VERSION ""

NS_ :

BS_:

BU_: WPC2 PSB SHVU_RR FCS vHS_B2 EMCU SLB GW_APSU GW_DLBCU RCM ARS CGW_CCU vDummy_HS_B GW_RLPSU ATS RLHV SGU PFSU GW_RRPSU ALBCU DSAU SWRC SHVU_FR RCS GW_DPSU BLTN_CAM SCM OHCL RWPC RRHV WPC HOD ASAU

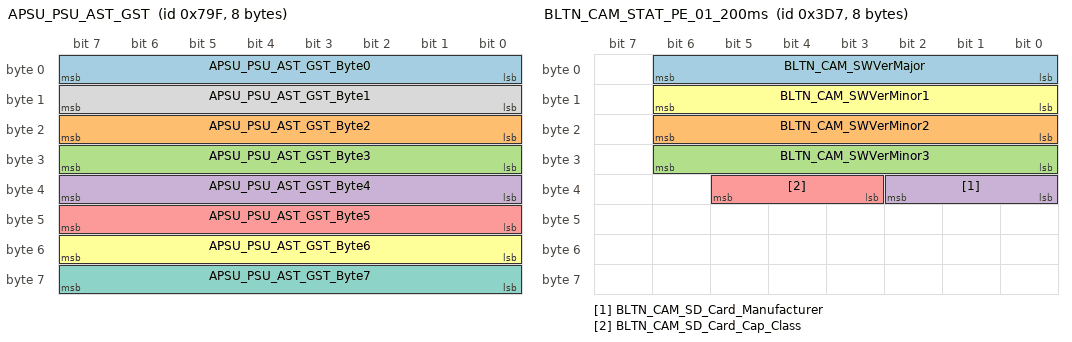
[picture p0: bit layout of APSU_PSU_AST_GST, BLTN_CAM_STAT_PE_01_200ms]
BO_ 1951 APSU_PSU_AST_GST: 8 GW_APSU
 SG_ APSU_PSU_AST_GST_Byte0 : 0|8@1+ (1,0) [0|0] ""  CGW_CCU
 SG_ APSU_PSU_AST_GST_Byte2 : 16|8@1+ (1,0) [0|0] ""  CGW_CCU
 SG_ APSU_PSU_AST_GST_Byte3 : 24|8@1+ (1,0) [0|0] ""  CGW_CCU
 SG_ APSU_PSU_AST_GST_Byte4 : 32|8@1+ (1,0) [0|0] ""  CGW_CCU
 SG_ APSU_PSU_AST_GST_Byte5 : 40|8@1+ (1,0) [0|0] ""  CGW_CCU
 SG_ APSU_PSU_AST_GST_Byte6 : 48|8@1+ (1,0) [0|0] ""  CGW_CCU
 SG_ APSU_PSU_AST_GST_Byte7 : 56|8@1+ (1,0) [0|0] ""  CGW_CCU
 SG_ APSU_PSU_AST_GST_Byte1 : 8|8@1+ (1,0) [0|0] ""  CGW_CCU

BO_ 977 SMK_13_200ms: 8 CGW_CCU
 SG_ SMK_Crc13Val : 0|8@1+ (1,0) [0|0] "0" Vector__XXX
 SG_ SMK_TlPwrOnSta : 10|2@1+ (1,0) [0|0] "" Vector__XXX
 SG_ SMK_AlvCnt13Val : 12|4@1+ (1,0) [0|0] "0" Vector__XXX
 SG_ SMK_TrmnlCtrlGrpStaBDC : 16|3@1+ (1,0) [0|0] ""  BLTN_CAM
 SG_ SMK_TrmnlCtrlStaBDC : 19|5@1+ (1,0) [0|0] "" Vector__XXX
 SG_ SMK_TrmnlCtrlGrpStaBDCEV : 24|3@1+ (1,0) [0|0] ""  BLTN_CAM
 SG_ SMK_TrmnlCtrlStaBDCEV : 27|5@1+ (1,0) [0|0] ""  BLTN_CAM
 SG_ SMK_PwrOnModeSta : 32|2@1+ (1,0) [0|0] "" Vector__XXX
 SG_ SMK_StndbyMdTmrMin : 34|6@1+ (1,0) [0|0] "" Vector__XXX
 SG_ SMK_StndbyMdTmrSec : 40|6@1+ (1,0) [0|0] "" Vector__XXX
 SG_ SMK_EVPwrOffReq : 46|2@1+ (1,0) [0|0] "" Vector__XXX
 SG_ SMK_RLHndLkSnsrSta : 48|2@1+ (1,0) [0|0] "" Vector__XXX
 SG_ SMK_RLDrHndUnLkSnsrSta : 50|2@1+ (1,0) [0|0] "" Vector__XXX
 SG_ SMK_RRDrHndLkSnsrSta : 52|2@1+ (1,0) [0|0] "" Vector__XXX
 SG_ SMK_RRDrHndUnLkSnsrSta : 54|2@1+ (1,0) [0|0] "" Vector__XXX
 SG_ SMK_MaintenanceSrvMdReq : 56|2@1+ (1,0) [0|0] "" Vector__XXX
 SG_ Auth_ISKLearnSta2 : 58|3@1+ (1,0) [0|0] "" Vector__XXX
 SG_ Fob_FoundForChargingDoor : 61|2@1+ (1,0) [0|0] "" Vector__XXX
 SG_ Fob_FoundCabinArea : 8|2@1+ (1,0) [0|0] "" Vector__XXX

BO_ 983 BLTN_CAM_STAT_PE_01_200ms: 8 BLTN_CAM
 SG_ BLTN_CAM_SWVerMajor : 0|7@1+ (1,0) [0|0] ""  CGW_CCU
 SG_ BLTN_CAM_SWVerMinor2 : 16|7@1+ (1,0) [0|0] ""  CGW_CCU
 SG_ BLTN_CAM_SWVerMinor3 : 24|7@1+ (1,0) [0|0] ""  CGW_CCU
 SG_ BLTN_CAM_SD_Card_Manufacturer : 32|3@1+ (1,0) [0|0] ""  CGW_CCU
 SG_ BLTN_CAM_SD_Card_Cap_Class : 35|3@1+ (1,1) [0|0] ""  CGW_CCU
 SG_ BLTN_CAM_SWVerMinor1 : 8|7@1+ (1,0) [0|0] ""  CGW_CCU

BO_ 981 APSS_01_200ms: 8 GW_APSU
 SG_ APSS_StExtFwdMvBtn : 0|2@1+ (1,0) [0|0] "" Vector__XXX
 SG_ APSS_StSldFwdMvBtn : 16|2@1+ (1,0) [0|0] ""  CGW_CCU
 SG_ APSS_StSldBwdMvBtn : 18|2@1+ (1,0) [0|0] ""  CGW_CCU
 SG_ APSS_StExtBwdMvBtn : 2|2@1+ (1,0) [0|0] "" Vector__XXX
 SG_ APSS_StRclFwdMvBtn : 20|2@1+ (1,0) [0|0] ""  CGW_CCU
 SG_ APSS_StRclBwdMvBtn : 22|2@1+ (1,0) [0|0] ""  CGW_CCU
 SG_ APSS_StHgtUpMvBtn : 24|2@1+ (1,0) [0|0] ""  CGW_CCU
 SG_ APSS_StHgtDnMvBtn : 26|2@1+ (1,0) [0|0] ""  CGW_CCU
 SG_ APSS_StTltUpMvBtn : 28|2@1+ (1,0) [0|0] ""  CGW_CCU
 SG_ APSS_StTltDnMvBtn : 30|2@1+ (1,0) [0|0] ""  CGW_CCU
 SG_ APSS_StHRestUpMvBtn : 32|2@1+ (1,0) [0|0] ""  CGW_CCU
 SG_ APSS_StHRestDnMvBtn : 34|2@1+ (1,0) [0|0] ""  CGW_CCU
 SG_ APSS_StHRestFwdMvBtn : 36|2@1+ (1,0) [0|0] ""  CGW_CCU
 SG_ APSS_StHRestBwdMvBtn : 38|2@1+ (1,0) [0|0] ""  CGW_CCU
 SG_ APSS_StLegUpMvBtn : 40|2@1+ (1,0) [0|0] "" Vector__XXX
 SG_ APSS_StLegDnMvBtn : 42|2@1+ (1,0) [0|0] "" Vector__XXX
 SG_ APSS_StRlxModeBtn : 44|2@1+ (1,0) [0|0] "" Vector__XXX
 SG_ APSS_StRlxReturnBtn : 46|2@1+ (1,0) [0|0] "" Vector__XXX
 SG_ APSS_StRlxTltUpMvBtn : 48|2@1+ (1,0) [0|0] "" Vector__XXX
 SG_ APSS_StRlxTltDnMvBtn : 50|2@1+ (1,0) [0|0] "" Vector__XXX
 SG_ APSS_StAutoModeEnable : 52|2@1+ (1,0) [0|0] "" Vector__XXX

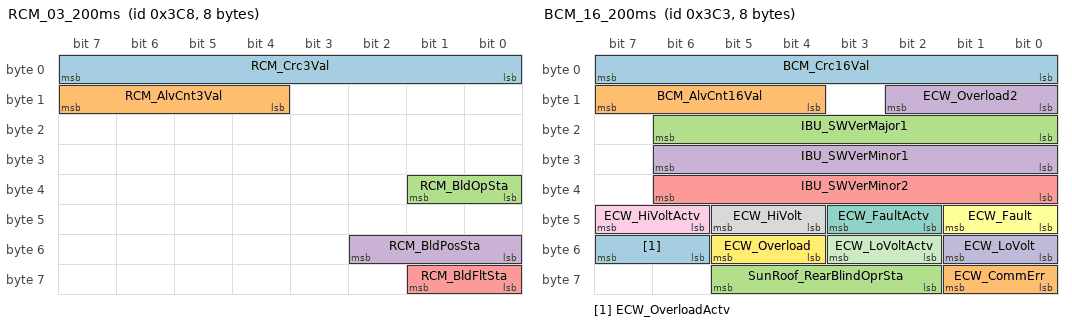
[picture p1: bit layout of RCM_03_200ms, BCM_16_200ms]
BO_ 968 RCM_03_200ms: 8 RCM
 SG_ RCM_Crc3Val : 0|8@1+ (1,0) [0|0] "" Vector__XXX
 SG_ RCM_AlvCnt3Val : 12|4@1+ (1,0) [0|0] "" Vector__XXX
 SG_ RCM_BldOpSta : 32|2@1+ (1,0) [0|0] "" Vector__XXX
 SG_ RCM_BldPosSta : 48|3@1+ (1,0) [0|0] ""  CGW_CCU,SGU
 SG_ RCM_BldFltSta : 56|2@1+ (1,0) [0|0] ""  CGW_CCU

BO_ 963 BCM_16_200ms: 8 CGW_CCU
 SG_ BCM_Crc16Val : 0|8@1+ (1,0) [0|0] "" Vector__XXX
 SG_ BCM_AlvCnt16Val : 12|4@1+ (1,0) [0|0] "" Vector__XXX
 SG_ IBU_SWVerMajor1 : 16|7@1+ (1,0) [0|0] "" Vector__XXX
 SG_ IBU_SWVerMinor1 : 24|7@1+ (1,0) [0|0] "" Vector__XXX
 SG_ IBU_SWVerMinor2 : 32|7@1+ (1,0) [0|0] "" Vector__XXX
 SG_ ECW_Fault : 40|2@1+ (1,0) [0|0] "" Vector__XXX
 SG_ ECW_FaultActv : 42|2@1+ (1,0) [0|0] "" Vector__XXX
 SG_ ECW_HiVolt : 44|2@1+ (1,0) [0|0] "" Vector__XXX
 SG_ ECW_HiVoltActv : 46|2@1+ (1,0) [0|0] "" Vector__XXX
 SG_ ECW_LoVolt : 48|2@1+ (1,0) [0|0] "" Vector__XXX
 SG_ ECW_LoVoltActv : 50|2@1+ (1,0) [0|0] "" Vector__XXX
 SG_ ECW_Overload : 52|2@1+ (1,0) [0|0] "" Vector__XXX
 SG_ ECW_OverloadActv : 54|2@1+ (1,0) [0|0] "" Vector__XXX
 SG_ ECW_CommErr : 56|2@1+ (1,0) [0|0] "" Vector__XXX
 SG_ SunRoof_RearBlindOprSta : 58|4@1+ (1,0) [0|0] ""  ATS
 SG_ ECW_Overload2 : 8|3@1+ (1,0) [0|0] "" Vector__XXX

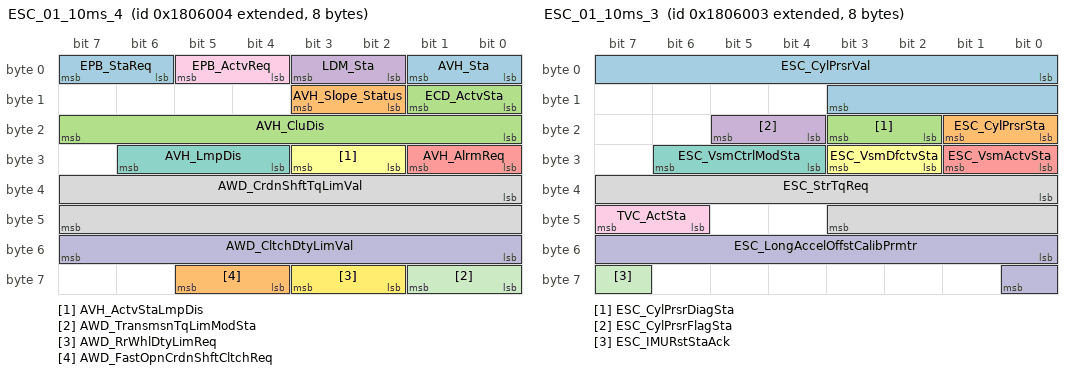
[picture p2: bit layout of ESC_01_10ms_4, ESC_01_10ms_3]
BO_ 2172674052 ESC_01_10ms_4: 8 CGW_CCU
 SG_ AVH_Sta : 0|2@1+ (1,0) [0|0] "" Vector__XXX
 SG_ AVH_Slope_Status : 10|2@1+ (1,0) [0|0] "" Vector__XXX
 SG_ AVH_CluDis : 16|8@1+ (1,0) [0|0] "" Vector__XXX
 SG_ LDM_Sta : 2|2@1+ (1,0) [0|0] "" Vector__XXX
 SG_ AVH_AlrmReq : 24|2@1+ (1,0) [0|0] "" Vector__XXX
 SG_ AVH_ActvStaLmpDis : 26|2@1+ (1,0) [0|0] "" Vector__XXX
 SG_ AVH_LmpDis : 28|3@1+ (1,0) [0|0] "" Vector__XXX
 SG_ AWD_CrdnShftTqLimVal : 32|16@1+ (1,0) [0|0] "Nm" Vector__XXX
 SG_ EPB_ActvReq : 4|2@1+ (1,0) [0|0] "" Vector__XXX
 SG_ AWD_CltchDtyLimVal : 48|8@1+ (0.390625,0) [0|0] "%" Vector__XXX
 SG_ AWD_TransmsnTqLimModSta : 56|2@1+ (1,0) [0|0] "" Vector__XXX
 SG_ AWD_RrWhlDtyLimReq : 58|2@1+ (1,0) [0|0] "" Vector__XXX
 SG_ EPB_StaReq : 6|2@1+ (1,0) [0|0] "" Vector__XXX
 SG_ AWD_FastOpnCrdnShftCltchReq : 60|2@1+ (1,0) [0|0] "" Vector__XXX
 SG_ ECD_ActvSta : 8|2@1+ (1,0) [0|0] "" Vector__XXX

BO_ 2172674051 ESC_01_10ms_3: 8 CGW_CCU
 SG_ ESC_CylPrsrVal : 0|12@1+ (0.1,0) [0|0] "Bar"  PSB
 SG_ ESC_CylPrsrSta : 16|2@1+ (1,0) [0|0] ""  PSB
 SG_ ESC_CylPrsrDiagSta : 18|2@1+ (1,0) [0|0] "" Vector__XXX
 SG_ ESC_CylPrsrFlagSta : 20|2@1+ (1,0) [0|0] "" Vector__XXX
 SG_ ESC_VsmActvSta : 24|2@1+ (1,0) [0|0] "" Vector__XXX
 SG_ ESC_VsmDfctvSta : 26|2@1+ (1,0) [0|0] "" Vector__XXX
 SG_ ESC_VsmCtrlModSta : 28|3@1+ (1,0) [0|0] "" Vector__XXX
 SG_ ESC_StrTqReq : 32|12@1+ (0.01,-20.48) [0|0] "Nm" Vector__XXX
 SG_ TVC_ActSta : 46|2@1+ (1,0) [0|0] "" Vector__XXX
 SG_ ESC_LongAccelOffstCalibPrmtr : 48|9@1+ (0.001,-0.255) [0|0] "g" Vector__XXX
 SG_ ESC_IMURstStaAck : 63|1@1+ (1,0) [0|0] "" Vector__XXX

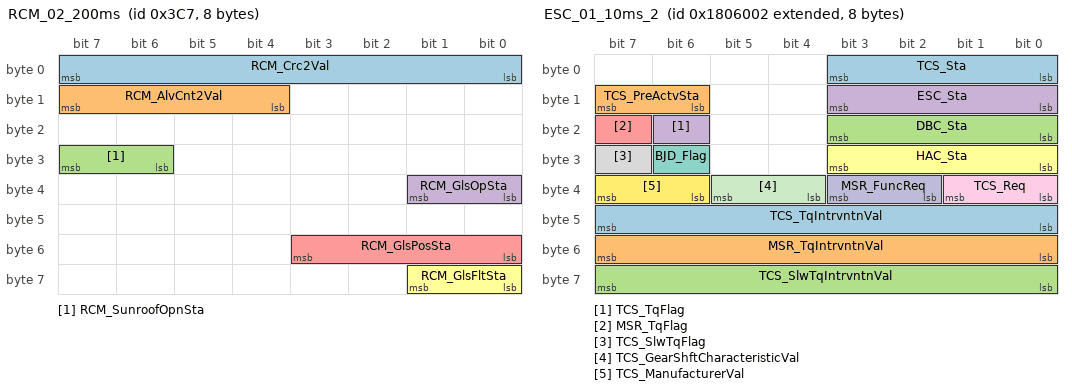
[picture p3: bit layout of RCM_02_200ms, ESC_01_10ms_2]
BO_ 967 RCM_02_200ms: 8 RCM
 SG_ RCM_Crc2Val : 0|8@1+ (1,0) [0|0] "" Vector__XXX
 SG_ RCM_AlvCnt2Val : 12|4@1+ (1,0) [0|0] "" Vector__XXX
 SG_ RCM_SunroofOpnSta : 30|2@1+ (1,0) [0|0] ""  CGW_CCU
 SG_ RCM_GlsOpSta : 32|2@1+ (1,0) [0|0] ""  CGW_CCU
 SG_ RCM_GlsPosSta : 48|4@1+ (1,0) [0|0] ""  CGW_CCU
 SG_ RCM_GlsFltSta : 56|2@1+ (1,0) [0|0] ""  CGW_CCU

BO_ 2172674050 ESC_01_10ms_2: 8 CGW_CCU
 SG_ TCS_Sta : 0|4@1+ (1,0) [0|0] "" Vector__XXX
 SG_ TCS_PreActvSta : 14|2@1+ (1,0) [0|0] "" Vector__XXX
 SG_ DBC_Sta : 16|4@1+ (1,0) [0|0] "" Vector__XXX
 SG_ TCS_TqFlag : 22|1@1+ (1,0) [0|0] "" Vector__XXX
 SG_ MSR_TqFlag : 23|1@1+ (1,0) [0|0] "" Vector__XXX
 SG_ HAC_Sta : 24|4@1+ (1,0) [0|0] "" Vector__XXX
 SG_ BJD_Flag : 30|1@1+ (1,0) [0|0] "" Vector__XXX
 SG_ TCS_SlwTqFlag : 31|1@1+ (1,0) [0|0] "" Vector__XXX
 SG_ TCS_Req : 32|2@1+ (1,0) [0|0] "" Vector__XXX
 SG_ MSR_FuncReq : 34|2@1+ (1,0) [0|0] "" Vector__XXX
 SG_ TCS_GearShftCharacteristicVal : 36|2@1+ (1,0) [0|0] "" Vector__XXX
 SG_ TCS_ManufacturerVal : 38|2@1+ (1,0) [0|0] "" Vector__XXX
 SG_ TCS_TqIntrvntnVal : 40|8@1+ (0.390625,0) [0|0] "%" Vector__XXX
 SG_ MSR_TqIntrvntnVal : 48|8@1+ (0.390625,0) [0|0] "%" Vector__XXX
 SG_ TCS_SlwTqIntrvntnVal : 56|8@1+ (0.390625,0) [0|0] "%" Vector__XXX
 SG_ ESC_Sta : 8|4@1+ (1,0) [0|0] "" Vector__XXX

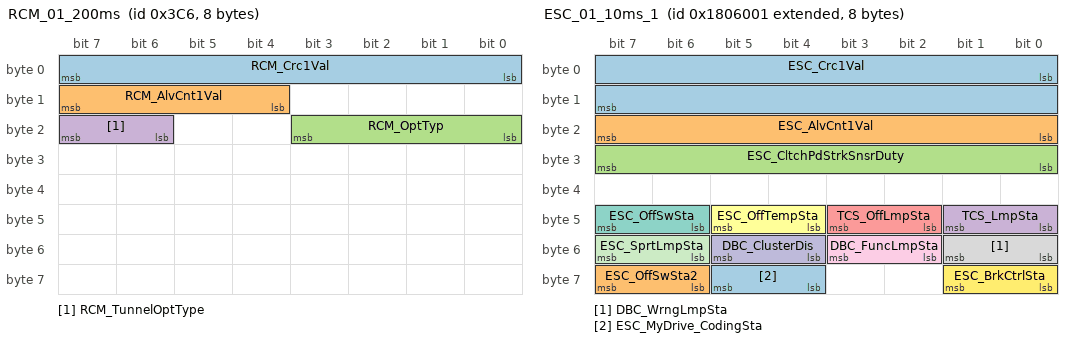
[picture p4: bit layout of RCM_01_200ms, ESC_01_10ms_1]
BO_ 966 RCM_01_200ms: 8 RCM
 SG_ RCM_Crc1Val : 0|8@1+ (1,0) [0|0] "" Vector__XXX
 SG_ RCM_AlvCnt1Val : 12|4@1+ (1,0) [0|0] "" Vector__XXX
 SG_ RCM_OptTyp : 16|4@1+ (1,0) [0|0] ""  CGW_CCU
 SG_ RCM_TunnelOptType : 22|2@1+ (1,0) [0|0] ""  CGW_CCU

BO_ 2172674049 ESC_01_10ms_1: 8 CGW_CCU
 SG_ ESC_Crc1Val : 0|16@1+ (1,0) [0|0] "" Vector__XXX
 SG_ ESC_AlvCnt1Val : 16|8@1+ (1,0) [0|0] "" Vector__XXX
 SG_ ESC_CltchPdStrkSnsrDuty : 24|8@1+ (1,0) [0|0] "%" Vector__XXX
 SG_ TCS_LmpSta : 40|2@1+ (1,0) [0|0] "" Vector__XXX
 SG_ TCS_OffLmpSta : 42|2@1+ (1,0) [0|0] "" Vector__XXX
 SG_ ESC_OffTempSta : 44|2@1+ (1,0) [0|0] "" Vector__XXX
 SG_ ESC_OffSwSta : 46|2@1+ (1,0) [0|0] "" Vector__XXX
 SG_ DBC_WrngLmpSta : 48|2@1+ (1,0) [0|0] "" Vector__XXX
 SG_ DBC_FuncLmpSta : 50|2@1+ (1,0) [0|0] "" Vector__XXX
 SG_ DBC_ClusterDis : 52|2@1+ (1,0) [0|0] "" Vector__XXX
 SG_ ESC_SprtLmpSta : 54|2@1+ (1,0) [0|0] "" Vector__XXX
 SG_ ESC_BrkCtrlSta : 56|2@1+ (1,0) [0|0] "" Vector__XXX
 SG_ ESC_MyDrive_CodingSta : 60|2@1+ (1,0) [0|0] "" Vector__XXX
 SG_ ESC_OffSwSta2 : 62|2@1+ (1,0) [0|0] "" Vector__XXX

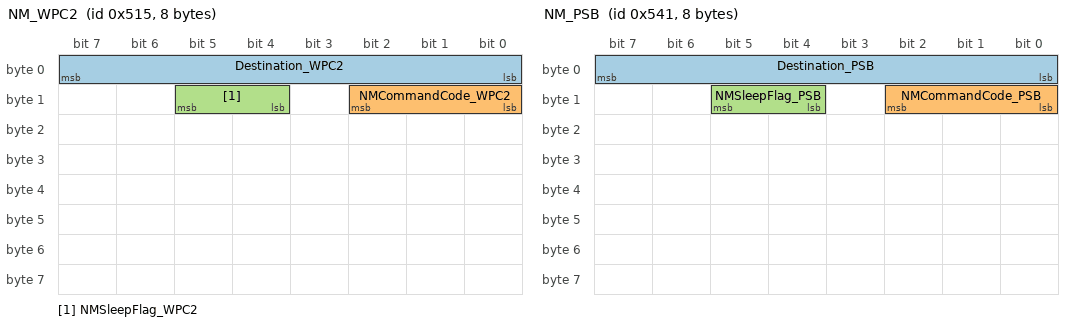
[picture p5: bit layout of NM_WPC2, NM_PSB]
BO_ 1301 NM_WPC2: 8 WPC2
 SG_ Destination_WPC2 : 0|8@1+ (1,0) [0|0] ""  PSB,SHVU_RR,FCS,vHS_B2,EMCU,SLB,GW_APSU,GW_DLBCU,RCM,ARS,CGW_CCU,vDummy_HS_B,GW_RLPSU,ATS,RLHV,SGU,PFSU,GW_RRPSU,ALBCU,DSAU,SWRC,SHVU_FR,RCS,GW_DPSU,BLTN_CAM,SCM,OHCL,RWPC,RRHV,WPC,HOD,ASAU
 SG_ NMCommandCode_WPC2 : 8|3@1+ (1,0) [0|0] ""  PSB,SHVU_RR,FCS,vHS_B2,EMCU,SLB,GW_APSU,GW_DLBCU,RCM,ARS,CGW_CCU,vDummy_HS_B,GW_RLPSU,ATS,RLHV,SGU,PFSU,GW_RRPSU,ALBCU,DSAU,SWRC,SHVU_FR,RCS,GW_DPSU,BLTN_CAM,SCM,OHCL,RWPC,RRHV,WPC,HOD,ASAU
 SG_ NMSleepFlag_WPC2 : 12|2@1+ (1,0) [0|0] ""  PSB,SHVU_RR,FCS,vHS_B2,EMCU,SLB,GW_APSU,GW_DLBCU,RCM,ARS,CGW_CCU,vDummy_HS_B,GW_RLPSU,ATS,RLHV,SGU,PFSU,GW_RRPSU,ALBCU,DSAU,SWRC,SHVU_FR,RCS,GW_DPSU,BLTN_CAM,SCM,OHCL,RWPC,RRHV,WPC,HOD,ASAU

BO_ 1345 NM_PSB: 8 PSB
 SG_ Destination_PSB : 0|8@1+ (1,0) [0|0] ""  WPC2,SHVU_RR,FCS,vHS_B2,EMCU,SLB,GW_APSU,GW_DLBCU,RCM,ARS,CGW_CCU,vDummy_HS_B,GW_RLPSU,ATS,RLHV,SGU,PFSU,GW_RRPSU,ALBCU,DSAU,SWRC,SHVU_FR,RCS,GW_DPSU,BLTN_CAM,SCM,OHCL,RWPC,RRHV,WPC,HOD,ASAU
 SG_ NMCommandCode_PSB : 8|3@1+ (1,0) [0|0] ""  WPC2,SHVU_RR,FCS,vHS_B2,EMCU,SLB,GW_APSU,GW_DLBCU,RCM,ARS,CGW_CCU,vDummy_HS_B,GW_RLPSU,ATS,RLHV,SGU,PFSU,GW_RRPSU,ALBCU,DSAU,SWRC,SHVU_FR,RCS,GW_DPSU,BLTN_CAM,SCM,OHCL,RWPC,RRHV,WPC,HOD,ASAU
 SG_ NMSleepFlag_PSB : 12|2@1+ (1,0) [0|0] ""  WPC2,SHVU_RR,FCS,vHS_B2,EMCU,SLB,GW_APSU,GW_DLBCU,RCM,ARS,CGW_CCU,vDummy_HS_B,GW_RLPSU,ATS,RLHV,SGU,PFSU,GW_RRPSU,ALBCU,DSAU,SWRC,SHVU_FR,RCS,GW_DPSU,BLTN_CAM,SCM,OHCL,RWPC,RRHV,WPC,HOD,ASAU

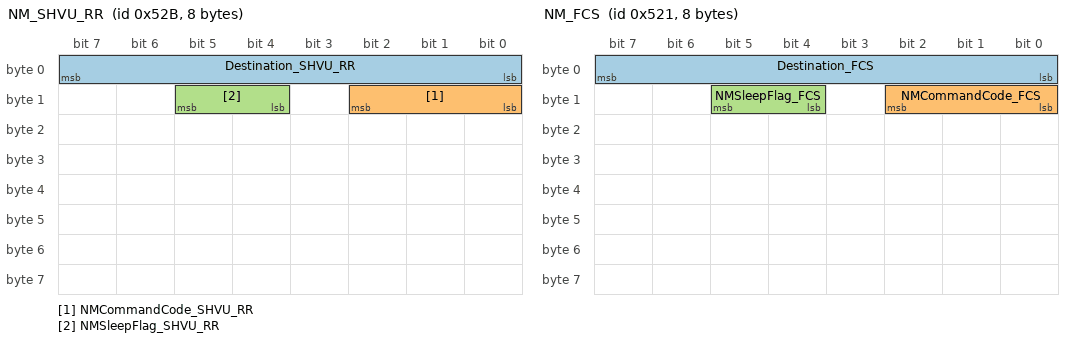
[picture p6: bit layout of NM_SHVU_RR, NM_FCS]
BO_ 1323 NM_SHVU_RR: 8 SHVU_RR
 SG_ Destination_SHVU_RR : 0|8@1+ (1,0) [0|0] ""  WPC2,PSB,FCS,vHS_B2,EMCU,SLB,GW_APSU,GW_DLBCU,RCM,ARS,CGW_CCU,vDummy_HS_B,GW_RLPSU,ATS,RLHV,SGU,PFSU,GW_RRPSU,ALBCU,DSAU,SWRC,SHVU_FR,RCS,GW_DPSU,BLTN_CAM,SCM,OHCL,RWPC,RRHV,WPC,HOD,ASAU
 SG_ NMCommandCode_SHVU_RR : 8|3@1+ (1,0) [0|0] ""  WPC2,PSB,FCS,vHS_B2,EMCU,SLB,GW_APSU,GW_DLBCU,RCM,ARS,CGW_CCU,vDummy_HS_B,GW_RLPSU,ATS,RLHV,SGU,PFSU,GW_RRPSU,ALBCU,DSAU,SWRC,SHVU_FR,RCS,GW_DPSU,BLTN_CAM,SCM,OHCL,RWPC,RRHV,WPC,HOD,ASAU
 SG_ NMSleepFlag_SHVU_RR : 12|2@1+ (1,0) [0|0] ""  WPC2,PSB,FCS,vHS_B2,EMCU,SLB,GW_APSU,GW_DLBCU,RCM,ARS,CGW_CCU,vDummy_HS_B,GW_RLPSU,ATS,RLHV,SGU,PFSU,GW_RRPSU,ALBCU,DSAU,SWRC,SHVU_FR,RCS,GW_DPSU,BLTN_CAM,SCM,OHCL,RWPC,RRHV,WPC,HOD,ASAU

BO_ 1313 NM_FCS: 8 FCS
 SG_ Destination_FCS : 0|8@1+ (1,0) [0|0] ""  WPC2,PSB,SHVU_RR,vHS_B2,EMCU,SLB,GW_APSU,GW_DLBCU,RCM,ARS,CGW_CCU,vDummy_HS_B,GW_RLPSU,ATS,RLHV,SGU,PFSU,GW_RRPSU,ALBCU,DSAU,SWRC,SHVU_FR,RCS,GW_DPSU,BLTN_CAM,SCM,OHCL,RWPC,RRHV,WPC,HOD,ASAU
 SG_ NMCommandCode_FCS : 8|3@1+ (1,0) [0|0] ""  WPC2,PSB,SHVU_RR,vHS_B2,EMCU,SLB,GW_APSU,GW_DLBCU,RCM,ARS,CGW_CCU,vDummy_HS_B,GW_RLPSU,ATS,RLHV,SGU,PFSU,GW_RRPSU,ALBCU,DSAU,SWRC,SHVU_FR,RCS,GW_DPSU,BLTN_CAM,SCM,OHCL,RWPC,RRHV,WPC,HOD,ASAU
 SG_ NMSleepFlag_FCS : 12|2@1+ (1,0) [0|0] ""  WPC2,PSB,SHVU_RR,vHS_B2,EMCU,SLB,GW_APSU,GW_DLBCU,RCM,ARS,CGW_CCU,vDummy_HS_B,GW_RLPSU,ATS,RLHV,SGU,PFSU,GW_RRPSU,ALBCU,DSAU,SWRC,SHVU_FR,RCS,GW_DPSU,BLTN_CAM,SCM,OHCL,RWPC,RRHV,WPC,HOD,ASAU

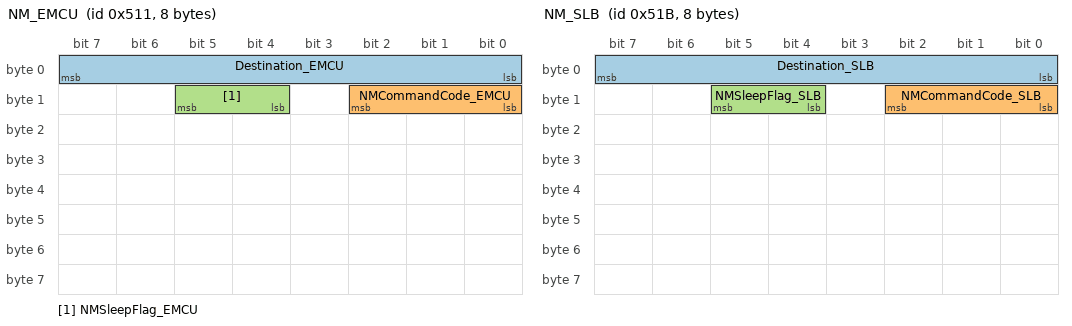
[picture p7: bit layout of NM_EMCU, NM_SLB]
BO_ 1297 NM_EMCU: 8 EMCU
 SG_ Destination_EMCU : 0|8@1+ (1,0) [0|0] ""  WPC2,PSB,SHVU_RR,FCS,vHS_B2,SLB,GW_APSU,GW_DLBCU,RCM,ARS,CGW_CCU,vDummy_HS_B,GW_RLPSU,ATS,RLHV,SGU,PFSU,GW_RRPSU,ALBCU,DSAU,SWRC,SHVU_FR,RCS,GW_DPSU,BLTN_CAM,SCM,OHCL,RWPC,RRHV,WPC,HOD,ASAU
 SG_ NMCommandCode_EMCU : 8|3@1+ (1,0) [0|0] ""  WPC2,PSB,SHVU_RR,FCS,vHS_B2,SLB,GW_APSU,GW_DLBCU,RCM,ARS,CGW_CCU,vDummy_HS_B,GW_RLPSU,ATS,RLHV,SGU,PFSU,GW_RRPSU,ALBCU,DSAU,SWRC,SHVU_FR,RCS,GW_DPSU,BLTN_CAM,SCM,OHCL,RWPC,RRHV,WPC,HOD,ASAU
 SG_ NMSleepFlag_EMCU : 12|2@1+ (1,0) [0|0] ""  WPC2,PSB,SHVU_RR,FCS,vHS_B2,SLB,GW_APSU,GW_DLBCU,RCM,ARS,CGW_CCU,vDummy_HS_B,GW_RLPSU,ATS,RLHV,SGU,PFSU,GW_RRPSU,ALBCU,DSAU,SWRC,SHVU_FR,RCS,GW_DPSU,BLTN_CAM,SCM,OHCL,RWPC,RRHV,WPC,HOD,ASAU

BO_ 1307 NM_SLB: 8 SLB
 SG_ Destination_SLB : 0|8@1+ (1,0) [0|0] ""  WPC2,PSB,SHVU_RR,FCS,vHS_B2,EMCU,GW_APSU,GW_DLBCU,RCM,ARS,CGW_CCU,vDummy_HS_B,GW_RLPSU,ATS,RLHV,SGU,PFSU,GW_RRPSU,ALBCU,DSAU,SWRC,SHVU_FR,RCS,GW_DPSU,BLTN_CAM,SCM,OHCL,RWPC,RRHV,WPC,HOD,ASAU
 SG_ NMCommandCode_SLB : 8|3@1+ (1,0) [0|0] ""  WPC2,PSB,SHVU_RR,FCS,vHS_B2,EMCU,GW_APSU,GW_DLBCU,RCM,ARS,CGW_CCU,vDummy_HS_B,GW_RLPSU,ATS,RLHV,SGU,PFSU,GW_RRPSU,ALBCU,DSAU,SWRC,SHVU_FR,RCS,GW_DPSU,BLTN_CAM,SCM,OHCL,RWPC,RRHV,WPC,HOD,ASAU
 SG_ NMSleepFlag_SLB : 12|2@1+ (1,0) [0|0] ""  WPC2,PSB,SHVU_RR,FCS,vHS_B2,EMCU,GW_APSU,GW_DLBCU,RCM,ARS,CGW_CCU,vDummy_HS_B,GW_RLPSU,ATS,RLHV,SGU,PFSU,GW_RRPSU,ALBCU,DSAU,SWRC,SHVU_FR,RCS,GW_DPSU,BLTN_CAM,SCM,OHCL,RWPC,RRHV,WPC,HOD,ASAU

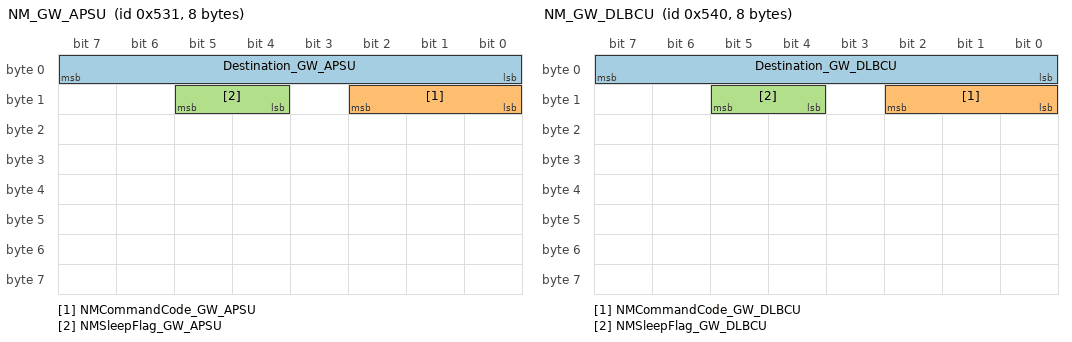
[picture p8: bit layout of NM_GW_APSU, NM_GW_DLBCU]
BO_ 1329 NM_GW_APSU: 8 GW_APSU
 SG_ Destination_GW_APSU : 0|8@1+ (1,0) [0|0] ""  WPC2,PSB,SHVU_RR,FCS,vHS_B2,EMCU,SLB,GW_DLBCU,RCM,ARS,CGW_CCU,vDummy_HS_B,GW_RLPSU,ATS,RLHV,SGU,PFSU,GW_RRPSU,ALBCU,DSAU,SWRC,SHVU_FR,RCS,GW_DPSU,BLTN_CAM,SCM,OHCL,RWPC,RRHV,WPC,HOD,ASAU
 SG_ NMCommandCode_GW_APSU : 8|3@1+ (1,0) [0|0] ""  WPC2,PSB,SHVU_RR,FCS,vHS_B2,EMCU,SLB,GW_DLBCU,RCM,ARS,CGW_CCU,vDummy_HS_B,GW_RLPSU,ATS,RLHV,SGU,PFSU,GW_RRPSU,ALBCU,DSAU,SWRC,SHVU_FR,RCS,GW_DPSU,BLTN_CAM,SCM,OHCL,RWPC,RRHV,WPC,HOD,ASAU
 SG_ NMSleepFlag_GW_APSU : 12|2@1+ (1,0) [0|0] ""  WPC2,PSB,SHVU_RR,FCS,vHS_B2,EMCU,SLB,GW_DLBCU,RCM,ARS,CGW_CCU,vDummy_HS_B,GW_RLPSU,ATS,RLHV,SGU,PFSU,GW_RRPSU,ALBCU,DSAU,SWRC,SHVU_FR,RCS,GW_DPSU,BLTN_CAM,SCM,OHCL,RWPC,RRHV,WPC,HOD,ASAU

BO_ 1344 NM_GW_DLBCU: 8 GW_DLBCU
 SG_ Destination_GW_DLBCU : 0|8@1+ (1,0) [0|0] ""  WPC2,PSB,SHVU_RR,FCS,vHS_B2,EMCU,SLB,GW_APSU,RCM,ARS,CGW_CCU,vDummy_HS_B,GW_RLPSU,ATS,RLHV,SGU,PFSU,GW_RRPSU,ALBCU,DSAU,SWRC,SHVU_FR,RCS,GW_DPSU,BLTN_CAM,SCM,OHCL,RWPC,RRHV,WPC,HOD,ASAU
 SG_ NMCommandCode_GW_DLBCU : 8|3@1+ (1,0) [0|0] ""  WPC2,PSB,SHVU_RR,FCS,vHS_B2,EMCU,SLB,GW_APSU,RCM,ARS,CGW_CCU,vDummy_HS_B,GW_RLPSU,ATS,RLHV,SGU,PFSU,GW_RRPSU,ALBCU,DSAU,SWRC,SHVU_FR,RCS,GW_DPSU,BLTN_CAM,SCM,OHCL,RWPC,RRHV,WPC,HOD,ASAU
 SG_ NMSleepFlag_GW_DLBCU : 12|2@1+ (1,0) [0|0] ""  WPC2,PSB,SHVU_RR,FCS,vHS_B2,EMCU,SLB,GW_APSU,RCM,ARS,CGW_CCU,vDummy_HS_B,GW_RLPSU,ATS,RLHV,SGU,PFSU,GW_RRPSU,ALBCU,DSAU,SWRC,SHVU_FR,RCS,GW_DPSU,BLTN_CAM,SCM,OHCL,RWPC,RRHV,WPC,HOD,ASAU

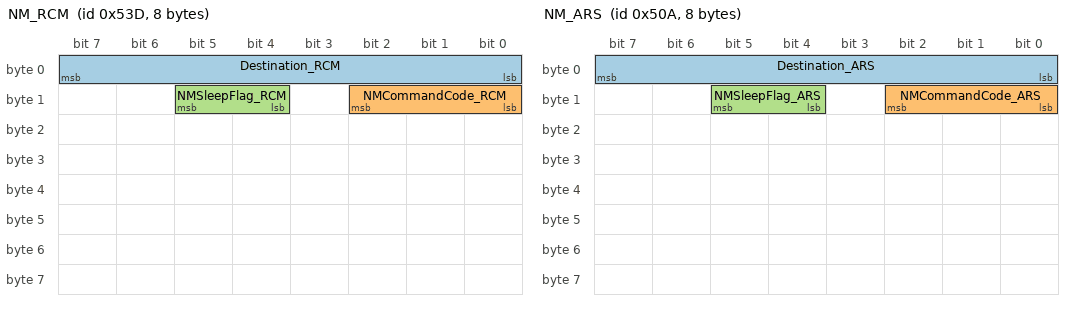
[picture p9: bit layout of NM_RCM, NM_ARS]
BO_ 1341 NM_RCM: 8 RCM
 SG_ Destination_RCM : 0|8@1+ (1,0) [0|0] ""  WPC2,PSB,SHVU_RR,FCS,vHS_B2,EMCU,SLB,GW_APSU,GW_DLBCU,ARS,CGW_CCU,vDummy_HS_B,GW_RLPSU,ATS,RLHV,SGU,PFSU,GW_RRPSU,ALBCU,DSAU,SWRC,SHVU_FR,RCS,GW_DPSU,BLTN_CAM,SCM,OHCL,RWPC,RRHV,WPC,HOD,ASAU
 SG_ NMCommandCode_RCM : 8|3@1+ (1,0) [0|0] ""  WPC2,PSB,SHVU_RR,FCS,vHS_B2,EMCU,SLB,GW_APSU,GW_DLBCU,ARS,CGW_CCU,vDummy_HS_B,GW_RLPSU,ATS,RLHV,SGU,PFSU,GW_RRPSU,ALBCU,DSAU,SWRC,SHVU_FR,RCS,GW_DPSU,BLTN_CAM,SCM,OHCL,RWPC,RRHV,WPC,HOD,ASAU
 SG_ NMSleepFlag_RCM : 12|2@1+ (1,0) [0|0] ""  WPC2,PSB,SHVU_RR,FCS,vHS_B2,EMCU,SLB,GW_APSU,GW_DLBCU,ARS,CGW_CCU,vDummy_HS_B,GW_RLPSU,ATS,RLHV,SGU,PFSU,GW_RRPSU,ALBCU,DSAU,SWRC,SHVU_FR,RCS,GW_DPSU,BLTN_CAM,SCM,OHCL,RWPC,RRHV,WPC,HOD,ASAU

BO_ 1290 NM_ARS: 8 ARS
 SG_ Destination_ARS : 0|8@1+ (1,0) [0|0] ""  WPC2,PSB,SHVU_RR,FCS,vHS_B2,EMCU,SLB,GW_APSU,GW_DLBCU,RCM,CGW_CCU,vDummy_HS_B,GW_RLPSU,ATS,RLHV,SGU,PFSU,GW_RRPSU,ALBCU,DSAU,SWRC,SHVU_FR,RCS,GW_DPSU,BLTN_CAM,SCM,OHCL,RWPC,RRHV,WPC,HOD,ASAU
 SG_ NMCommandCode_ARS : 8|3@1+ (1,0) [0|0] ""  WPC2,PSB,SHVU_RR,FCS,vHS_B2,EMCU,SLB,GW_APSU,GW_DLBCU,RCM,CGW_CCU,vDummy_HS_B,GW_RLPSU,ATS,RLHV,SGU,PFSU,GW_RRPSU,ALBCU,DSAU,SWRC,SHVU_FR,RCS,GW_DPSU,BLTN_CAM,SCM,OHCL,RWPC,RRHV,WPC,HOD,ASAU
 SG_ NMSleepFlag_ARS : 12|2@1+ (1,0) [0|0] ""  WPC2,PSB,SHVU_RR,FCS,vHS_B2,EMCU,SLB,GW_APSU,GW_DLBCU,RCM,CGW_CCU,vDummy_HS_B,GW_RLPSU,ATS,RLHV,SGU,PFSU,GW_RRPSU,ALBCU,DSAU,SWRC,SHVU_FR,RCS,GW_DPSU,BLTN_CAM,SCM,OHCL,RWPC,RRHV,WPC,HOD,ASAU

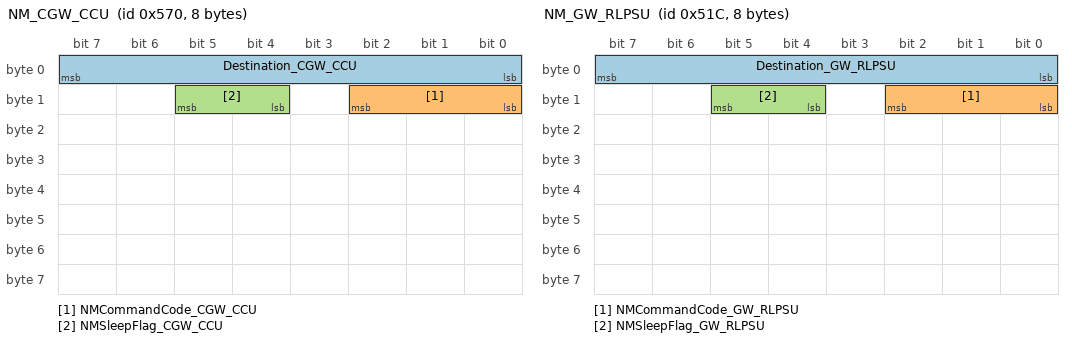
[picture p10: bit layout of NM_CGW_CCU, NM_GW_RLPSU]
BO_ 1392 NM_CGW_CCU: 8 CGW_CCU
 SG_ Destination_CGW_CCU : 0|8@1+ (1,0) [0|0] ""  WPC2,PSB,SHVU_RR,FCS,vHS_B2,EMCU,SLB,GW_APSU,GW_DLBCU,RCM,ARS,vDummy_HS_B,GW_RLPSU,ATS,RLHV,SGU,PFSU,GW_RRPSU,ALBCU,DSAU,SWRC,SHVU_FR,RCS,GW_DPSU,BLTN_CAM,SCM,OHCL,RWPC,RRHV,WPC,HOD,ASAU
 SG_ NMCommandCode_CGW_CCU : 8|3@1+ (1,0) [0|0] ""  WPC2,PSB,SHVU_RR,FCS,vHS_B2,EMCU,SLB,GW_APSU,GW_DLBCU,RCM,ARS,vDummy_HS_B,GW_RLPSU,ATS,RLHV,SGU,PFSU,GW_RRPSU,ALBCU,DSAU,SWRC,SHVU_FR,RCS,GW_DPSU,BLTN_CAM,SCM,OHCL,RWPC,RRHV,WPC,HOD,ASAU
 SG_ NMSleepFlag_CGW_CCU : 12|2@1+ (1,0) [0|0] ""  WPC2,PSB,SHVU_RR,FCS,vHS_B2,EMCU,SLB,GW_APSU,GW_DLBCU,RCM,ARS,vDummy_HS_B,GW_RLPSU,ATS,RLHV,SGU,PFSU,GW_RRPSU,ALBCU,DSAU,SWRC,SHVU_FR,RCS,GW_DPSU,BLTN_CAM,SCM,OHCL,RWPC,RRHV,WPC,HOD,ASAU

BO_ 1308 NM_GW_RLPSU: 8 GW_RLPSU
 SG_ Destination_GW_RLPSU : 0|8@1+ (1,0) [0|0] ""  WPC2,PSB,SHVU_RR,FCS,vHS_B2,EMCU,SLB,GW_APSU,GW_DLBCU,RCM,ARS,CGW_CCU,vDummy_HS_B,ATS,RLHV,SGU,PFSU,GW_RRPSU,ALBCU,DSAU,SWRC,SHVU_FR,RCS,GW_DPSU,BLTN_CAM,SCM,OHCL,RWPC,RRHV,WPC,HOD,ASAU
 SG_ NMCommandCode_GW_RLPSU : 8|3@1+ (1,0) [0|0] ""  WPC2,PSB,SHVU_RR,FCS,vHS_B2,EMCU,SLB,GW_APSU,GW_DLBCU,RCM,ARS,CGW_CCU,vDummy_HS_B,ATS,RLHV,SGU,PFSU,GW_RRPSU,ALBCU,DSAU,SWRC,SHVU_FR,RCS,GW_DPSU,BLTN_CAM,SCM,OHCL,RWPC,RRHV,WPC,HOD,ASAU
 SG_ NMSleepFlag_GW_RLPSU : 12|2@1+ (1,0) [0|0] ""  WPC2,PSB,SHVU_RR,FCS,vHS_B2,EMCU,SLB,GW_APSU,GW_DLBCU,RCM,ARS,CGW_CCU,vDummy_HS_B,ATS,RLHV,SGU,PFSU,GW_RRPSU,ALBCU,DSAU,SWRC,SHVU_FR,RCS,GW_DPSU,BLTN_CAM,SCM,OHCL,RWPC,RRHV,WPC,HOD,ASAU

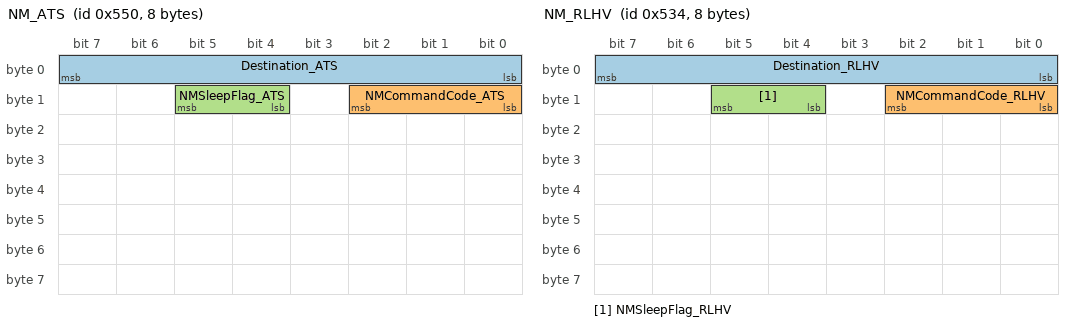
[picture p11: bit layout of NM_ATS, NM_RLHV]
BO_ 1360 NM_ATS: 8 ATS
 SG_ Destination_ATS : 0|8@1+ (1,0) [0|0] ""  WPC2,PSB,SHVU_RR,FCS,vHS_B2,EMCU,SLB,GW_APSU,GW_DLBCU,RCM,ARS,CGW_CCU,vDummy_HS_B,GW_RLPSU,RLHV,SGU,PFSU,GW_RRPSU,ALBCU,DSAU,SWRC,SHVU_FR,RCS,GW_DPSU,BLTN_CAM,SCM,OHCL,RWPC,RRHV,WPC,HOD,ASAU
 SG_ NMCommandCode_ATS : 8|3@1+ (1,0) [0|0] ""  WPC2,PSB,SHVU_RR,FCS,vHS_B2,EMCU,SLB,GW_APSU,GW_DLBCU,RCM,ARS,CGW_CCU,vDummy_HS_B,GW_RLPSU,RLHV,SGU,PFSU,GW_RRPSU,ALBCU,DSAU,SWRC,SHVU_FR,RCS,GW_DPSU,BLTN_CAM,SCM,OHCL,RWPC,RRHV,WPC,HOD,ASAU
 SG_ NMSleepFlag_ATS : 12|2@1+ (1,0) [0|0] ""  WPC2,PSB,SHVU_RR,FCS,vHS_B2,EMCU,SLB,GW_APSU,GW_DLBCU,RCM,ARS,CGW_CCU,vDummy_HS_B,GW_RLPSU,RLHV,SGU,PFSU,GW_RRPSU,ALBCU,DSAU,SWRC,SHVU_FR,RCS,GW_DPSU,BLTN_CAM,SCM,OHCL,RWPC,RRHV,WPC,HOD,ASAU

BO_ 1332 NM_RLHV: 8 RLHV
 SG_ Destination_RLHV : 0|8@1+ (1,0) [0|0] ""  WPC2,PSB,SHVU_RR,FCS,vHS_B2,EMCU,SLB,GW_APSU,GW_DLBCU,RCM,ARS,CGW_CCU,vDummy_HS_B,GW_RLPSU,ATS,SGU,PFSU,GW_RRPSU,ALBCU,DSAU,SWRC,SHVU_FR,RCS,GW_DPSU,BLTN_CAM,SCM,OHCL,RWPC,RRHV,WPC,HOD,ASAU
 SG_ NMCommandCode_RLHV : 8|3@1+ (1,0) [0|0] ""  WPC2,PSB,SHVU_RR,FCS,vHS_B2,EMCU,SLB,GW_APSU,GW_DLBCU,RCM,ARS,CGW_CCU,vDummy_HS_B,GW_RLPSU,ATS,SGU,PFSU,GW_RRPSU,ALBCU,DSAU,SWRC,SHVU_FR,RCS,GW_DPSU,BLTN_CAM,SCM,OHCL,RWPC,RRHV,WPC,HOD,ASAU
 SG_ NMSleepFlag_RLHV : 12|2@1+ (1,0) [0|0] ""  WPC2,PSB,SHVU_RR,FCS,vHS_B2,EMCU,SLB,GW_APSU,GW_DLBCU,RCM,ARS,CGW_CCU,vDummy_HS_B,GW_RLPSU,ATS,SGU,PFSU,GW_RRPSU,ALBCU,DSAU,SWRC,SHVU_FR,RCS,GW_DPSU,BLTN_CAM,SCM,OHCL,RWPC,RRHV,WPC,HOD,ASAU

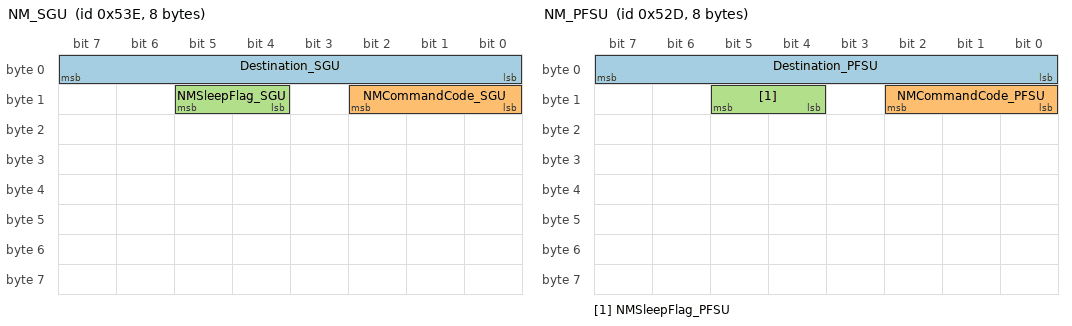
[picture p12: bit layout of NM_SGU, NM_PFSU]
BO_ 1342 NM_SGU: 8 SGU
 SG_ Destination_SGU : 0|8@1+ (1,0) [0|0] ""  WPC2,PSB,SHVU_RR,FCS,vHS_B2,EMCU,SLB,GW_APSU,GW_DLBCU,RCM,ARS,CGW_CCU,vDummy_HS_B,GW_RLPSU,ATS,RLHV,PFSU,GW_RRPSU,ALBCU,DSAU,SWRC,SHVU_FR,RCS,GW_DPSU,BLTN_CAM,SCM,OHCL,RWPC,RRHV,WPC,HOD,ASAU
 SG_ NMCommandCode_SGU : 8|3@1+ (1,0) [0|0] ""  WPC2,PSB,SHVU_RR,FCS,vHS_B2,EMCU,SLB,GW_APSU,GW_DLBCU,RCM,ARS,CGW_CCU,vDummy_HS_B,GW_RLPSU,ATS,RLHV,PFSU,GW_RRPSU,ALBCU,DSAU,SWRC,SHVU_FR,RCS,GW_DPSU,BLTN_CAM,SCM,OHCL,RWPC,RRHV,WPC,HOD,ASAU
 SG_ NMSleepFlag_SGU : 12|2@1+ (1,0) [0|0] ""  WPC2,PSB,SHVU_RR,FCS,vHS_B2,EMCU,SLB,GW_APSU,GW_DLBCU,RCM,ARS,CGW_CCU,vDummy_HS_B,GW_RLPSU,ATS,RLHV,PFSU,GW_RRPSU,ALBCU,DSAU,SWRC,SHVU_FR,RCS,GW_DPSU,BLTN_CAM,SCM,OHCL,RWPC,RRHV,WPC,HOD,ASAU

BO_ 1325 NM_PFSU: 8 PFSU
 SG_ Destination_PFSU : 0|8@1+ (1,0) [0|0] ""  WPC2,PSB,SHVU_RR,FCS,vHS_B2,EMCU,SLB,GW_APSU,GW_DLBCU,RCM,ARS,CGW_CCU,vDummy_HS_B,GW_RLPSU,ATS,RLHV,SGU,GW_RRPSU,ALBCU,DSAU,SWRC,SHVU_FR,RCS,GW_DPSU,BLTN_CAM,SCM,OHCL,RWPC,RRHV,WPC,HOD,ASAU
 SG_ NMCommandCode_PFSU : 8|3@1+ (1,0) [0|0] ""  WPC2,PSB,SHVU_RR,FCS,vHS_B2,EMCU,SLB,GW_APSU,GW_DLBCU,RCM,ARS,CGW_CCU,vDummy_HS_B,GW_RLPSU,ATS,RLHV,SGU,GW_RRPSU,ALBCU,DSAU,SWRC,SHVU_FR,RCS,GW_DPSU,BLTN_CAM,SCM,OHCL,RWPC,RRHV,WPC,HOD,ASAU
 SG_ NMSleepFlag_PFSU : 12|2@1+ (1,0) [0|0] ""  WPC2,PSB,SHVU_RR,FCS,vHS_B2,EMCU,SLB,GW_APSU,GW_DLBCU,RCM,ARS,CGW_CCU,vDummy_HS_B,GW_RLPSU,ATS,RLHV,SGU,GW_RRPSU,ALBCU,DSAU,SWRC,SHVU_FR,RCS,GW_DPSU,BLTN_CAM,SCM,OHCL,RWPC,RRHV,WPC,HOD,ASAU

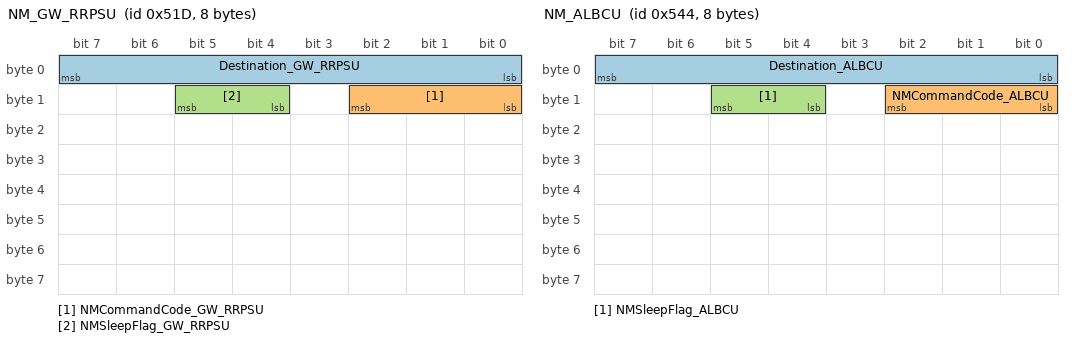
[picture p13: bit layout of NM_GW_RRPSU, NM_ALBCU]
BO_ 1309 NM_GW_RRPSU: 8 GW_RRPSU
 SG_ Destination_GW_RRPSU : 0|8@1+ (1,0) [0|0] ""  WPC2,PSB,SHVU_RR,FCS,vHS_B2,EMCU,SLB,GW_APSU,GW_DLBCU,RCM,ARS,CGW_CCU,vDummy_HS_B,GW_RLPSU,ATS,RLHV,SGU,PFSU,ALBCU,DSAU,SWRC,SHVU_FR,RCS,GW_DPSU,BLTN_CAM,SCM,OHCL,RWPC,RRHV,WPC,HOD,ASAU
 SG_ NMCommandCode_GW_RRPSU : 8|3@1+ (1,0) [0|0] ""  WPC2,PSB,SHVU_RR,FCS,vHS_B2,EMCU,SLB,GW_APSU,GW_DLBCU,RCM,ARS,CGW_CCU,vDummy_HS_B,GW_RLPSU,ATS,RLHV,SGU,PFSU,ALBCU,DSAU,SWRC,SHVU_FR,RCS,GW_DPSU,BLTN_CAM,SCM,OHCL,RWPC,RRHV,WPC,HOD,ASAU
 SG_ NMSleepFlag_GW_RRPSU : 12|2@1+ (1,0) [0|0] ""  WPC2,PSB,SHVU_RR,FCS,vHS_B2,EMCU,SLB,GW_APSU,GW_DLBCU,RCM,ARS,CGW_CCU,vDummy_HS_B,GW_RLPSU,ATS,RLHV,SGU,PFSU,ALBCU,DSAU,SWRC,SHVU_FR,RCS,GW_DPSU,BLTN_CAM,SCM,OHCL,RWPC,RRHV,WPC,HOD,ASAU

BO_ 1348 NM_ALBCU: 8 ALBCU
 SG_ Destination_ALBCU : 0|8@1+ (1,0) [0|0] ""  WPC2,PSB,SHVU_RR,FCS,vHS_B2,EMCU,SLB,GW_APSU,GW_DLBCU,RCM,ARS,CGW_CCU,vDummy_HS_B,GW_RLPSU,ATS,RLHV,SGU,PFSU,GW_RRPSU,DSAU,SWRC,SHVU_FR,RCS,GW_DPSU,BLTN_CAM,SCM,OHCL,RWPC,RRHV,WPC,HOD,ASAU
 SG_ NMCommandCode_ALBCU : 8|3@1+ (1,0) [0|0] ""  WPC2,PSB,SHVU_RR,FCS,vHS_B2,EMCU,SLB,GW_APSU,GW_DLBCU,RCM,ARS,CGW_CCU,vDummy_HS_B,GW_RLPSU,ATS,RLHV,SGU,PFSU,GW_RRPSU,DSAU,SWRC,SHVU_FR,RCS,GW_DPSU,BLTN_CAM,SCM,OHCL,RWPC,RRHV,WPC,HOD,ASAU
 SG_ NMSleepFlag_ALBCU : 12|2@1+ (1,0) [0|0] ""  WPC2,PSB,SHVU_RR,FCS,vHS_B2,EMCU,SLB,GW_APSU,GW_DLBCU,RCM,ARS,CGW_CCU,vDummy_HS_B,GW_RLPSU,ATS,RLHV,SGU,PFSU,GW_RRPSU,DSAU,SWRC,SHVU_FR,RCS,GW_DPSU,BLTN_CAM,SCM,OHCL,RWPC,RRHV,WPC,HOD,ASAU

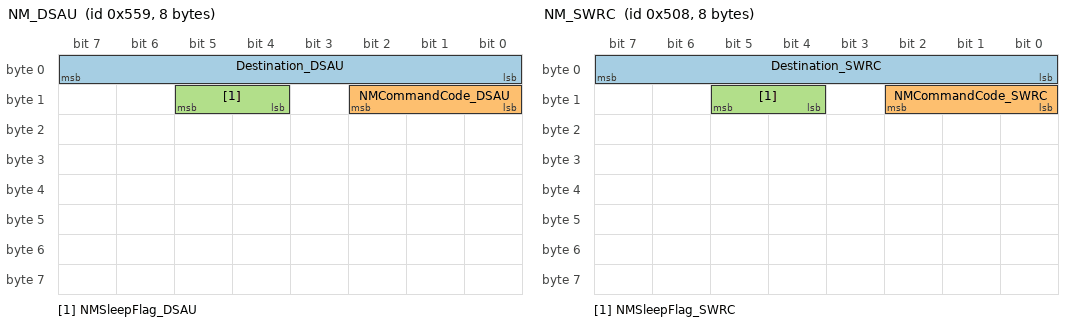
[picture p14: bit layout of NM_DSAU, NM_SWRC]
BO_ 1369 NM_DSAU: 8 DSAU
 SG_ Destination_DSAU : 0|8@1+ (1,0) [0|0] ""  WPC2,PSB,SHVU_RR,FCS,vHS_B2,EMCU,SLB,GW_APSU,GW_DLBCU,RCM,ARS,CGW_CCU,vDummy_HS_B,GW_RLPSU,ATS,RLHV,SGU,PFSU,GW_RRPSU,ALBCU,SWRC,SHVU_FR,RCS,GW_DPSU,BLTN_CAM,SCM,OHCL,RWPC,RRHV,WPC,HOD,ASAU
 SG_ NMCommandCode_DSAU : 8|3@1+ (1,0) [0|0] ""  WPC2,PSB,SHVU_RR,FCS,vHS_B2,EMCU,SLB,GW_APSU,GW_DLBCU,RCM,ARS,CGW_CCU,vDummy_HS_B,GW_RLPSU,ATS,RLHV,SGU,PFSU,GW_RRPSU,ALBCU,SWRC,SHVU_FR,RCS,GW_DPSU,BLTN_CAM,SCM,OHCL,RWPC,RRHV,WPC,HOD,ASAU
 SG_ NMSleepFlag_DSAU : 12|2@1+ (1,0) [0|0] ""  WPC2,PSB,SHVU_RR,FCS,vHS_B2,EMCU,SLB,GW_APSU,GW_DLBCU,RCM,ARS,CGW_CCU,vDummy_HS_B,GW_RLPSU,ATS,RLHV,SGU,PFSU,GW_RRPSU,ALBCU,SWRC,SHVU_FR,RCS,GW_DPSU,BLTN_CAM,SCM,OHCL,RWPC,RRHV,WPC,HOD,ASAU

BO_ 1288 NM_SWRC: 8 SWRC
 SG_ Destination_SWRC : 0|8@1+ (1,0) [0|0] ""  WPC2,PSB,SHVU_RR,FCS,vHS_B2,EMCU,SLB,GW_APSU,GW_DLBCU,RCM,ARS,CGW_CCU,vDummy_HS_B,GW_RLPSU,ATS,RLHV,SGU,PFSU,GW_RRPSU,ALBCU,DSAU,SHVU_FR,RCS,GW_DPSU,BLTN_CAM,SCM,OHCL,RWPC,RRHV,WPC,HOD,ASAU
 SG_ NMCommandCode_SWRC : 8|3@1+ (1,0) [0|0] ""  WPC2,PSB,SHVU_RR,FCS,vHS_B2,EMCU,SLB,GW_APSU,GW_DLBCU,RCM,ARS,CGW_CCU,vDummy_HS_B,GW_RLPSU,ATS,RLHV,SGU,PFSU,GW_RRPSU,ALBCU,DSAU,SHVU_FR,RCS,GW_DPSU,BLTN_CAM,SCM,OHCL,RWPC,RRHV,WPC,HOD,ASAU
 SG_ NMSleepFlag_SWRC : 12|2@1+ (1,0) [0|0] ""  WPC2,PSB,SHVU_RR,FCS,vHS_B2,EMCU,SLB,GW_APSU,GW_DLBCU,RCM,ARS,CGW_CCU,vDummy_HS_B,GW_RLPSU,ATS,RLHV,SGU,PFSU,GW_RRPSU,ALBCU,DSAU,SHVU_FR,RCS,GW_DPSU,BLTN_CAM,SCM,OHCL,RWPC,RRHV,WPC,HOD,ASAU

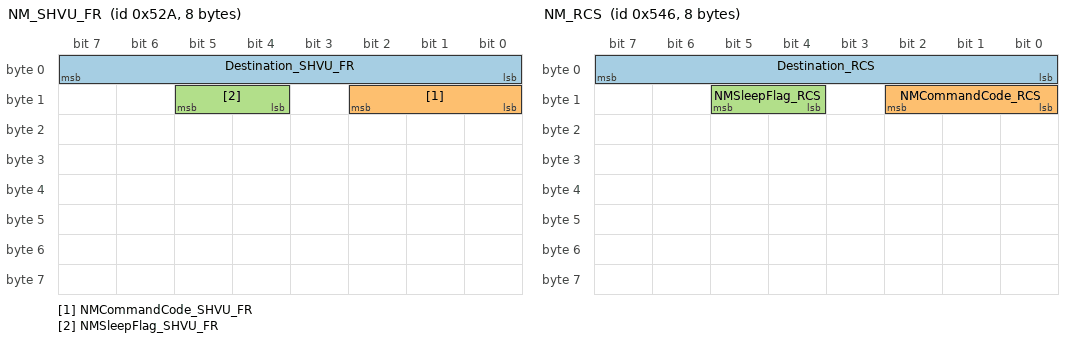
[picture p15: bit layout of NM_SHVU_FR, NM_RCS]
BO_ 1322 NM_SHVU_FR: 8 SHVU_FR
 SG_ Destination_SHVU_FR : 0|8@1+ (1,0) [0|0] ""  WPC2,PSB,SHVU_RR,FCS,vHS_B2,EMCU,SLB,GW_APSU,GW_DLBCU,RCM,ARS,CGW_CCU,vDummy_HS_B,GW_RLPSU,ATS,RLHV,SGU,PFSU,GW_RRPSU,ALBCU,DSAU,SWRC,RCS,GW_DPSU,BLTN_CAM,SCM,OHCL,RWPC,RRHV,WPC,HOD,ASAU
 SG_ NMCommandCode_SHVU_FR : 8|3@1+ (1,0) [0|0] ""  WPC2,PSB,SHVU_RR,FCS,vHS_B2,EMCU,SLB,GW_APSU,GW_DLBCU,RCM,ARS,CGW_CCU,vDummy_HS_B,GW_RLPSU,ATS,RLHV,SGU,PFSU,GW_RRPSU,ALBCU,DSAU,SWRC,RCS,GW_DPSU,BLTN_CAM,SCM,OHCL,RWPC,RRHV,WPC,HOD,ASAU
 SG_ NMSleepFlag_SHVU_FR : 12|2@1+ (1,0) [0|0] ""  WPC2,PSB,SHVU_RR,FCS,vHS_B2,EMCU,SLB,GW_APSU,GW_DLBCU,RCM,ARS,CGW_CCU,vDummy_HS_B,GW_RLPSU,ATS,RLHV,SGU,PFSU,GW_RRPSU,ALBCU,DSAU,SWRC,RCS,GW_DPSU,BLTN_CAM,SCM,OHCL,RWPC,RRHV,WPC,HOD,ASAU

BO_ 1350 NM_RCS: 8 RCS
 SG_ Destination_RCS : 0|8@1+ (1,0) [0|0] ""  WPC2,PSB,SHVU_RR,FCS,vHS_B2,EMCU,SLB,GW_APSU,GW_DLBCU,RCM,ARS,CGW_CCU,vDummy_HS_B,GW_RLPSU,ATS,RLHV,SGU,PFSU,GW_RRPSU,ALBCU,DSAU,SWRC,SHVU_FR,GW_DPSU,BLTN_CAM,SCM,OHCL,RWPC,RRHV,WPC,HOD,ASAU
 SG_ NMCommandCode_RCS : 8|3@1+ (1,0) [0|0] ""  WPC2,PSB,SHVU_RR,FCS,vHS_B2,EMCU,SLB,GW_APSU,GW_DLBCU,RCM,ARS,CGW_CCU,vDummy_HS_B,GW_RLPSU,ATS,RLHV,SGU,PFSU,GW_RRPSU,ALBCU,DSAU,SWRC,SHVU_FR,GW_DPSU,BLTN_CAM,SCM,OHCL,RWPC,RRHV,WPC,HOD,ASAU
 SG_ NMSleepFlag_RCS : 12|2@1+ (1,0) [0|0] ""  WPC2,PSB,SHVU_RR,FCS,vHS_B2,EMCU,SLB,GW_APSU,GW_DLBCU,RCM,ARS,CGW_CCU,vDummy_HS_B,GW_RLPSU,ATS,RLHV,SGU,PFSU,GW_RRPSU,ALBCU,DSAU,SWRC,SHVU_FR,GW_DPSU,BLTN_CAM,SCM,OHCL,RWPC,RRHV,WPC,HOD,ASAU

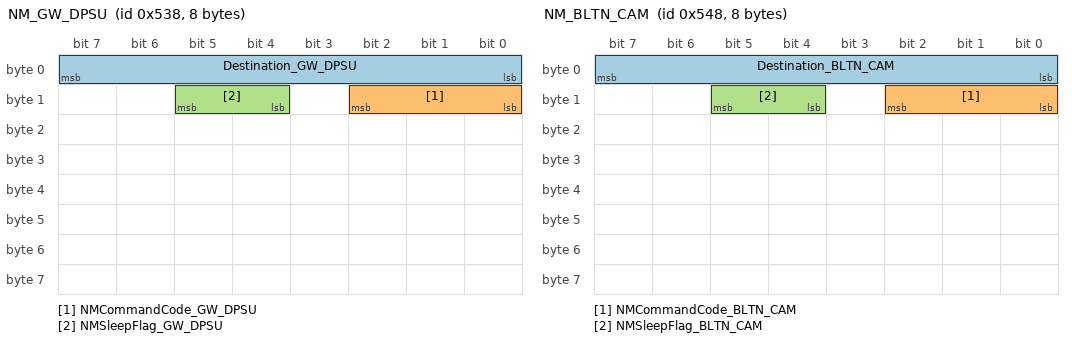
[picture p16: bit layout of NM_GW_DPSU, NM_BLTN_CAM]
BO_ 1336 NM_GW_DPSU: 8 GW_DPSU
 SG_ Destination_GW_DPSU : 0|8@1+ (1,0) [0|0] ""  WPC2,PSB,SHVU_RR,FCS,vHS_B2,EMCU,SLB,GW_APSU,GW_DLBCU,RCM,ARS,CGW_CCU,vDummy_HS_B,GW_RLPSU,ATS,RLHV,SGU,PFSU,GW_RRPSU,ALBCU,DSAU,SWRC,SHVU_FR,RCS,BLTN_CAM,SCM,OHCL,RWPC,RRHV,WPC,HOD,ASAU
 SG_ NMCommandCode_GW_DPSU : 8|3@1+ (1,0) [0|0] ""  WPC2,PSB,SHVU_RR,FCS,vHS_B2,EMCU,SLB,GW_APSU,GW_DLBCU,RCM,ARS,CGW_CCU,vDummy_HS_B,GW_RLPSU,ATS,RLHV,SGU,PFSU,GW_RRPSU,ALBCU,DSAU,SWRC,SHVU_FR,RCS,BLTN_CAM,SCM,OHCL,RWPC,RRHV,WPC,HOD,ASAU
 SG_ NMSleepFlag_GW_DPSU : 12|2@1+ (1,0) [0|0] ""  WPC2,PSB,SHVU_RR,FCS,vHS_B2,EMCU,SLB,GW_APSU,GW_DLBCU,RCM,ARS,CGW_CCU,vDummy_HS_B,GW_RLPSU,ATS,RLHV,SGU,PFSU,GW_RRPSU,ALBCU,DSAU,SWRC,SHVU_FR,RCS,BLTN_CAM,SCM,OHCL,RWPC,RRHV,WPC,HOD,ASAU

BO_ 1352 NM_BLTN_CAM: 8 BLTN_CAM
 SG_ Destination_BLTN_CAM : 0|8@1+ (1,0) [0|0] ""  WPC2,PSB,SHVU_RR,FCS,vHS_B2,EMCU,SLB,GW_APSU,GW_DLBCU,RCM,ARS,CGW_CCU,vDummy_HS_B,GW_RLPSU,ATS,RLHV,SGU,PFSU,GW_RRPSU,ALBCU,DSAU,SWRC,SHVU_FR,RCS,GW_DPSU,SCM,OHCL,RWPC,RRHV,WPC,HOD,ASAU
 SG_ NMCommandCode_BLTN_CAM : 8|3@1+ (1,0) [0|0] ""  WPC2,PSB,SHVU_RR,FCS,vHS_B2,EMCU,SLB,GW_APSU,GW_DLBCU,RCM,ARS,CGW_CCU,vDummy_HS_B,GW_RLPSU,ATS,RLHV,SGU,PFSU,GW_RRPSU,ALBCU,DSAU,SWRC,SHVU_FR,RCS,GW_DPSU,SCM,OHCL,RWPC,RRHV,WPC,HOD,ASAU
 SG_ NMSleepFlag_BLTN_CAM : 12|2@1+ (1,0) [0|0] ""  WPC2,PSB,SHVU_RR,FCS,vHS_B2,EMCU,SLB,GW_APSU,GW_DLBCU,RCM,ARS,CGW_CCU,vDummy_HS_B,GW_RLPSU,ATS,RLHV,SGU,PFSU,GW_RRPSU,ALBCU,DSAU,SWRC,SHVU_FR,RCS,GW_DPSU,SCM,OHCL,RWPC,RRHV,WPC,HOD,ASAU

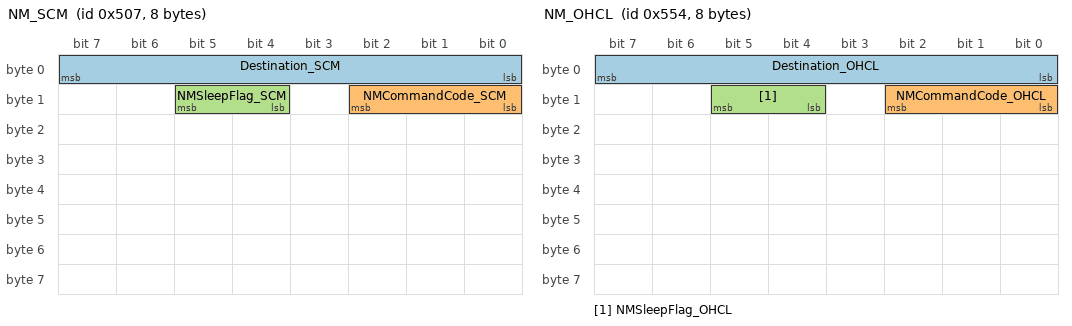
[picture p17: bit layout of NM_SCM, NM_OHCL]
BO_ 1287 NM_SCM: 8 SCM
 SG_ Destination_SCM : 0|8@1+ (1,0) [0|0] ""  WPC2,PSB,SHVU_RR,FCS,vHS_B2,EMCU,SLB,GW_APSU,GW_DLBCU,RCM,ARS,CGW_CCU,vDummy_HS_B,GW_RLPSU,ATS,RLHV,SGU,PFSU,GW_RRPSU,ALBCU,DSAU,SWRC,SHVU_FR,RCS,GW_DPSU,BLTN_CAM,OHCL,RWPC,RRHV,WPC,HOD,ASAU
 SG_ NMCommandCode_SCM : 8|3@1+ (1,0) [0|0] ""  WPC2,PSB,SHVU_RR,FCS,vHS_B2,EMCU,SLB,GW_APSU,GW_DLBCU,RCM,ARS,CGW_CCU,vDummy_HS_B,GW_RLPSU,ATS,RLHV,SGU,PFSU,GW_RRPSU,ALBCU,DSAU,SWRC,SHVU_FR,RCS,GW_DPSU,BLTN_CAM,OHCL,RWPC,RRHV,WPC,HOD,ASAU
 SG_ NMSleepFlag_SCM : 12|2@1+ (1,0) [0|0] ""  WPC2,PSB,SHVU_RR,FCS,vHS_B2,EMCU,SLB,GW_APSU,GW_DLBCU,RCM,ARS,CGW_CCU,vDummy_HS_B,GW_RLPSU,ATS,RLHV,SGU,PFSU,GW_RRPSU,ALBCU,DSAU,SWRC,SHVU_FR,RCS,GW_DPSU,BLTN_CAM,OHCL,RWPC,RRHV,WPC,HOD,ASAU

BO_ 1364 NM_OHCL: 8 OHCL
 SG_ Destination_OHCL : 0|8@1+ (1,0) [0|0] ""  WPC2,PSB,SHVU_RR,FCS,vHS_B2,EMCU,SLB,GW_APSU,GW_DLBCU,RCM,ARS,CGW_CCU,vDummy_HS_B,GW_RLPSU,ATS,RLHV,SGU,PFSU,GW_RRPSU,ALBCU,DSAU,SWRC,SHVU_FR,RCS,GW_DPSU,BLTN_CAM,SCM,RWPC,RRHV,WPC,HOD,ASAU
 SG_ NMCommandCode_OHCL : 8|3@1+ (1,0) [0|0] ""  WPC2,PSB,SHVU_RR,FCS,vHS_B2,EMCU,SLB,GW_APSU,GW_DLBCU,RCM,ARS,CGW_CCU,vDummy_HS_B,GW_RLPSU,ATS,RLHV,SGU,PFSU,GW_RRPSU,ALBCU,DSAU,SWRC,SHVU_FR,RCS,GW_DPSU,BLTN_CAM,SCM,RWPC,RRHV,WPC,HOD,ASAU
 SG_ NMSleepFlag_OHCL : 12|2@1+ (1,0) [0|0] ""  WPC2,PSB,SHVU_RR,FCS,vHS_B2,EMCU,SLB,GW_APSU,GW_DLBCU,RCM,ARS,CGW_CCU,vDummy_HS_B,GW_RLPSU,ATS,RLHV,SGU,PFSU,GW_RRPSU,ALBCU,DSAU,SWRC,SHVU_FR,RCS,GW_DPSU,BLTN_CAM,SCM,RWPC,RRHV,WPC,HOD,ASAU

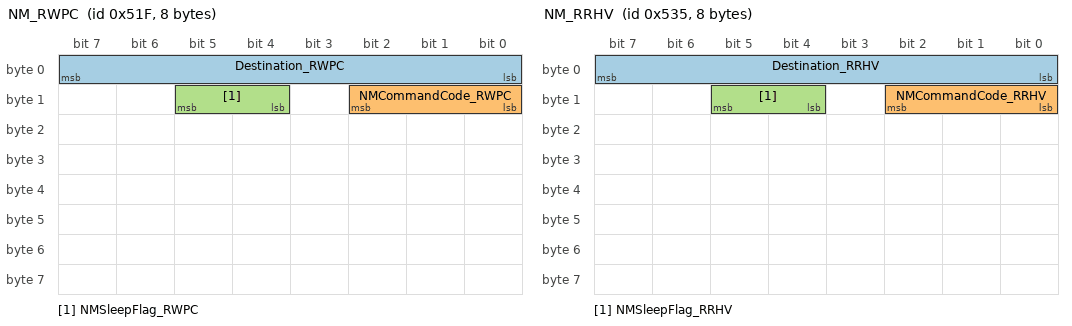
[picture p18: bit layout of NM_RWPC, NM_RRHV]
BO_ 1311 NM_RWPC: 8 RWPC
 SG_ Destination_RWPC : 0|8@1+ (1,0) [0|0] ""  WPC2,PSB,SHVU_RR,FCS,vHS_B2,EMCU,SLB,GW_APSU,GW_DLBCU,RCM,ARS,CGW_CCU,vDummy_HS_B,GW_RLPSU,ATS,RLHV,SGU,PFSU,GW_RRPSU,ALBCU,DSAU,SWRC,SHVU_FR,RCS,GW_DPSU,BLTN_CAM,SCM,OHCL,RRHV,WPC,HOD,ASAU
 SG_ NMCommandCode_RWPC : 8|3@1+ (1,0) [0|0] ""  WPC2,PSB,SHVU_RR,FCS,vHS_B2,EMCU,SLB,GW_APSU,GW_DLBCU,RCM,ARS,CGW_CCU,vDummy_HS_B,GW_RLPSU,ATS,RLHV,SGU,PFSU,GW_RRPSU,ALBCU,DSAU,SWRC,SHVU_FR,RCS,GW_DPSU,BLTN_CAM,SCM,OHCL,RRHV,WPC,HOD,ASAU
 SG_ NMSleepFlag_RWPC : 12|2@1+ (1,0) [0|0] ""  WPC2,PSB,SHVU_RR,FCS,vHS_B2,EMCU,SLB,GW_APSU,GW_DLBCU,RCM,ARS,CGW_CCU,vDummy_HS_B,GW_RLPSU,ATS,RLHV,SGU,PFSU,GW_RRPSU,ALBCU,DSAU,SWRC,SHVU_FR,RCS,GW_DPSU,BLTN_CAM,SCM,OHCL,RRHV,WPC,HOD,ASAU

BO_ 1333 NM_RRHV: 8 RRHV
 SG_ Destination_RRHV : 0|8@1+ (1,0) [0|0] ""  WPC2,PSB,SHVU_RR,FCS,vHS_B2,EMCU,SLB,GW_APSU,GW_DLBCU,RCM,ARS,CGW_CCU,vDummy_HS_B,GW_RLPSU,ATS,RLHV,SGU,PFSU,GW_RRPSU,ALBCU,DSAU,SWRC,SHVU_FR,RCS,GW_DPSU,BLTN_CAM,SCM,OHCL,RWPC,WPC,HOD,ASAU
 SG_ NMCommandCode_RRHV : 8|3@1+ (1,0) [0|0] ""  WPC2,PSB,SHVU_RR,FCS,vHS_B2,EMCU,SLB,GW_APSU,GW_DLBCU,RCM,ARS,CGW_CCU,vDummy_HS_B,GW_RLPSU,ATS,RLHV,SGU,PFSU,GW_RRPSU,ALBCU,DSAU,SWRC,SHVU_FR,RCS,GW_DPSU,BLTN_CAM,SCM,OHCL,RWPC,WPC,HOD,ASAU
 SG_ NMSleepFlag_RRHV : 12|2@1+ (1,0) [0|0] ""  WPC2,PSB,SHVU_RR,FCS,vHS_B2,EMCU,SLB,GW_APSU,GW_DLBCU,RCM,ARS,CGW_CCU,vDummy_HS_B,GW_RLPSU,ATS,RLHV,SGU,PFSU,GW_RRPSU,ALBCU,DSAU,SWRC,SHVU_FR,RCS,GW_DPSU,BLTN_CAM,SCM,OHCL,RWPC,WPC,HOD,ASAU

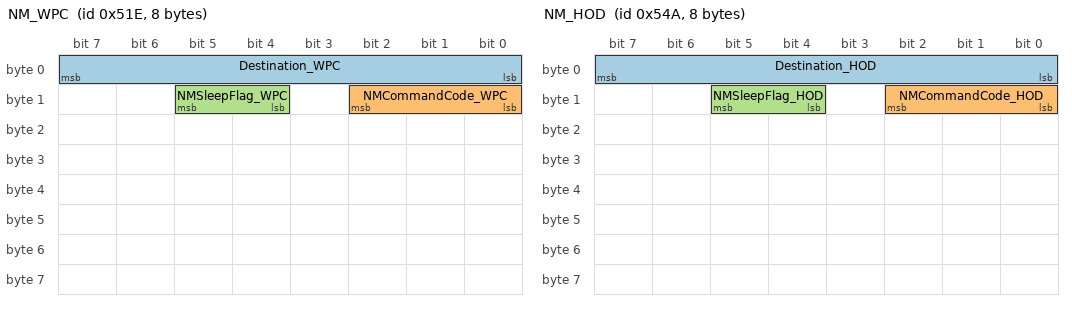
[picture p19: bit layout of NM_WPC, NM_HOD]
BO_ 1310 NM_WPC: 8 WPC
 SG_ Destination_WPC : 0|8@1+ (1,0) [0|0] ""  WPC2,PSB,SHVU_RR,FCS,vHS_B2,EMCU,SLB,GW_APSU,GW_DLBCU,RCM,ARS,CGW_CCU,vDummy_HS_B,GW_RLPSU,ATS,RLHV,SGU,PFSU,GW_RRPSU,ALBCU,DSAU,SWRC,SHVU_FR,RCS,GW_DPSU,BLTN_CAM,SCM,OHCL,RWPC,RRHV,HOD,ASAU
 SG_ NMCommandCode_WPC : 8|3@1+ (1,0) [0|0] ""  WPC2,PSB,SHVU_RR,FCS,vHS_B2,EMCU,SLB,GW_APSU,GW_DLBCU,RCM,ARS,CGW_CCU,vDummy_HS_B,GW_RLPSU,ATS,RLHV,SGU,PFSU,GW_RRPSU,ALBCU,DSAU,SWRC,SHVU_FR,RCS,GW_DPSU,BLTN_CAM,SCM,OHCL,RWPC,RRHV,HOD,ASAU
 SG_ NMSleepFlag_WPC : 12|2@1+ (1,0) [0|0] ""  WPC2,PSB,SHVU_RR,FCS,vHS_B2,EMCU,SLB,GW_APSU,GW_DLBCU,RCM,ARS,CGW_CCU,vDummy_HS_B,GW_RLPSU,ATS,RLHV,SGU,PFSU,GW_RRPSU,ALBCU,DSAU,SWRC,SHVU_FR,RCS,GW_DPSU,BLTN_CAM,SCM,OHCL,RWPC,RRHV,HOD,ASAU

BO_ 1354 NM_HOD: 8 HOD
 SG_ Destination_HOD : 0|8@1+ (1,0) [0|0] ""  WPC2,PSB,SHVU_RR,FCS,vHS_B2,EMCU,SLB,GW_APSU,GW_DLBCU,RCM,ARS,CGW_CCU,vDummy_HS_B,GW_RLPSU,ATS,RLHV,SGU,PFSU,GW_RRPSU,ALBCU,DSAU,SWRC,SHVU_FR,RCS,GW_DPSU,BLTN_CAM,SCM,OHCL,RWPC,RRHV,WPC,ASAU
 SG_ NMCommandCode_HOD : 8|3@1+ (1,0) [0|0] ""  WPC2,PSB,SHVU_RR,FCS,vHS_B2,EMCU,SLB,GW_APSU,GW_DLBCU,RCM,ARS,CGW_CCU,vDummy_HS_B,GW_RLPSU,ATS,RLHV,SGU,PFSU,GW_RRPSU,ALBCU,DSAU,SWRC,SHVU_FR,RCS,GW_DPSU,BLTN_CAM,SCM,OHCL,RWPC,RRHV,WPC,ASAU
 SG_ NMSleepFlag_HOD : 12|2@1+ (1,0) [0|0] ""  WPC2,PSB,SHVU_RR,FCS,vHS_B2,EMCU,SLB,GW_APSU,GW_DLBCU,RCM,ARS,CGW_CCU,vDummy_HS_B,GW_RLPSU,ATS,RLHV,SGU,PFSU,GW_RRPSU,ALBCU,DSAU,SWRC,SHVU_FR,RCS,GW_DPSU,BLTN_CAM,SCM,OHCL,RWPC,RRHV,WPC,ASAU

BO_ 1363 NM_ASAU: 8 ASAU
 SG_ Destination_ASAU : 0|8@1+ (1,0) [0|0] ""  WPC2,PSB,SHVU_RR,FCS,vHS_B2,EMCU,SLB,GW_APSU,GW_DLBCU,RCM,ARS,CGW_CCU,vDummy_HS_B,GW_RLPSU,ATS,RLHV,SGU,PFSU,GW_RRPSU,ALBCU,DSAU,SWRC,SHVU_FR,RCS,GW_DPSU,BLTN_CAM,SCM,OHCL,RWPC,RRHV,WPC,HOD
 SG_ NMCommandCode_ASAU : 8|3@1+ (1,0) [0|0] ""  WPC2,PSB,SHVU_RR,FCS,vHS_B2,EMCU,SLB,GW_APSU,GW_DLBCU,RCM,ARS,CGW_CCU,vDummy_HS_B,GW_RLPSU,ATS,RLHV,SGU,PFSU,GW_RRPSU,ALBCU,DSAU,SWRC,SHVU_FR,RCS,GW_DPSU,BLTN_CAM,SCM,OHCL,RWPC,RRHV,WPC,HOD
 SG_ NMSleepFlag_ASAU : 12|2@1+ (1,0) [0|0] ""  WPC2,PSB,SHVU_RR,FCS,vHS_B2,EMCU,SLB,GW_APSU,GW_DLBCU,RCM,ARS,CGW_CCU,vDummy_HS_B,GW_RLPSU,ATS,RLHV,SGU,PFSU,GW_RRPSU,ALBCU,DSAU,SWRC,SHVU_FR,RCS,GW_DPSU,BLTN_CAM,SCM,OHCL,RWPC,RRHV,WPC,HOD

CM_ BO_ 1951 "[TP] Transport Protocol";
CM_ BO_ 977 "[PE] Periodic and On Event";
CM_ SG_ 977 SMK_Crc13Val "SMK_CyclicRedundancyCheck13Value";
CM_ SG_ 977 SMK_TlPwrOnSta "This signal is state of Tele Power On";
CM_ SG_ 977 SMK_AlvCnt13Val "SMK_AliveCounter13Value";
CM_ SG_ 977 SMK_TrmnlCtrlGrpStaBDC "SMK_TerminalControlStatus";
CM_ SG_ 977 SMK_TrmnlCtrlStaBDC "SMK_TerminalControlStatus";
CM_ SG_ 977 SMK_TrmnlCtrlGrpStaBDCEV "SMK_TerminalControlStatus";
CM_ SG_ 977 SMK_TrmnlCtrlStaBDCEV "SMK_TerminalControlStatus";
CM_ SG_ 977 SMK_EVPwrOffReq "EV Power Off Request";
CM_ SG_ 977 SMK_MaintenanceSrvMdReq "Maintenance Service mode request from BDC to VCU";
CM_ SG_ 977 Auth_ISKLearnSta2 "This signal is State of IAU Learning for New China BLE";
CM_ BO_ 983 "[PE] Periodic and On Event";
CM_ SG_ 983 BLTN_CAM_SWVerMajor "First Word(ASCII) in Built-in Cam S/W Ver";
CM_ SG_ 983 BLTN_CAM_SWVerMinor2 "Minor2 in Built-in Cam S/W Ver";
CM_ SG_ 983 BLTN_CAM_SWVerMinor3 "Minor3 in Built-in Cam S/W Ver";
CM_ SG_ 983 BLTN_CAM_SD_Card_Manufacturer "0x0(SD Card not found), 0x1(Micron-Genuine part), 0x2~0x5(Reserved), 0x6(Unknown), 0x7(Invalid)";
CM_ SG_ 983 BLTN_CAM_SD_Card_Cap_Class "0x0(SD Card not found), 0x1(64Gbyte Class), 0x2(128Gbyte Class), 0x3(256Gbyte Class), 0x4(512Gbyte Class), 0x5(1Tbyte Class), 0x6(2Tbyte Class), 0x7(Invalid)";
CM_ SG_ 983 BLTN_CAM_SWVerMinor1 "Minor1 in Built-in Cam S/W Ver";
CM_ BO_ 981 "[PE] Periodic and On Event";
CM_ SG_ 981 APSS_StExtFwdMvBtn "APSS_ExtensionForwardMoveButton";
CM_ SG_ 981 APSS_StSldFwdMvBtn "APSS_SlideForwardMoveButton";
CM_ SG_ 981 APSS_StSldBwdMvBtn "APSS_SlideBackwardMoveButton";
CM_ SG_ 981 APSS_StExtBwdMvBtn "APSS_ExtensionBackwardMoveButton";
CM_ SG_ 981 APSS_StRclFwdMvBtn "APSS_ReclinerForwardMoveButton";
CM_ SG_ 981 APSS_StRclBwdMvBtn "APSS_ReclinerBackwardMoveButton";
CM_ SG_ 981 APSS_StHgtUpMvBtn "APSS_HeightUpMoveButton";
CM_ SG_ 981 APSS_StHgtDnMvBtn "APSS_HeightDownMoveButton";
CM_ SG_ 981 APSS_StTltUpMvBtn "APSS_TiltUpMoveButton";
CM_ SG_ 981 APSS_StTltDnMvBtn "APSS_TiltDownMoveButton";
CM_ SG_ 981 APSS_StHRestUpMvBtn "APSS_Head Rest Up Move Button";
CM_ SG_ 981 APSS_StHRestDnMvBtn "APSS_Head Rest Down Move Button";
CM_ SG_ 981 APSS_StHRestFwdMvBtn "APSS_Head Rest Forward Move Button";
CM_ SG_ 981 APSS_StHRestBwdMvBtn "APSS_Head Rest Backward Move Button";
CM_ SG_ 981 APSS_StLegUpMvBtn "APSS_LegUpMoveButton";
CM_ SG_ 981 APSS_StLegDnMvBtn "APSS_LegDownMoveButton";
CM_ SG_ 981 APSS_StRlxModeBtn "APSS_RelaxModeButton";
CM_ SG_ 981 APSS_StRlxReturnBtn "APSS_RelaxReturnButton";
CM_ SG_ 981 APSS_StRlxTltUpMvBtn "APSS_RelaxTiltUpMoveButton";
CM_ SG_ 981 APSS_StRlxTltDnMvBtn "APSS_RelaxTiltDownMoveButton";
CM_ SG_ 981 APSS_StAutoModeEnable "Passenger seat one-touch operation signal";
CM_ BO_ 968 "[PE] Periodic and On Event";
CM_ SG_ 968 RCM_Crc3Val "RCM_CyclicRedundancyCheck3Value";
CM_ SG_ 968 RCM_AlvCnt3Val "RCM_AliveCounter3Value";
CM_ SG_ 968 RCM_BldOpSta "Front Sunroof Blind Motor Operation Status";
CM_ SG_ 968 RCM_BldPosSta "Sunroof Blind Position Status";
CM_ SG_ 968 RCM_BldFltSta "Sunroof Blind Fault Status";
CM_ BO_ 963 "[PE] Periodic and On Event";
CM_ SG_ 963 BCM_Crc16Val "BCM_CyclicRedundancyCheck16Value";
CM_ SG_ 963 BCM_AlvCnt16Val "BCM_AliveCounter16Value";
CM_ SG_ 963 IBU_SWVerMajor1 "First Word(ASCII) in IBU S/W Ver";
CM_ SG_ 963 IBU_SWVerMinor1 "Second Word(ASCII) in IBU S/W Ver";
CM_ SG_ 963 IBU_SWVerMinor2 "Third Word(ASCII) in IBU S/W Ver";
CM_ BO_ 2172674052 "[P] Periodic";
CM_ SG_ 2172674052 AVH_Sta "AVH_Status ##2G##ESC - ESP11 - AVH_STAT";
CM_ SG_ 2172674052 AVH_Slope_Status "AVH_Slope_Status";
CM_ SG_ 2172674052 AVH_CluDis "AVH_ClusterDisplay ##2G##ESC - TCS15 - AVH_CLU";
CM_ SG_ 2172674052 LDM_Sta "LDM_Status ##2G##ESC - ESP11 - LDM_STAT";
CM_ SG_ 2172674052 AVH_AlrmReq "AVH_AlarmRequest ##2G##ESC - TCS15 - AVH_ALARM";
CM_ SG_ 2172674052 AVH_ActvStaLmpDis "AVH_ActiveStatusLampDisplay ##2G##ESC - TCS15 - AVH_I_LAMP";
CM_ SG_ 2172674052 AVH_LmpDis "AVH_LampDisplay ##2G##ESC - TCS15 - AVH_LAMP";
CM_ SG_ 2172674052 AWD_CrdnShftTqLimVal "AWD_CardanShaftTorqueLimitValue ##2G##ESC - ESP11 - 4WD_TQC_LIM";
CM_ SG_ 2172674052 EPB_ActvReq "EPB_ActiveRequest ##2G##ESC - ESP11 - REQ_EPB_ACT";
CM_ SG_ 2172674052 AWD_CltchDtyLimVal "AWD_ClutchDutyLimitValue ##2G##ESC - ESP11 - 4WD_CLU_LIM";
CM_ SG_ 2172674052 AWD_TransmsnTqLimModSta "AWD_TransmissionTorqueLimitModeStatus ##2G##ESC - ESP11 - 4WD_LIM_MODE";
CM_ SG_ 2172674052 AWD_RrWhlDtyLimReq "AWD_RearWheelDutyLimitRequest ##2G##ESC - ESP11 - 4WD_LIM_REQ";
CM_ SG_ 2172674052 EPB_StaReq "EPB_StatusRequest ##2G##ESC - ESP11 - REQ_EPB_STAT";
CM_ SG_ 2172674052 AWD_FastOpnCrdnShftCltchReq "AWD_FastOpenCardanShaftClutchRequest ##2G##ESC - ESP11 - 4WD_OPEN";
CM_ SG_ 2172674052 ECD_ActvSta "ECD_ActiveStatus ##2G##ESC - ESP11 - ECD_ACT";
CM_ BO_ 2172674051 "[P] Periodic";
CM_ SG_ 2172674051 ESC_CylPrsrVal "ESC_CylinderPressureValue ##2G##ESC - ESP12 - CYL_PRES";
CM_ SG_ 2172674051 ESC_CylPrsrSta "ESC_CylinderPressureStatus ##2G##ESC - ESP12 - CYL_PRES_STAT";
CM_ SG_ 2172674051 ESC_CylPrsrDiagSta "ESC_CylinderPressureDiagnosisStatus ##2G##ESC - ESP12 - CYL_PRESS_DIAG";
CM_ SG_ 2172674051 ESC_CylPrsrFlagSta "ESC_CylinderPressureFlagStatus ##2G##ESC - ESP12 - CYL_PRES_FLAG";
CM_ SG_ 2172674051 ESC_VsmActvSta "ESC_VsmActiveStatus ##2G##ESC - VSM11 - CF_Esc_Act";
CM_ SG_ 2172674051 ESC_VsmDfctvSta "ESC_VsmDefectiveStatus ##2G##ESC - VSM11 - CF_Esc_Def";
CM_ SG_ 2172674051 ESC_VsmCtrlModSta "ESC_VsmControlModeStatus ##2G##ESC - VSM11 - CF_Esc_CtrMode";
CM_ SG_ 2172674051 ESC_StrTqReq "ESC_SteeringTorqueReqeust ##2G##ESC - TCS15 - CR_Esc_StrTqReq";
CM_ SG_ 2172674051 TVC_ActSta "The signal of TVC_ActSta is purposed to notice to controllers as regarding to Touque vectoring control such as DTCH.";
CM_ SG_ 2172674051 ESC_LongAccelOffstCalibPrmtr "Longitudinal Acceleration Offset Calibration Parameter";
CM_ SG_ 2172674051 ESC_IMURstStaAck "IMU Reset Status Acknowledge";
CM_ BO_ 967 "[PE] Periodic and On Event";
CM_ SG_ 967 RCM_Crc2Val "RCM_CyclicRedundancyCheck2Value";
CM_ SG_ 967 RCM_AlvCnt2Val "RCM_AliveCounter2Value";
CM_ SG_ 967 RCM_SunroofOpnSta "Sunroof Glass Open Status";
CM_ SG_ 967 RCM_GlsOpSta "Front Sunroof Glass Motor Operation Status";
CM_ SG_ 967 RCM_GlsPosSta "Sunroof Glass Position Status";
CM_ SG_ 967 RCM_GlsFltSta "Sunroof Glass Fault Status";
CM_ BO_ 2172674050 "[P] Periodic";
CM_ SG_ 2172674050 TCS_Sta "Status of TCS Function";
CM_ SG_ 2172674050 TCS_PreActvSta "TCS_PreActiveStatus ##2G##ESC - TCS13 - Pre_TCS_CTL";
CM_ SG_ 2172674050 DBC_Sta "Status of DBC Function";
CM_ SG_ 2172674050 TCS_TqFlag "Flag indicating positive or negative TCS Intervention";
CM_ SG_ 2172674050 MSR_TqFlag "Flag indicating positive or negative MSR Intervention";
CM_ SG_ 2172674050 HAC_Sta "Status of HAC Function";
CM_ SG_ 2172674050 BJD_Flag "Brake Judder Detection";
CM_ SG_ 2172674050 TCS_SlwTqFlag "Flag indicating positive or negative SLOW TCS Intervention";
CM_ SG_ 2172674050 TCS_Req "TCS_Request ##2G##ESC - TCS11 - TCS_REQ";
CM_ SG_ 2172674050 MSR_FuncReq "MSR_FunctionRequest ##2G##ESC - TCS11 - MSR_C_REQ";
CM_ SG_ 2172674050 TCS_GearShftCharacteristicVal "TCS_GearShiftCharacteristicValue ##2G##ESC - TCS11 - TCS_GSC";
CM_ SG_ 2172674050 TCS_ManufacturerVal "TCS_ManufacturerInformationValue ##2G##ESC - TCS11 - TCS_MFRN";
CM_ SG_ 2172674050 TCS_TqIntrvntnVal "TCS_TorqueInterventionValue ##2G##ESC - TCS11 - TQI_TCS";
CM_ SG_ 2172674050 MSR_TqIntrvntnVal "MSR_TorqueInterventionValue ##2G##ESC - TCS11 - TQI_MSR";
CM_ SG_ 2172674050 TCS_SlwTqIntrvntnVal "TCS_SlowTorqueInterventionValue ##2G##ESC - TCS11 - TQI_SLW_TCS";
CM_ SG_ 2172674050 ESC_Sta "Status of ESC Function";
CM_ BO_ 966 "[PE] Periodic and On Event";
CM_ SG_ 966 RCM_Crc1Val "RCM_CyclicRedundancyCheck1Value";
CM_ SG_ 966 RCM_AlvCnt1Val "RCM_AliveCounter1Value";
CM_ SG_ 966 RCM_OptTyp "RCM (Roof Control Module) Option Type";
CM_ SG_ 966 RCM_TunnelOptType "Sunroof RCM Tunnel Option Type";
CM_ BO_ 2172674049 "[P] Periodic";
CM_ SG_ 2172674049 ESC_Crc1Val "ESC_CyclicRedundancyCheck1Value";
CM_ SG_ 2172674049 ESC_AlvCnt1Val "ESC_AliveCounter1Value";
CM_ SG_ 2172674049 ESC_CltchPdStrkSnsrDuty "Clutch Pedal Stroke Sensor Duty Signal By-pass value";
CM_ SG_ 2172674049 TCS_LmpSta "TCS_LampStatus ##2G##ESC - TCS15 - TCS_LAMP";
CM_ SG_ 2172674049 TCS_OffLmpSta "TCS_OffLampStatus ##2G##ESC - TCS15 - TCS_OFF_LAMP";
CM_ SG_ 2172674049 ESC_OffTempSta "ESC_OffStepStatus ##2G##ESC - TCS15 - ESC_Off_Step";
CM_ SG_ 2172674049 ESC_OffSwSta "ESC_OffSiwtchStatus";
CM_ SG_ 2172674049 DBC_WrngLmpSta "DBC_WarningLampStatus ##2G##ESC - TCS15 - DBC_W_LAMP";
CM_ SG_ 2172674049 DBC_FuncLmpSta "DBC_FuncitonLampStatus ##2G##ESC - TCS15 - DBC_F_LAMP";
CM_ SG_ 2172674049 DBC_ClusterDis "DBC Pop-up Signal for Deactivation";
CM_ SG_ 2172674049 ESC_SprtLmpSta "ESC Sport Lamp Status ##2G##ESC - TCS15 - ESC_SPORT_LAMP";
CM_ SG_ 2172674049 ESC_BrkCtrlSta "ESC_BrakeControlStatus ##2G##ESC - TCS11 - CF_Esc_BrkCtl";
CM_ SG_ 2172674049 ESC_MyDrive_CodingSta "Information regarding the My Drive Mode (ESC OFF Logic) coding status of ESC";
CM_ SG_ 2172674049 ESC_OffSwSta2 "Information regarding the ESC Off Switch Click Status by switch input of driver (Short or Long)";
CM_ BO_ 1301 "NM Message";
CM_ SG_ 1301 Destination_WPC2 "OSEK NM Destination Node Identifier";
CM_ SG_ 1301 NMCommandCode_WPC2 "OSEK NM Command Code";
CM_ SG_ 1301 NMSleepFlag_WPC2 "OSEK NM Sleep Indication Flag";
CM_ BO_ 1345 "NM Message";
CM_ SG_ 1345 Destination_PSB "OSEK NM Destination Node Identifier";
CM_ SG_ 1345 NMCommandCode_PSB "OSEK NM Command Code";
CM_ SG_ 1345 NMSleepFlag_PSB "OSEK NM Sleep Indication Flag";
CM_ BO_ 1323 "NM Message";
CM_ SG_ 1323 Destination_SHVU_RR "OSEK NM Destination Node Identifier";
CM_ SG_ 1323 NMCommandCode_SHVU_RR "OSEK NM Command Code";
CM_ SG_ 1323 NMSleepFlag_SHVU_RR "OSEK NM Sleep Indication Flag";
CM_ BO_ 1313 "NM Message";
CM_ SG_ 1313 Destination_FCS "OSEK NM Destination Node Identifier";
CM_ SG_ 1313 NMCommandCode_FCS "OSEK NM Command Code";
CM_ SG_ 1313 NMSleepFlag_FCS "OSEK NM Sleep Indication Flag";
CM_ BO_ 1297 "NM Message";
CM_ SG_ 1297 Destination_EMCU "OSEK NM Destination Node Identifier";
CM_ SG_ 1297 NMCommandCode_EMCU "OSEK NM Command Code";
CM_ SG_ 1297 NMSleepFlag_EMCU "OSEK NM Sleep Indication Flag";
CM_ BO_ 1307 "NM Message";
CM_ SG_ 1307 Destination_SLB "OSEK NM Destination Node Identifier";
CM_ SG_ 1307 NMCommandCode_SLB "OSEK NM Command Code";
CM_ SG_ 1307 NMSleepFlag_SLB "OSEK NM Sleep Indication Flag";
CM_ BO_ 1329 "NM Message";
CM_ SG_ 1329 Destination_GW_APSU "OSEK NM Destination Node Identifier";
CM_ SG_ 1329 NMCommandCode_GW_APSU "OSEK NM Command Code";
CM_ SG_ 1329 NMSleepFlag_GW_APSU "OSEK NM Sleep Indication Flag";
CM_ BO_ 1344 "NM Message";
CM_ SG_ 1344 Destination_GW_DLBCU "OSEK NM Destination Node Identifier";
CM_ SG_ 1344 NMCommandCode_GW_DLBCU "OSEK NM Command Code";
CM_ SG_ 1344 NMSleepFlag_GW_DLBCU "OSEK NM Sleep Indication Flag";
CM_ BO_ 1341 "NM Message";
CM_ SG_ 1341 Destination_RCM "OSEK NM Destination Node Identifier";
CM_ SG_ 1341 NMCommandCode_RCM "OSEK NM Command Code";
CM_ SG_ 1341 NMSleepFlag_RCM "OSEK NM Sleep Indication Flag";
CM_ BO_ 1290 "NM Message";
CM_ SG_ 1290 Destination_ARS "OSEK NM Destination Node Identifier";
CM_ SG_ 1290 NMCommandCode_ARS "OSEK NM Command Code";
CM_ SG_ 1290 NMSleepFlag_ARS "OSEK NM Sleep Indication Flag";
CM_ BO_ 1392 "NM Message";
CM_ SG_ 1392 Destination_CGW_CCU "OSEK NM Destination Node Identifier";
CM_ SG_ 1392 NMCommandCode_CGW_CCU "OSEK NM Command Code";
CM_ SG_ 1392 NMSleepFlag_CGW_CCU "OSEK NM Sleep Indication Flag";
CM_ BO_ 1308 "NM Message";
CM_ SG_ 1308 Destination_GW_RLPSU "OSEK NM Destination Node Identifier";
CM_ SG_ 1308 NMCommandCode_GW_RLPSU "OSEK NM Command Code";
CM_ SG_ 1308 NMSleepFlag_GW_RLPSU "OSEK NM Sleep Indication Flag";
CM_ BO_ 1360 "NM Message";
CM_ SG_ 1360 Destination_ATS "OSEK NM Destination Node Identifier";
CM_ SG_ 1360 NMCommandCode_ATS "OSEK NM Command Code";
CM_ SG_ 1360 NMSleepFlag_ATS "OSEK NM Sleep Indication Flag";
CM_ BO_ 1332 "NM Message";
CM_ SG_ 1332 Destination_RLHV "OSEK NM Destination Node Identifier";
CM_ SG_ 1332 NMCommandCode_RLHV "OSEK NM Command Code";
CM_ SG_ 1332 NMSleepFlag_RLHV "OSEK NM Sleep Indication Flag";
CM_ BO_ 1342 "NM Message";
CM_ SG_ 1342 Destination_SGU "OSEK NM Destination Node Identifier";
CM_ SG_ 1342 NMCommandCode_SGU "OSEK NM Command Code";
CM_ SG_ 1342 NMSleepFlag_SGU "OSEK NM Sleep Indication Flag";
CM_ BO_ 1325 "NM Message";
CM_ SG_ 1325 Destination_PFSU "OSEK NM Destination Node Identifier";
CM_ SG_ 1325 NMCommandCode_PFSU "OSEK NM Command Code";
CM_ SG_ 1325 NMSleepFlag_PFSU "OSEK NM Sleep Indication Flag";
CM_ BO_ 1309 "NM Message";
CM_ SG_ 1309 Destination_GW_RRPSU "OSEK NM Destination Node Identifier";
CM_ SG_ 1309 NMCommandCode_GW_RRPSU "OSEK NM Command Code";
CM_ SG_ 1309 NMSleepFlag_GW_RRPSU "OSEK NM Sleep Indication Flag";
CM_ BO_ 1348 "NM Message";
CM_ SG_ 1348 Destination_ALBCU "OSEK NM Destination Node Identifier";
CM_ SG_ 1348 NMCommandCode_ALBCU "OSEK NM Command Code";
CM_ SG_ 1348 NMSleepFlag_ALBCU "OSEK NM Sleep Indication Flag";
CM_ BO_ 1369 "NM Message";
CM_ SG_ 1369 Destination_DSAU "OSEK NM Destination Node Identifier";
CM_ SG_ 1369 NMCommandCode_DSAU "OSEK NM Command Code";
CM_ SG_ 1369 NMSleepFlag_DSAU "OSEK NM Sleep Indication Flag";
CM_ BO_ 1288 "NM Message";
CM_ SG_ 1288 Destination_SWRC "OSEK NM Destination Node Identifier";
CM_ SG_ 1288 NMCommandCode_SWRC "OSEK NM Command Code";
CM_ SG_ 1288 NMSleepFlag_SWRC "OSEK NM Sleep Indication Flag";
CM_ BO_ 1322 "NM Message";
CM_ SG_ 1322 Destination_SHVU_FR "OSEK NM Destination Node Identifier";
CM_ SG_ 1322 NMCommandCode_SHVU_FR "OSEK NM Command Code";
CM_ SG_ 1322 NMSleepFlag_SHVU_FR "OSEK NM Sleep Indication Flag";
CM_ BO_ 1350 "NM Message";
CM_ SG_ 1350 Destination_RCS "OSEK NM Destination Node Identifier";
CM_ SG_ 1350 NMCommandCode_RCS "OSEK NM Command Code";
CM_ SG_ 1350 NMSleepFlag_RCS "OSEK NM Sleep Indication Flag";
CM_ BO_ 1336 "NM Message";
CM_ SG_ 1336 Destination_GW_DPSU "OSEK NM Destination Node Identifier";
CM_ SG_ 1336 NMCommandCode_GW_DPSU "OSEK NM Command Code";
CM_ SG_ 1336 NMSleepFlag_GW_DPSU "OSEK NM Sleep Indication Flag";
CM_ BO_ 1352 "NM Message";
CM_ SG_ 1352 Destination_BLTN_CAM "OSEK NM Destination Node Identifier";
CM_ SG_ 1352 NMCommandCode_BLTN_CAM "OSEK NM Command Code";
CM_ SG_ 1352 NMSleepFlag_BLTN_CAM "OSEK NM Sleep Indication Flag";
CM_ BO_ 1287 "NM Message";
CM_ SG_ 1287 Destination_SCM "OSEK NM Destination Node Identifier";
CM_ SG_ 1287 NMCommandCode_SCM "OSEK NM Command Code";
CM_ SG_ 1287 NMSleepFlag_SCM "OSEK NM Sleep Indication Flag";
CM_ BO_ 1364 "NM Message";
CM_ SG_ 1364 Destination_OHCL "OSEK NM Destination Node Identifier";
CM_ SG_ 1364 NMCommandCode_OHCL "OSEK NM Command Code";
CM_ SG_ 1364 NMSleepFlag_OHCL "OSEK NM Sleep Indication Flag";
CM_ BO_ 1311 "NM Message";
CM_ SG_ 1311 Destination_RWPC "OSEK NM Destination Node Identifier";
CM_ SG_ 1311 NMCommandCode_RWPC "OSEK NM Command Code";
CM_ SG_ 1311 NMSleepFlag_RWPC "OSEK NM Sleep Indication Flag";
CM_ BO_ 1333 "NM Message";
CM_ SG_ 1333 Destination_RRHV "OSEK NM Destination Node Identifier";
CM_ SG_ 1333 NMCommandCode_RRHV "OSEK NM Command Code";
CM_ SG_ 1333 NMSleepFlag_RRHV "OSEK NM Sleep Indication Flag";
CM_ BO_ 1310 "NM Message";
CM_ SG_ 1310 Destination_WPC "OSEK NM Destination Node Identifier";
CM_ SG_ 1310 NMCommandCode_WPC "OSEK NM Command Code";
CM_ SG_ 1310 NMSleepFlag_WPC "OSEK NM Sleep Indication Flag";
CM_ BO_ 1354 "NM Message";
CM_ SG_ 1354 Destination_HOD "OSEK NM Destination Node Identifier";
CM_ SG_ 1354 NMCommandCode_HOD "OSEK NM Command Code";
CM_ SG_ 1354 NMSleepFlag_HOD "OSEK NM Sleep Indication Flag";
CM_ BO_ 1363 "NM Message";
CM_ SG_ 1363 Destination_ASAU "OSEK NM Destination Node Identifier";
CM_ SG_ 1363 NMCommandCode_ASAU "OSEK NM Command Code";
CM_ SG_ 1363 NMSleepFlag_ASAU "OSEK NM Sleep Indication Flag";
BA_DEF_ BO_  "DiagState" ENUM  "No","Yes";
BA_DEF_ BO_  "DiagResponse" ENUM  "No","Yes";
BA_DEF_ BO_  "DiagRequest" ENUM  "No","Yes";
BA_DEF_ BO_  "TpMessage" ENUM  "No","Yes";
BA_DEF_ BO_  "UsrMsgIDSforwardDeviation" INT 0 100;
BA_DEF_ BO_  "UsrMsgIDSbackwardDeviation" INT 50 1000;
BA_DEF_ BO_  "GenMsgCycleTime" INT 0 2000;
BA_DEF_ BO_  "GenMsgStartDelayTime" INT 0 2000;
BA_DEF_ BO_  "GenMsgSendType" ENUM  "Cyclic","NoMsgSendType";
BA_DEF_ BO_  "GenMsgCycleTimeFast" INT 0 500;
BA_DEF_ BO_  "GenMsgDelayTime" INT 0 20;
BA_DEF_ BO_  "GenMsgILSupport" ENUM  "No","Yes";
BA_DEF_ BO_  "GenMsgNrOfRepetition" INT 0 3;
BA_DEF_ BO_  "NmMessage" ENUM  "No","Yes";
BA_DEF_ BO_  "NWM-Botschaft" ENUM  "No","Yes";
BA_DEF_ BO_  "TpTxIndex" INT 0 65535;
BA_DEF_ BO_  "VFrameFormat" ENUM  "StandardCAN","ExtendedCAN","reserved","reserved","reserved","reserved","reserved","reserved","reserved","reserved","reserved","reserved","reserved","reserved","StandardCAN_FD","ExtendedCAN_FD";
BA_DEF_ SG_  "UserSigValidity" ENUM  "B+","ACC","IG","IG1","IG2","IG3","IG1 or IG2","IG1 or IG3","Undef";
BA_DEF_ SG_  "TimeoutValue" STRING ;
BA_DEF_ SG_  "UsrSigPurpose" ENUM  "Undef","FN","DIAG","DIAG(Req)","DIAG(Res)","DIAG(Phy)","DEV","CCP(Req)","CCP(Res)","NM","TP";
BA_DEF_ SG_  "GenSigStartValue" INT 0 1215752192;
BA_DEF_ SG_  "NetworkRequest" ENUM  "Yes","No";
BA_DEF_ SG_  "NetworkRequestHoldingTime" INT 0 65535;
BA_DEF_ SG_  "Description" STRING ;
BA_DEF_ SG_  "Version" STRING ;
BA_DEF_ SG_  "GenSigEnvVarType" ENUM  "Int","Float","Undef";
BA_DEF_ SG_  "GenSigSendType" ENUM  "Cyclic","OnWrite","OnWriteWithRepetition","OnChange","OnChangeWithRepetition","IfActive","IfActiveWithRepetition","NoSigSendType","OnChangeAndIfActive","OnChangeAndIfActiveWithRepetition";
BA_DEF_ SG_  "GwSigLatencyTime" INT 0 65536;
BA_DEF_ SG_  "GwSigMissingSourceType" ENUM  "Undef","OldValue","DefaultValue","InitialValue";
BA_DEF_ SG_  "NWM-WakeupAllowed" ENUM  "<n.a.>";
BA_DEF_ SG_  "RoutingFactor" INT 1 1215752192;
BA_DEF_ SG_  "SystemSignalLongSymbol" STRING ;
BA_DEF_REL_ BU_SG_REL_  "GenSigTimeoutTime" INT 0 7000;
BA_DEF_DEF_  "DiagState" "No";
BA_DEF_DEF_  "DiagResponse" "No";
BA_DEF_DEF_  "DiagRequest" "No";
BA_DEF_DEF_  "TpMessage" "No";
BA_DEF_DEF_  "UsrMsgIDSforwardDeviation" 10;
BA_DEF_DEF_  "UsrMsgIDSbackwardDeviation" 100;
BA_DEF_DEF_  "GenMsgCycleTime" 200;
BA_DEF_DEF_  "GenMsgStartDelayTime" 0;
BA_DEF_DEF_  "GenMsgSendType" "NoMsgSendType";
BA_DEF_DEF_  "GenMsgCycleTimeFast" 40;
BA_DEF_DEF_  "GenMsgDelayTime" 20;
BA_DEF_DEF_  "GenMsgILSupport" "Yes";
BA_DEF_DEF_  "GenMsgNrOfRepetition" 3;
BA_DEF_DEF_  "NmMessage" "No";
BA_DEF_DEF_  "NWM-Botschaft" "No";
BA_DEF_DEF_  "TpTxIndex" 0;
BA_DEF_DEF_  "VFrameFormat" "StandardCAN";
BA_DEF_DEF_  "UserSigValidity" "IG";
BA_DEF_DEF_  "TimeoutValue" "";
BA_DEF_DEF_  "UsrSigPurpose" "FN";
BA_DEF_DEF_  "GenSigStartValue" 0;
BA_DEF_DEF_  "NetworkRequest" "No";
BA_DEF_DEF_  "NetworkRequestHoldingTime" 0;
BA_DEF_DEF_  "Description" "";
BA_DEF_DEF_  "Version" "";
BA_DEF_DEF_  "GenSigEnvVarType" "Undef";
BA_DEF_DEF_  "GenSigSendType" "NoSigSendType";
BA_DEF_DEF_  "GwSigLatencyTime" 40;
BA_DEF_DEF_  "GwSigMissingSourceType" "Undef";
BA_DEF_DEF_  "NWM-WakeupAllowed" "<n.a.>";
BA_DEF_DEF_  "RoutingFactor" 1;
BA_DEF_DEF_REL_ "GenSigTimeoutTime" 500;
BA_DEF_DEF_  "SystemSignalLongSymbol" "";
BA_ "TpTxIndex" BO_ 1951 109;
BA_ "TpMessage" BO_ 1951 1;
BA_ "GenMsgILSupport" BO_ 1951 0;
BA_ "DiagResponse" BO_ 1951 1;
BA_ "GenMsgNrOfRepetition" BO_ 1951 0;
BA_ "GenMsgCycleTimeFast" BO_ 1951 0;
BA_ "GenMsgCycleTime" BO_ 1951 0;
BA_ "GenMsgSendType" BO_ 977 0;
BA_ "GenMsgSendType" BO_ 983 0;
BA_ "GenMsgSendType" BO_ 981 0;
BA_ "GenMsgSendType" BO_ 968 0;
BA_ "GenMsgSendType" BO_ 963 0;
BA_ "VFrameFormat" BO_ 2172674052 1;
BA_ "GenMsgNrOfRepetition" BO_ 2172674052 0;
BA_ "GenMsgCycleTimeFast" BO_ 2172674052 0;
BA_ "GenMsgCycleTime" BO_ 2172674052 50;
BA_ "GenMsgSendType" BO_ 2172674052 0;
BA_ "VFrameFormat" BO_ 2172674051 1;
BA_ "GenMsgNrOfRepetition" BO_ 2172674051 0;
BA_ "GenMsgCycleTimeFast" BO_ 2172674051 0;
BA_ "GenMsgCycleTime" BO_ 2172674051 50;
BA_ "GenMsgSendType" BO_ 2172674051 0;
BA_ "GenMsgSendType" BO_ 967 0;
BA_ "VFrameFormat" BO_ 2172674050 1;
BA_ "GenMsgNrOfRepetition" BO_ 2172674050 0;
BA_ "GenMsgCycleTimeFast" BO_ 2172674050 0;
BA_ "GenMsgCycleTime" BO_ 2172674050 50;
BA_ "GenMsgSendType" BO_ 2172674050 0;
BA_ "GenMsgSendType" BO_ 966 0;
BA_ "VFrameFormat" BO_ 2172674049 1;
BA_ "GenMsgNrOfRepetition" BO_ 2172674049 0;
BA_ "GenMsgCycleTimeFast" BO_ 2172674049 0;
BA_ "GenMsgCycleTime" BO_ 2172674049 50;
BA_ "GenMsgSendType" BO_ 2172674049 0;
BA_ "GenMsgCycleTime" BO_ 1301 100;
BA_ "NWM-Botschaft" BO_ 1301 1;
BA_ "GenMsgILSupport" BO_ 1301 0;
BA_ "NmMessage" BO_ 1301 1;
BA_ "GenMsgCycleTime" BO_ 1345 100;
BA_ "NWM-Botschaft" BO_ 1345 1;
BA_ "GenMsgILSupport" BO_ 1345 0;
BA_ "NmMessage" BO_ 1345 1;
BA_ "GenMsgCycleTime" BO_ 1323 100;
BA_ "NWM-Botschaft" BO_ 1323 1;
BA_ "GenMsgILSupport" BO_ 1323 0;
BA_ "NmMessage" BO_ 1323 1;
BA_ "GenMsgCycleTime" BO_ 1313 100;
BA_ "NWM-Botschaft" BO_ 1313 1;
BA_ "GenMsgILSupport" BO_ 1313 0;
BA_ "NmMessage" BO_ 1313 1;
BA_ "GenMsgCycleTime" BO_ 1297 100;
BA_ "NWM-Botschaft" BO_ 1297 1;
BA_ "GenMsgILSupport" BO_ 1297 0;
BA_ "NmMessage" BO_ 1297 1;
BA_ "GenMsgCycleTime" BO_ 1307 100;
BA_ "NWM-Botschaft" BO_ 1307 1;
BA_ "GenMsgILSupport" BO_ 1307 0;
BA_ "NmMessage" BO_ 1307 1;
BA_ "GenMsgCycleTime" BO_ 1329 100;
BA_ "NWM-Botschaft" BO_ 1329 1;
BA_ "GenMsgILSupport" BO_ 1329 0;
BA_ "NmMessage" BO_ 1329 1;
BA_ "GenMsgCycleTime" BO_ 1344 100;
BA_ "NWM-Botschaft" BO_ 1344 1;
BA_ "GenMsgILSupport" BO_ 1344 0;
BA_ "NmMessage" BO_ 1344 1;
BA_ "GenMsgCycleTime" BO_ 1341 100;
BA_ "NWM-Botschaft" BO_ 1341 1;
BA_ "GenMsgILSupport" BO_ 1341 0;
BA_ "NmMessage" BO_ 1341 1;
BA_ "GenMsgCycleTime" BO_ 1290 100;
BA_ "NWM-Botschaft" BO_ 1290 1;
BA_ "GenMsgILSupport" BO_ 1290 0;
BA_ "NmMessage" BO_ 1290 1;
BA_ "GenMsgCycleTime" BO_ 1392 100;
BA_ "NWM-Botschaft" BO_ 1392 1;
BA_ "GenMsgILSupport" BO_ 1392 0;
BA_ "NmMessage" BO_ 1392 1;
BA_ "GenMsgCycleTime" BO_ 1308 100;
BA_ "NWM-Botschaft" BO_ 1308 1;
BA_ "GenMsgILSupport" BO_ 1308 0;
BA_ "NmMessage" BO_ 1308 1;
BA_ "GenMsgCycleTime" BO_ 1360 100;
BA_ "NWM-Botschaft" BO_ 1360 1;
BA_ "GenMsgILSupport" BO_ 1360 0;
BA_ "NmMessage" BO_ 1360 1;
BA_ "GenMsgCycleTime" BO_ 1332 100;
BA_ "NWM-Botschaft" BO_ 1332 1;
BA_ "GenMsgILSupport" BO_ 1332 0;
BA_ "NmMessage" BO_ 1332 1;
BA_ "GenMsgCycleTime" BO_ 1342 100;
BA_ "NWM-Botschaft" BO_ 1342 1;
BA_ "GenMsgILSupport" BO_ 1342 0;
BA_ "NmMessage" BO_ 1342 1;
BA_ "GenMsgCycleTime" BO_ 1325 100;
BA_ "NWM-Botschaft" BO_ 1325 1;
BA_ "GenMsgILSupport" BO_ 1325 0;
BA_ "NmMessage" BO_ 1325 1;
BA_ "GenMsgCycleTime" BO_ 1309 100;
BA_ "NWM-Botschaft" BO_ 1309 1;
BA_ "GenMsgILSupport" BO_ 1309 0;
BA_ "NmMessage" BO_ 1309 1;
BA_ "GenMsgCycleTime" BO_ 1348 100;
BA_ "NWM-Botschaft" BO_ 1348 1;
BA_ "GenMsgILSupport" BO_ 1348 0;
BA_ "NmMessage" BO_ 1348 1;
BA_ "GenMsgCycleTime" BO_ 1369 100;
BA_ "NWM-Botschaft" BO_ 1369 1;
BA_ "GenMsgILSupport" BO_ 1369 0;
BA_ "NmMessage" BO_ 1369 1;
BA_ "GenMsgCycleTime" BO_ 1288 100;
BA_ "NWM-Botschaft" BO_ 1288 1;
BA_ "GenMsgILSupport" BO_ 1288 0;
BA_ "NmMessage" BO_ 1288 1;
BA_ "GenMsgCycleTime" BO_ 1322 100;
BA_ "NWM-Botschaft" BO_ 1322 1;
BA_ "GenMsgILSupport" BO_ 1322 0;
BA_ "NmMessage" BO_ 1322 1;
BA_ "GenMsgCycleTime" BO_ 1350 100;
BA_ "NWM-Botschaft" BO_ 1350 1;
BA_ "GenMsgILSupport" BO_ 1350 0;
BA_ "NmMessage" BO_ 1350 1;
BA_ "GenMsgCycleTime" BO_ 1336 100;
BA_ "NWM-Botschaft" BO_ 1336 1;
BA_ "GenMsgILSupport" BO_ 1336 0;
BA_ "NmMessage" BO_ 1336 1;
BA_ "GenMsgCycleTime" BO_ 1352 100;
BA_ "NWM-Botschaft" BO_ 1352 1;
BA_ "GenMsgILSupport" BO_ 1352 0;
BA_ "NmMessage" BO_ 1352 1;
BA_ "GenMsgCycleTime" BO_ 1287 100;
BA_ "NWM-Botschaft" BO_ 1287 1;
BA_ "GenMsgILSupport" BO_ 1287 0;
BA_ "NmMessage" BO_ 1287 1;
BA_ "GenMsgCycleTime" BO_ 1364 100;
BA_ "NWM-Botschaft" BO_ 1364 1;
BA_ "GenMsgILSupport" BO_ 1364 0;
BA_ "NmMessage" BO_ 1364 1;
BA_ "GenMsgCycleTime" BO_ 1311 100;
BA_ "NWM-Botschaft" BO_ 1311 1;
BA_ "GenMsgILSupport" BO_ 1311 0;
BA_ "NmMessage" BO_ 1311 1;
BA_ "GenMsgCycleTime" BO_ 1333 100;
BA_ "NWM-Botschaft" BO_ 1333 1;
BA_ "GenMsgILSupport" BO_ 1333 0;
BA_ "NmMessage" BO_ 1333 1;
BA_ "GenMsgCycleTime" BO_ 1310 100;
BA_ "NWM-Botschaft" BO_ 1310 1;
BA_ "GenMsgILSupport" BO_ 1310 0;
BA_ "NmMessage" BO_ 1310 1;
BA_ "GenMsgCycleTime" BO_ 1354 100;
BA_ "NWM-Botschaft" BO_ 1354 1;
BA_ "GenMsgILSupport" BO_ 1354 0;
BA_ "NmMessage" BO_ 1354 1;
BA_ "GenMsgCycleTime" BO_ 1363 100;
BA_ "NWM-Botschaft" BO_ 1363 1;
BA_ "GenMsgILSupport" BO_ 1363 0;
BA_ "NmMessage" BO_ 1363 1;
BA_ "Version" SG_ 1951 APSU_PSU_AST_GST_Byte0 "22.11.14";
BA_ "NetworkRequestHoldingTime" SG_ 1951 APSU_PSU_AST_GST_Byte0 5000;
BA_ "NetworkRequest" SG_ 1951 APSU_PSU_AST_GST_Byte0 0;
BA_ "UserSigValidity" SG_ 1951 APSU_PSU_AST_GST_Byte0 0;
BA_ "UsrSigPurpose" SG_ 1951 APSU_PSU_AST_GST_Byte0 4;
BA_ "Description" SG_ 1951 APSU_PSU_AST_GST_Byte0 "TP Index : 109";
BA_ "Version" SG_ 1951 APSU_PSU_AST_GST_Byte2 "22.11.14";
BA_ "NetworkRequestHoldingTime" SG_ 1951 APSU_PSU_AST_GST_Byte2 5000;
BA_ "NetworkRequest" SG_ 1951 APSU_PSU_AST_GST_Byte2 0;
BA_ "UserSigValidity" SG_ 1951 APSU_PSU_AST_GST_Byte2 0;
BA_ "UsrSigPurpose" SG_ 1951 APSU_PSU_AST_GST_Byte2 4;
BA_ "Description" SG_ 1951 APSU_PSU_AST_GST_Byte2 "TP Index : 109";
BA_ "Version" SG_ 1951 APSU_PSU_AST_GST_Byte3 "22.11.14";
BA_ "NetworkRequestHoldingTime" SG_ 1951 APSU_PSU_AST_GST_Byte3 5000;
BA_ "NetworkRequest" SG_ 1951 APSU_PSU_AST_GST_Byte3 0;
BA_ "UserSigValidity" SG_ 1951 APSU_PSU_AST_GST_Byte3 0;
BA_ "UsrSigPurpose" SG_ 1951 APSU_PSU_AST_GST_Byte3 4;
BA_ "Description" SG_ 1951 APSU_PSU_AST_GST_Byte3 "TP Index : 109";
BA_ "Version" SG_ 1951 APSU_PSU_AST_GST_Byte4 "22.11.14";
BA_ "NetworkRequestHoldingTime" SG_ 1951 APSU_PSU_AST_GST_Byte4 5000;
BA_ "NetworkRequest" SG_ 1951 APSU_PSU_AST_GST_Byte4 0;
BA_ "UserSigValidity" SG_ 1951 APSU_PSU_AST_GST_Byte4 0;
BA_ "UsrSigPurpose" SG_ 1951 APSU_PSU_AST_GST_Byte4 4;
BA_ "Description" SG_ 1951 APSU_PSU_AST_GST_Byte4 "TP Index : 109";
BA_ "Version" SG_ 1951 APSU_PSU_AST_GST_Byte5 "22.11.14";
BA_ "NetworkRequestHoldingTime" SG_ 1951 APSU_PSU_AST_GST_Byte5 5000;
BA_ "NetworkRequest" SG_ 1951 APSU_PSU_AST_GST_Byte5 0;
BA_ "UserSigValidity" SG_ 1951 APSU_PSU_AST_GST_Byte5 0;
BA_ "UsrSigPurpose" SG_ 1951 APSU_PSU_AST_GST_Byte5 4;
BA_ "Description" SG_ 1951 APSU_PSU_AST_GST_Byte5 "TP Index : 109";
BA_ "Version" SG_ 1951 APSU_PSU_AST_GST_Byte6 "22.11.14";
BA_ "NetworkRequestHoldingTime" SG_ 1951 APSU_PSU_AST_GST_Byte6 5000;
BA_ "NetworkRequest" SG_ 1951 APSU_PSU_AST_GST_Byte6 0;
BA_ "UserSigValidity" SG_ 1951 APSU_PSU_AST_GST_Byte6 0;
BA_ "UsrSigPurpose" SG_ 1951 APSU_PSU_AST_GST_Byte6 4;
BA_ "Description" SG_ 1951 APSU_PSU_AST_GST_Byte6 "TP Index : 109";
BA_ "Version" SG_ 1951 APSU_PSU_AST_GST_Byte7 "22.11.14";
BA_ "NetworkRequestHoldingTime" SG_ 1951 APSU_PSU_AST_GST_Byte7 5000;
BA_ "NetworkRequest" SG_ 1951 APSU_PSU_AST_GST_Byte7 0;
BA_ "UserSigValidity" SG_ 1951 APSU_PSU_AST_GST_Byte7 0;
BA_ "UsrSigPurpose" SG_ 1951 APSU_PSU_AST_GST_Byte7 4;
BA_ "Description" SG_ 1951 APSU_PSU_AST_GST_Byte7 "TP Index : 109";
BA_ "Version" SG_ 1951 APSU_PSU_AST_GST_Byte1 "22.11.14";
BA_ "NetworkRequestHoldingTime" SG_ 1951 APSU_PSU_AST_GST_Byte1 5000;
BA_ "NetworkRequest" SG_ 1951 APSU_PSU_AST_GST_Byte1 0;
BA_ "UserSigValidity" SG_ 1951 APSU_PSU_AST_GST_Byte1 0;
BA_ "UsrSigPurpose" SG_ 1951 APSU_PSU_AST_GST_Byte1 4;
BA_ "Description" SG_ 1951 APSU_PSU_AST_GST_Byte1 "TP Index : 109";
BA_ "Version" SG_ 977 SMK_Crc13Val "22.05.03";
BA_ "UserSigValidity" SG_ 977 SMK_Crc13Val 0;
BA_ "GenSigSendType" SG_ 977 SMK_Crc13Val 4;
BA_ "Description" SG_ 977 SMK_Crc13Val "The data area for CRC calculation is based on the data length (DLC) of the message DB.

The CRC shall be calculated over the entire data block (excluding the CRC bytes) including the user data, alive counter and Data ID 

 

- CRC Polynomial (0x1D) , Ini";
BA_ "Version" SG_ 977 SMK_TlPwrOnSta "24.04.03";
BA_ "UserSigValidity" SG_ 977 SMK_TlPwrOnSta 0;
BA_ "GenSigSendType" SG_ 977 SMK_TlPwrOnSta 4;
BA_ "Version" SG_ 977 SMK_AlvCnt13Val "22.05.03";
BA_ "UserSigValidity" SG_ 977 SMK_AlvCnt13Val 0;
BA_ "GenSigSendType" SG_ 977 SMK_AlvCnt13Val 4;
BA_ "Description" SG_ 977 SMK_AlvCnt13Val "For the first transmission request for a data element the counter shall be initialized with 0 and shall be incremented by 1

for every subsequent send request. When the counter reaches the maximum value(0xE), then it shall restart with 0 for the next sen";
BA_ "Version" SG_ 977 SMK_TrmnlCtrlGrpStaBDC "22.01.06";
BA_ "UserSigValidity" SG_ 977 SMK_TrmnlCtrlGrpStaBDC 0;
BA_ "GenSigSendType" SG_ 977 SMK_TrmnlCtrlGrpStaBDC 4;
BA_ "Description" SG_ 977 SMK_TrmnlCtrlGrpStaBDC "Mirror Value of TerminalControlGroupState(BDC)";
BA_ "Version" SG_ 977 SMK_TrmnlCtrlStaBDC "22.01.06";
BA_ "UserSigValidity" SG_ 977 SMK_TrmnlCtrlStaBDC 0;
BA_ "GenSigSendType" SG_ 977 SMK_TrmnlCtrlStaBDC 4;
BA_ "Description" SG_ 977 SMK_TrmnlCtrlStaBDC "Mirror Value of TerminalControlState(BDC)";
BA_ "Version" SG_ 977 SMK_TrmnlCtrlGrpStaBDCEV "23.07.04";
BA_ "UserSigValidity" SG_ 977 SMK_TrmnlCtrlGrpStaBDCEV 0;
BA_ "GenSigSendType" SG_ 977 SMK_TrmnlCtrlGrpStaBDCEV 4;
BA_ "Description" SG_ 977 SMK_TrmnlCtrlGrpStaBDCEV "Mirror Value of TerminalControlGroupState(BDC-EV)";
BA_ "Version" SG_ 977 SMK_TrmnlCtrlStaBDCEV "23.07.04";
BA_ "UserSigValidity" SG_ 977 SMK_TrmnlCtrlStaBDCEV 0;
BA_ "GenSigSendType" SG_ 977 SMK_TrmnlCtrlStaBDCEV 4;
BA_ "Description" SG_ 977 SMK_TrmnlCtrlStaBDCEV "Mirror Value of TerminalControlState(BDC EV)";
BA_ "Version" SG_ 977 SMK_PwrOnModeSta "23.07.04";
BA_ "UserSigValidity" SG_ 977 SMK_PwrOnModeSta 0;
BA_ "GenSigSendType" SG_ 977 SMK_PwrOnModeSta 4;
BA_ "Description" SG_ 977 SMK_PwrOnModeSta "Value of Power mode(BDC)";
BA_ "Version" SG_ 977 SMK_StndbyMdTmrMin "22.05.02";
BA_ "UserSigValidity" SG_ 977 SMK_StndbyMdTmrMin 0;
BA_ "GenSigSendType" SG_ 977 SMK_StndbyMdTmrMin 4;
BA_ "Description" SG_ 977 SMK_StndbyMdTmrMin "Information of Standby Mode timer";
BA_ "Version" SG_ 977 SMK_StndbyMdTmrSec "22.05.02";
BA_ "UserSigValidity" SG_ 977 SMK_StndbyMdTmrSec 0;
BA_ "GenSigSendType" SG_ 977 SMK_StndbyMdTmrSec 4;
BA_ "Description" SG_ 977 SMK_StndbyMdTmrSec "Information of Standby Mode Timer";
BA_ "Version" SG_ 977 SMK_EVPwrOffReq "23.04.05";
BA_ "UserSigValidity" SG_ 977 SMK_EVPwrOffReq 0;
BA_ "TimeoutValue" SG_ 977 SMK_EVPwrOffReq "0x0";
BA_ "GenSigSendType" SG_ 977 SMK_EVPwrOffReq 4;
BA_ "Description" SG_ 977 SMK_EVPwrOffReq "EV Power Off Request";
BA_ "Version" SG_ 977 SMK_RLHndLkSnsrSta "23.07.00";
BA_ "UserSigValidity" SG_ 977 SMK_RLHndLkSnsrSta 0;
BA_ "GenSigSendType" SG_ 977 SMK_RLHndLkSnsrSta 4;
BA_ "Description" SG_ 977 SMK_RLHndLkSnsrSta "Development for SMK

Rear Left Door Handle Lock Touch Sensor Signal";
BA_ "Version" SG_ 977 SMK_RLDrHndUnLkSnsrSta "23.07.00";
BA_ "UserSigValidity" SG_ 977 SMK_RLDrHndUnLkSnsrSta 0;
BA_ "GenSigSendType" SG_ 977 SMK_RLDrHndUnLkSnsrSta 4;
BA_ "Description" SG_ 977 SMK_RLDrHndUnLkSnsrSta "Development for SMK

Rear Left  Door Handle Unlock Touch Sensor Signal";
BA_ "Version" SG_ 977 SMK_RRDrHndLkSnsrSta "23.07.00";
BA_ "UserSigValidity" SG_ 977 SMK_RRDrHndLkSnsrSta 0;
BA_ "GenSigSendType" SG_ 977 SMK_RRDrHndLkSnsrSta 4;
BA_ "Description" SG_ 977 SMK_RRDrHndLkSnsrSta "Development for SMK

Rear Right Door Handle Lock Touch Sensor Signal";
BA_ "Version" SG_ 977 SMK_RRDrHndUnLkSnsrSta "23.07.00";
BA_ "UserSigValidity" SG_ 977 SMK_RRDrHndUnLkSnsrSta 0;
BA_ "GenSigSendType" SG_ 977 SMK_RRDrHndUnLkSnsrSta 4;
BA_ "Description" SG_ 977 SMK_RRDrHndUnLkSnsrSta "Development for SMK

Rear Right Door Handle Unlock Touch Sensor Signal";
BA_ "Version" SG_ 977 SMK_MaintenanceSrvMdReq "23.07.04";
BA_ "UserSigValidity" SG_ 977 SMK_MaintenanceSrvMdReq 0;
BA_ "TimeoutValue" SG_ 977 SMK_MaintenanceSrvMdReq "0x0";
BA_ "GenSigSendType" SG_ 977 SMK_MaintenanceSrvMdReq 4;
BA_ "Description" SG_ 977 SMK_MaintenanceSrvMdReq "Maintenance Service mode request from BDC to VCU";
BA_ "Version" SG_ 977 Auth_ISKLearnSta2 "24.04.03";
BA_ "UserSigValidity" SG_ 977 Auth_ISKLearnSta2 0;
BA_ "GenSigSendType" SG_ 977 Auth_ISKLearnSta2 4;
BA_ "Version" SG_ 977 Fob_FoundForChargingDoor "24.04.10";
BA_ "UserSigValidity" SG_ 977 Fob_FoundForChargingDoor 0;
BA_ "GenSigSendType" SG_ 977 Fob_FoundForChargingDoor 4;
BA_ "Description" SG_ 977 Fob_FoundForChargingDoor "Fob searching result for charging door open";
BA_ "Version" SG_ 977 Fob_FoundCabinArea "23.09.04";
BA_ "UserSigValidity" SG_ 977 Fob_FoundCabinArea 0;
BA_ "GenSigSendType" SG_ 977 Fob_FoundCabinArea 4;
BA_ "Description" SG_ 977 Fob_FoundCabinArea "Fob searching result in cabin area for SWA function

*SWA : Smart Walk Away Lock";
BA_ "Version" SG_ 983 BLTN_CAM_SWVerMajor "21.07.05";
BA_ "RoutingFactor" SG_ 983 BLTN_CAM_SWVerMajor 0;
BA_ "UserSigValidity" SG_ 983 BLTN_CAM_SWVerMajor 0;
BA_ "GenSigSendType" SG_ 983 BLTN_CAM_SWVerMajor 4;
BA_ "Description" SG_ 983 BLTN_CAM_SWVerMajor "Indicate the Built-in Cam software version as follows:

- The software version is displayed in seven digits.

- The Major, Minor1, Minor2, Minor3 digits are separated by '.'

- Major Signal value is transmitted to ASCII codes.

- Minor1/Minor2/Minor2 Sig";
BA_ "Version" SG_ 983 BLTN_CAM_SWVerMinor2 "21.07.05";
BA_ "RoutingFactor" SG_ 983 BLTN_CAM_SWVerMinor2 0;
BA_ "UserSigValidity" SG_ 983 BLTN_CAM_SWVerMinor2 0;
BA_ "GenSigSendType" SG_ 983 BLTN_CAM_SWVerMinor2 4;
BA_ "Description" SG_ 983 BLTN_CAM_SWVerMinor2 "Indicate the Built-in Cam software version as follows:

- The software version is displayed in seven digits.

- The Major, Minor1, Minor2, Minor3 digits are separated by '.'

- Major Signal value is transmitted to ASCII codes.

- Minor1/Minor2/Minor2 Sig";
BA_ "Version" SG_ 983 BLTN_CAM_SWVerMinor3 "21.07.05";
BA_ "RoutingFactor" SG_ 983 BLTN_CAM_SWVerMinor3 0;
BA_ "UserSigValidity" SG_ 983 BLTN_CAM_SWVerMinor3 0;
BA_ "GenSigSendType" SG_ 983 BLTN_CAM_SWVerMinor3 4;
BA_ "Description" SG_ 983 BLTN_CAM_SWVerMinor3 "Indicate the Built-in Cam software version as follows:

- The software version is displayed in seven digits.

- The Major, Minor1, Minor2, Minor3 digits are separated by '.'

- Major Signal value is transmitted to ASCII codes.

- Minor1/Minor2/Minor2 Sig";
BA_ "Version" SG_ 983 BLTN_CAM_SD_Card_Manufacturer "22.07.05";
BA_ "RoutingFactor" SG_ 983 BLTN_CAM_SD_Card_Manufacturer 0;
BA_ "UserSigValidity" SG_ 983 BLTN_CAM_SD_Card_Manufacturer 0;
BA_ "GenSigSendType" SG_ 983 BLTN_CAM_SD_Card_Manufacturer 4;
BA_ "Description" SG_ 983 BLTN_CAM_SD_Card_Manufacturer "Built-in Cam SD Card Manufacturer Information";
BA_ "Version" SG_ 983 BLTN_CAM_SD_Card_Cap_Class "22.07.05";
BA_ "RoutingFactor" SG_ 983 BLTN_CAM_SD_Card_Cap_Class 0;
BA_ "UserSigValidity" SG_ 983 BLTN_CAM_SD_Card_Cap_Class 0;
BA_ "GenSigSendType" SG_ 983 BLTN_CAM_SD_Card_Cap_Class 4;
BA_ "Description" SG_ 983 BLTN_CAM_SD_Card_Cap_Class "SD Card Storage Capacity Class";
BA_ "Version" SG_ 983 BLTN_CAM_SWVerMinor1 "21.07.05";
BA_ "RoutingFactor" SG_ 983 BLTN_CAM_SWVerMinor1 0;
BA_ "UserSigValidity" SG_ 983 BLTN_CAM_SWVerMinor1 0;
BA_ "GenSigSendType" SG_ 983 BLTN_CAM_SWVerMinor1 4;
BA_ "Description" SG_ 983 BLTN_CAM_SWVerMinor1 "Indicate the Built-in Cam software version as follows:

- The software version is displayed in seven digits.

- The Major, Minor1, Minor2, Minor3 digits are separated by '.'

- Major Signal value is transmitted to ASCII codes.

- Minor1/Minor2/Minor2 Sig";
BA_ "Version" SG_ 981 APSS_StExtFwdMvBtn "20.11.02";
BA_ "NetworkRequestHoldingTime" SG_ 981 APSS_StExtFwdMvBtn 5000;
BA_ "NetworkRequest" SG_ 981 APSS_StExtFwdMvBtn 0;
BA_ "UserSigValidity" SG_ 981 APSS_StExtFwdMvBtn 0;
BA_ "GenSigSendType" SG_ 981 APSS_StExtFwdMvBtn 4;
BA_ "Description" SG_ 981 APSS_StExtFwdMvBtn "Á¶¼ö¼® Äí¼Ç ÀÍ½ºÅÙ¼Ç Æ÷¿öµå ¹öÆ°";
BA_ "Version" SG_ 981 APSS_StSldFwdMvBtn "20.03.01";
BA_ "NetworkRequestHoldingTime" SG_ 981 APSS_StSldFwdMvBtn 5000;
BA_ "NetworkRequest" SG_ 981 APSS_StSldFwdMvBtn 0;
BA_ "UserSigValidity" SG_ 981 APSS_StSldFwdMvBtn 0;
BA_ "GenSigSendType" SG_ 981 APSS_StSldFwdMvBtn 4;
BA_ "Description" SG_ 981 APSS_StSldFwdMvBtn "Á¶¼ö¼® ½½¶óÀÌµù Æ÷¿öµå ¹öÆ°";
BA_ "Version" SG_ 981 APSS_StSldBwdMvBtn "20.03.01";
BA_ "NetworkRequestHoldingTime" SG_ 981 APSS_StSldBwdMvBtn 5000;
BA_ "NetworkRequest" SG_ 981 APSS_StSldBwdMvBtn 0;
BA_ "UserSigValidity" SG_ 981 APSS_StSldBwdMvBtn 0;
BA_ "GenSigSendType" SG_ 981 APSS_StSldBwdMvBtn 4;
BA_ "Description" SG_ 981 APSS_StSldBwdMvBtn "Á¶¼ö¼® ½½¶óÀÌµù ¹é¿öµå ¹öÆ°";
BA_ "Version" SG_ 981 APSS_StExtBwdMvBtn "20.11.02";
BA_ "NetworkRequestHoldingTime" SG_ 981 APSS_StExtBwdMvBtn 5000;
BA_ "NetworkRequest" SG_ 981 APSS_StExtBwdMvBtn 0;
BA_ "UserSigValidity" SG_ 981 APSS_StExtBwdMvBtn 0;
BA_ "GenSigSendType" SG_ 981 APSS_StExtBwdMvBtn 4;
BA_ "Description" SG_ 981 APSS_StExtBwdMvBtn "Á¶¼ö¼® Äí¼Ç ÀÍ½ºÅÙ¼Ç ¹é¿öµå ¹öÆ°";
BA_ "Version" SG_ 981 APSS_StRclFwdMvBtn "20.03.01";
BA_ "NetworkRequestHoldingTime" SG_ 981 APSS_StRclFwdMvBtn 5000;
BA_ "NetworkRequest" SG_ 981 APSS_StRclFwdMvBtn 0;
BA_ "UserSigValidity" SG_ 981 APSS_StRclFwdMvBtn 0;
BA_ "GenSigSendType" SG_ 981 APSS_StRclFwdMvBtn 4;
BA_ "Description" SG_ 981 APSS_StRclFwdMvBtn "Á¶¼ö¼® ¸®Å¬¶óÀÌ´× Æ÷¿öµå ¹öÆ°";
BA_ "Version" SG_ 981 APSS_StRclBwdMvBtn "20.03.01";
BA_ "NetworkRequestHoldingTime" SG_ 981 APSS_StRclBwdMvBtn 5000;
BA_ "NetworkRequest" SG_ 981 APSS_StRclBwdMvBtn 0;
BA_ "UserSigValidity" SG_ 981 APSS_StRclBwdMvBtn 0;
BA_ "GenSigSendType" SG_ 981 APSS_StRclBwdMvBtn 4;
BA_ "Description" SG_ 981 APSS_StRclBwdMvBtn "Á¶¼ö¼® ¸®Å¬¶óÀÌ´× ¹é¿öµå ¹öÆ°";
BA_ "Version" SG_ 981 APSS_StHgtUpMvBtn "20.03.01";
BA_ "NetworkRequestHoldingTime" SG_ 981 APSS_StHgtUpMvBtn 5000;
BA_ "NetworkRequest" SG_ 981 APSS_StHgtUpMvBtn 0;
BA_ "UserSigValidity" SG_ 981 APSS_StHgtUpMvBtn 0;
BA_ "GenSigSendType" SG_ 981 APSS_StHgtUpMvBtn 4;
BA_ "Description" SG_ 981 APSS_StHgtUpMvBtn "Á¶¼ö¼® ÇÏÀÌÆ® ¾÷ ¹öÆ°";
BA_ "Version" SG_ 981 APSS_StHgtDnMvBtn "20.03.01";
BA_ "NetworkRequestHoldingTime" SG_ 981 APSS_StHgtDnMvBtn 5000;
BA_ "NetworkRequest" SG_ 981 APSS_StHgtDnMvBtn 0;
BA_ "UserSigValidity" SG_ 981 APSS_StHgtDnMvBtn 0;
BA_ "GenSigSendType" SG_ 981 APSS_StHgtDnMvBtn 4;
BA_ "Description" SG_ 981 APSS_StHgtDnMvBtn "Á¶¼ö¼® ÇÏÀÌÆ® ´Ù¿î ¹öÆ°";
BA_ "Version" SG_ 981 APSS_StTltUpMvBtn "20.03.01";
BA_ "NetworkRequestHoldingTime" SG_ 981 APSS_StTltUpMvBtn 5000;
BA_ "NetworkRequest" SG_ 981 APSS_StTltUpMvBtn 0;
BA_ "UserSigValidity" SG_ 981 APSS_StTltUpMvBtn 0;
BA_ "GenSigSendType" SG_ 981 APSS_StTltUpMvBtn 4;
BA_ "Description" SG_ 981 APSS_StTltUpMvBtn "Á¶¼ö¼® Æ¿Æ® ¾÷ ¹öÆ°";
BA_ "Version" SG_ 981 APSS_StTltDnMvBtn "20.03.01";
BA_ "NetworkRequestHoldingTime" SG_ 981 APSS_StTltDnMvBtn 5000;
BA_ "NetworkRequest" SG_ 981 APSS_StTltDnMvBtn 0;
BA_ "UserSigValidity" SG_ 981 APSS_StTltDnMvBtn 0;
BA_ "GenSigSendType" SG_ 981 APSS_StTltDnMvBtn 4;
BA_ "Description" SG_ 981 APSS_StTltDnMvBtn "Á¶¼ö¼® Æ¿Æ® ´Ù¿î ¹öÆ°";
BA_ "Version" SG_ 981 APSS_StHRestUpMvBtn "20.03.01";
BA_ "NetworkRequestHoldingTime" SG_ 981 APSS_StHRestUpMvBtn 5000;
BA_ "NetworkRequest" SG_ 981 APSS_StHRestUpMvBtn 0;
BA_ "UserSigValidity" SG_ 981 APSS_StHRestUpMvBtn 0;
BA_ "GenSigSendType" SG_ 981 APSS_StHRestUpMvBtn 4;
BA_ "Description" SG_ 981 APSS_StHRestUpMvBtn "µ¿½Â¼® Çìµå·¹½ºÆ® up ¹öÆ°";
BA_ "Version" SG_ 981 APSS_StHRestDnMvBtn "20.03.01";
BA_ "NetworkRequestHoldingTime" SG_ 981 APSS_StHRestDnMvBtn 5000;
BA_ "NetworkRequest" SG_ 981 APSS_StHRestDnMvBtn 0;
BA_ "UserSigValidity" SG_ 981 APSS_StHRestDnMvBtn 0;
BA_ "GenSigSendType" SG_ 981 APSS_StHRestDnMvBtn 4;
BA_ "Description" SG_ 981 APSS_StHRestDnMvBtn "µ¿½Â¼® Çìµå·¹½ºÆ® down ¹öÆ°";
BA_ "Version" SG_ 981 APSS_StHRestFwdMvBtn "20.03.01";
BA_ "NetworkRequestHoldingTime" SG_ 981 APSS_StHRestFwdMvBtn 5000;
BA_ "NetworkRequest" SG_ 981 APSS_StHRestFwdMvBtn 0;
BA_ "UserSigValidity" SG_ 981 APSS_StHRestFwdMvBtn 0;
BA_ "GenSigSendType" SG_ 981 APSS_StHRestFwdMvBtn 4;
BA_ "Description" SG_ 981 APSS_StHRestFwdMvBtn "µ¿½Â¼® Çìµå·¹½ºÆ® fwd ¹öÆ°";
BA_ "Version" SG_ 981 APSS_StHRestBwdMvBtn "20.03.01";
BA_ "NetworkRequestHoldingTime" SG_ 981 APSS_StHRestBwdMvBtn 5000;
BA_ "NetworkRequest" SG_ 981 APSS_StHRestBwdMvBtn 0;
BA_ "UserSigValidity" SG_ 981 APSS_StHRestBwdMvBtn 0;
BA_ "GenSigSendType" SG_ 981 APSS_StHRestBwdMvBtn 4;
BA_ "Description" SG_ 981 APSS_StHRestBwdMvBtn "µ¿½Â¼® Çìµå·¹½ºÆ® BWD ¹öÆ°";
BA_ "Version" SG_ 981 APSS_StLegUpMvBtn "20.03.01";
BA_ "NetworkRequestHoldingTime" SG_ 981 APSS_StLegUpMvBtn 5000;
BA_ "NetworkRequest" SG_ 981 APSS_StLegUpMvBtn 0;
BA_ "UserSigValidity" SG_ 981 APSS_StLegUpMvBtn 0;
BA_ "GenSigSendType" SG_ 981 APSS_StLegUpMvBtn 4;
BA_ "Description" SG_ 981 APSS_StLegUpMvBtn "Á¶¼ö¼® ·¹±×·¹½ºÆ® ¾÷ ¹öÆ°";
BA_ "Version" SG_ 981 APSS_StLegDnMvBtn "20.03.01";
BA_ "NetworkRequestHoldingTime" SG_ 981 APSS_StLegDnMvBtn 5000;
BA_ "NetworkRequest" SG_ 981 APSS_StLegDnMvBtn 0;
BA_ "UserSigValidity" SG_ 981 APSS_StLegDnMvBtn 0;
BA_ "GenSigSendType" SG_ 981 APSS_StLegDnMvBtn 4;
BA_ "Description" SG_ 981 APSS_StLegDnMvBtn "Á¶¼ö¼® ·¹±×·¹½ºÆ® ´Ù¿î ¹öÆ°";
BA_ "Version" SG_ 981 APSS_StRlxModeBtn "20.03.01";
BA_ "NetworkRequestHoldingTime" SG_ 981 APSS_StRlxModeBtn 5000;
BA_ "NetworkRequest" SG_ 981 APSS_StRlxModeBtn 0;
BA_ "UserSigValidity" SG_ 981 APSS_StRlxModeBtn 0;
BA_ "GenSigSendType" SG_ 981 APSS_StRlxModeBtn 4;
BA_ "Description" SG_ 981 APSS_StRlxModeBtn "Á¶¼ö¼® ¸±·º½º ¸ðµå ¹öÆ°";
BA_ "Version" SG_ 981 APSS_StRlxReturnBtn "20.03.01";
BA_ "NetworkRequestHoldingTime" SG_ 981 APSS_StRlxReturnBtn 5000;
BA_ "NetworkRequest" SG_ 981 APSS_StRlxReturnBtn 0;
BA_ "UserSigValidity" SG_ 981 APSS_StRlxReturnBtn 0;
BA_ "GenSigSendType" SG_ 981 APSS_StRlxReturnBtn 4;
BA_ "Description" SG_ 981 APSS_StRlxReturnBtn "Á¶¼ö¼® ¸±·º½º ¸®ÅÏ ¹öÆ°";
BA_ "Version" SG_ 981 APSS_StRlxTltUpMvBtn "20.03.01";
BA_ "NetworkRequestHoldingTime" SG_ 981 APSS_StRlxTltUpMvBtn 5000;
BA_ "NetworkRequest" SG_ 981 APSS_StRlxTltUpMvBtn 0;
BA_ "UserSigValidity" SG_ 981 APSS_StRlxTltUpMvBtn 0;
BA_ "GenSigSendType" SG_ 981 APSS_StRlxTltUpMvBtn 4;
BA_ "Description" SG_ 981 APSS_StRlxTltUpMvBtn "Á¶¼ö¼® ¸±·º½º Æ¿Æ® ¾÷ ¹öÆ°";
BA_ "Version" SG_ 981 APSS_StRlxTltDnMvBtn "20.03.01";
BA_ "NetworkRequestHoldingTime" SG_ 981 APSS_StRlxTltDnMvBtn 5000;
BA_ "NetworkRequest" SG_ 981 APSS_StRlxTltDnMvBtn 0;
BA_ "UserSigValidity" SG_ 981 APSS_StRlxTltDnMvBtn 0;
BA_ "GenSigSendType" SG_ 981 APSS_StRlxTltDnMvBtn 4;
BA_ "Description" SG_ 981 APSS_StRlxTltDnMvBtn "Á¶¼ö¼® ¸±·º½º Æ¿Æ® ´Ù¿î ¹öÆ°";
BA_ "Version" SG_ 981 APSS_StAutoModeEnable "22.09.00";
BA_ "NetworkRequestHoldingTime" SG_ 981 APSS_StAutoModeEnable 5000;
BA_ "NetworkRequest" SG_ 981 APSS_StAutoModeEnable 0;
BA_ "UserSigValidity" SG_ 981 APSS_StAutoModeEnable 0;
BA_ "GenSigStartValue" SG_ 981 APSS_StAutoModeEnable 1;
BA_ "GenSigSendType" SG_ 981 APSS_StAutoModeEnable 4;
BA_ "Description" SG_ 981 APSS_StAutoModeEnable "1. Passenger seat one-touch operation signal 

2. In case ACU_CrashActvSta != 0x1, APSS_StAutoModeEnable == 0x1 (Auto Move Enable)

   In case ACU_CrashActvSta == 0x1, APSS_StAutoModeEnable == 0x2 (Auto Move Disable)";
BA_ "Version" SG_ 968 RCM_Crc3Val "22.05.03";
BA_ "UserSigValidity" SG_ 968 RCM_Crc3Val 0;
BA_ "GenSigSendType" SG_ 968 RCM_Crc3Val 4;
BA_ "Description" SG_ 968 RCM_Crc3Val "The data area for CRC calculation is based on the data length (DLC) of the message DB.

The CRC shall be calculated over the entire data block (excluding the CRC bytes) including the user data, alive counter and Data ID 

 

- CRC Polynomial (0x1D) , Ini";
BA_ "Version" SG_ 968 RCM_AlvCnt3Val "22.05.03";
BA_ "UserSigValidity" SG_ 968 RCM_AlvCnt3Val 0;
BA_ "GenSigSendType" SG_ 968 RCM_AlvCnt3Val 4;
BA_ "Description" SG_ 968 RCM_AlvCnt3Val "For the first transmission request for a data element the counter shall be initialized with 0 and shall be incremented by 1

for every subsequent send request. When the counter reaches the maximum value(0xE), then it shall restart with 0 for the next sen";
BA_ "Version" SG_ 968 RCM_BldOpSta "23.07.06";
BA_ "UserSigValidity" SG_ 968 RCM_BldOpSta 0;
BA_ "GenSigSendType" SG_ 968 RCM_BldOpSta 4;
BA_ "Description" SG_ 968 RCM_BldOpSta "Front Sunroof Blind Motor Operation Status";
BA_ "Version" SG_ 968 RCM_BldPosSta "22.01.02";
BA_ "UserSigValidity" SG_ 968 RCM_BldPosSta 0;
BA_ "GenSigSendType" SG_ 968 RCM_BldPosSta 4;
BA_ "Description" SG_ 968 RCM_BldPosSta "Sunroof Blind Position Status";
BA_ "Version" SG_ 968 RCM_BldFltSta "22.01.02";
BA_ "UserSigValidity" SG_ 968 RCM_BldFltSta 0;
BA_ "GenSigStartValue" SG_ 968 RCM_BldFltSta 2;
BA_ "GenSigSendType" SG_ 968 RCM_BldFltSta 4;
BA_ "Description" SG_ 968 RCM_BldFltSta "Sunroof Blind Fault Status";
BA_ "Version" SG_ 963 BCM_Crc16Val "21.09.03";
BA_ "UserSigValidity" SG_ 963 BCM_Crc16Val 0;
BA_ "GenSigSendType" SG_ 963 BCM_Crc16Val 4;
BA_ "Description" SG_ 963 BCM_Crc16Val "The data area for CRC calculation is based on the data length (DLC) of the message DB.

The CRC shall be calculated over the entire data block (excluding the CRC bytes) including the user data, alive counter and Data ID 

 

- CRC Polynomial (0x1D) , Ini";
BA_ "Version" SG_ 963 BCM_AlvCnt16Val "21.09.03";
BA_ "UserSigValidity" SG_ 963 BCM_AlvCnt16Val 0;
BA_ "GenSigSendType" SG_ 963 BCM_AlvCnt16Val 4;
BA_ "Description" SG_ 963 BCM_AlvCnt16Val "For the first transmission request for a data element the counter shall be initialized with 0 and shall be incremented by 1

for every subsequent send request. When the counter reaches the maximum value(0xE), then it shall restart with 0 for the next sen";
BA_ "Version" SG_ 963 IBU_SWVerMajor1 "20.12.04";
BA_ "UserSigValidity" SG_ 963 IBU_SWVerMajor1 0;
BA_ "GenSigSendType" SG_ 963 IBU_SWVerMajor1 4;
BA_ "Description" SG_ 963 IBU_SWVerMajor1 "Indicate the IBU software version as follows:

- The software version is displayed in three digits.

- The Major and Minor digits are separated by '.'

- Signal values are transmitted to ASCII codes.



¡Ø Example

C_IBU_SWVerMajor1 : 0x41 (HEX) -> ASCII";
BA_ "Version" SG_ 963 IBU_SWVerMinor1 "18.10.02";
BA_ "UserSigValidity" SG_ 963 IBU_SWVerMinor1 0;
BA_ "GenSigSendType" SG_ 963 IBU_SWVerMinor1 4;
BA_ "Description" SG_ 963 IBU_SWVerMinor1 "Indicate the IBU software version as follows:

- The software version is displayed in three digits.

- The Major and Minor digits are separated by '.'

- Signal values are transmitted to ASCII codes.



¡Ø Example

C_IBU_SWVerMajor1 : 0x41 (HEX) -> ASCII";
BA_ "Version" SG_ 963 IBU_SWVerMinor2 "18.10.02";
BA_ "UserSigValidity" SG_ 963 IBU_SWVerMinor2 0;
BA_ "GenSigSendType" SG_ 963 IBU_SWVerMinor2 4;
BA_ "Description" SG_ 963 IBU_SWVerMinor2 "Indicate the IBU software version as follows:

- The software version is displayed in three digits.

- The Major and Minor digits are separated by '.'

- Signal values are transmitted to ASCII codes.



¡Ø Example

C_IBU_SWVerMajor1 : 0x41 (HEX) -> ASCII";
BA_ "Version" SG_ 963 ECW_Fault "20.05.02";
BA_ "NetworkRequestHoldingTime" SG_ 963 ECW_Fault 5000;
BA_ "NetworkRequest" SG_ 963 ECW_Fault 0;
BA_ "UserSigValidity" SG_ 963 ECW_Fault 0;
BA_ "GenSigSendType" SG_ 963 ECW_Fault 4;
BA_ "Description" SG_ 963 ECW_Fault "ECW LIN to CAN Signal 

- LIN Signal Name : FAULT_ECW";
BA_ "Version" SG_ 963 ECW_FaultActv "20.05.02";
BA_ "NetworkRequestHoldingTime" SG_ 963 ECW_FaultActv 5000;
BA_ "NetworkRequest" SG_ 963 ECW_FaultActv 0;
BA_ "UserSigValidity" SG_ 963 ECW_FaultActv 0;
BA_ "GenSigStartValue" SG_ 963 ECW_FaultActv 1;
BA_ "GenSigSendType" SG_ 963 ECW_FaultActv 4;
BA_ "Description" SG_ 963 ECW_FaultActv "ECW LIN to CAN Signal

- LIN Signal Name : FAULT_ACTIVE";
BA_ "Version" SG_ 963 ECW_HiVolt "20.05.02";
BA_ "NetworkRequestHoldingTime" SG_ 963 ECW_HiVolt 5000;
BA_ "NetworkRequest" SG_ 963 ECW_HiVolt 0;
BA_ "UserSigValidity" SG_ 963 ECW_HiVolt 0;
BA_ "GenSigSendType" SG_ 963 ECW_HiVolt 4;
BA_ "Description" SG_ 963 ECW_HiVolt "ECW LIN to CAN Signal

- LIN Signal Name : HIGH_VOLT_ECW";
BA_ "Version" SG_ 963 ECW_HiVoltActv "20.05.02";
BA_ "NetworkRequestHoldingTime" SG_ 963 ECW_HiVoltActv 5000;
BA_ "NetworkRequest" SG_ 963 ECW_HiVoltActv 0;
BA_ "UserSigValidity" SG_ 963 ECW_HiVoltActv 0;
BA_ "GenSigStartValue" SG_ 963 ECW_HiVoltActv 1;
BA_ "GenSigSendType" SG_ 963 ECW_HiVoltActv 4;
BA_ "Description" SG_ 963 ECW_HiVoltActv "ECW LIN to CAN Signal

- LIN Signal Name : HIGH_VOLT_ACTIVE";
BA_ "Version" SG_ 963 ECW_LoVolt "20.05.02";
BA_ "NetworkRequestHoldingTime" SG_ 963 ECW_LoVolt 5000;
BA_ "NetworkRequest" SG_ 963 ECW_LoVolt 0;
BA_ "UserSigValidity" SG_ 963 ECW_LoVolt 0;
BA_ "GenSigSendType" SG_ 963 ECW_LoVolt 4;
BA_ "Description" SG_ 963 ECW_LoVolt "ECW LIN to CAN Signal

- LIN Signal Name : LOW_VOLT_ECW";
BA_ "Version" SG_ 963 ECW_LoVoltActv "20.05.02";
BA_ "NetworkRequestHoldingTime" SG_ 963 ECW_LoVoltActv 5000;
BA_ "NetworkRequest" SG_ 963 ECW_LoVoltActv 0;
BA_ "UserSigValidity" SG_ 963 ECW_LoVoltActv 0;
BA_ "GenSigStartValue" SG_ 963 ECW_LoVoltActv 1;
BA_ "GenSigSendType" SG_ 963 ECW_LoVoltActv 4;
BA_ "Description" SG_ 963 ECW_LoVoltActv "ECW LIN to CAN Signal

- LIN Signal Name : LOW_VOLT_ACTIVE";
BA_ "Version" SG_ 963 ECW_Overload "20.05.02";
BA_ "NetworkRequestHoldingTime" SG_ 963 ECW_Overload 5000;
BA_ "NetworkRequest" SG_ 963 ECW_Overload 0;
BA_ "UserSigValidity" SG_ 963 ECW_Overload 0;
BA_ "GenSigSendType" SG_ 963 ECW_Overload 4;
BA_ "Description" SG_ 963 ECW_Overload "ECW LIN to CAN Signal

- LIN Signal Name : OVERLOAD_ECW";
BA_ "Version" SG_ 963 ECW_OverloadActv "20.05.02";
BA_ "NetworkRequestHoldingTime" SG_ 963 ECW_OverloadActv 5000;
BA_ "NetworkRequest" SG_ 963 ECW_OverloadActv 0;
BA_ "UserSigValidity" SG_ 963 ECW_OverloadActv 0;
BA_ "GenSigStartValue" SG_ 963 ECW_OverloadActv 1;
BA_ "GenSigSendType" SG_ 963 ECW_OverloadActv 4;
BA_ "Description" SG_ 963 ECW_OverloadActv "ECW LIN to CAN Signal

- LIN Signal Name : OVERLOAD_ACTIVE";
BA_ "Version" SG_ 963 ECW_CommErr "20.05.02";
BA_ "NetworkRequestHoldingTime" SG_ 963 ECW_CommErr 5000;
BA_ "NetworkRequest" SG_ 963 ECW_CommErr 0;
BA_ "UserSigValidity" SG_ 963 ECW_CommErr 0;
BA_ "GenSigSendType" SG_ 963 ECW_CommErr 4;
BA_ "Description" SG_ 963 ECW_CommErr "ECW LIN to CAN Signal

- LIN Signal Name : ERR_COMM_ECW";
BA_ "Version" SG_ 963 SunRoof_RearBlindOprSta "20.07.00";
BA_ "UserSigValidity" SG_ 963 SunRoof_RearBlindOprSta 0;
BA_ "GenSigStartValue" SG_ 963 SunRoof_RearBlindOprSta 15;
BA_ "GenSigSendType" SG_ 963 SunRoof_RearBlindOprSta 4;
BA_ "Description" SG_ 963 SunRoof_RearBlindOprSta "Rear BlindPanel information (LIN to CAN signal)

- LIN Singal name : SunRoof_RearBlindOprSta";
BA_ "Version" SG_ 963 ECW_Overload2 "24.09.00";
BA_ "NetworkRequestHoldingTime" SG_ 963 ECW_Overload2 5000;
BA_ "NetworkRequest" SG_ 963 ECW_Overload2 0;
BA_ "UserSigValidity" SG_ 963 ECW_Overload2 0;
BA_ "GenSigSendType" SG_ 963 ECW_Overload2 4;
BA_ "Description" SG_ 963 ECW_Overload2 "ECW LIN to CAN Signal

 - SWI Option, OVERLOAD_ECW (2bit)";
BA_ "Version" SG_ 2172674052 AVH_Sta "17.12.00";
BA_ "RoutingFactor" SG_ 2172674052 AVH_Sta 0;
BA_ "UserSigValidity" SG_ 2172674052 AVH_Sta 3;
BA_ "Description" SG_ 2172674052 AVH_Sta "This signal indicates whether the vehicle is held with hydraulic brake (service brake).";
BA_ "Version" SG_ 2172674052 AVH_Slope_Status "21.08.05";
BA_ "RoutingFactor" SG_ 2172674052 AVH_Slope_Status 0;
BA_ "UserSigValidity" SG_ 2172674052 AVH_Slope_Status 3;
BA_ "Description" SG_ 2172674052 AVH_Slope_Status "This signal indicates whether the vehicle is held with hydraulic brake on the uphill.";
BA_ "Version" SG_ 2172674052 AVH_CluDis "21.10.03";
BA_ "RoutingFactor" SG_ 2172674052 AVH_CluDis 0;
BA_ "UserSigValidity" SG_ 2172674052 AVH_CluDis 3;
BA_ "Description" SG_ 2172674052 AVH_CluDis "An ESC can show its information message to driver on a cluster or a display module with this signal.";
BA_ "Version" SG_ 2172674052 LDM_Sta "17.12.00";
BA_ "RoutingFactor" SG_ 2172674052 LDM_Sta 0;
BA_ "UserSigValidity" SG_ 2172674052 LDM_Sta 3;
BA_ "Description" SG_ 2172674052 LDM_Sta "Information about ESC-Readiness to perform Dynamic Braking Function (DBF) or Automatic Vehicle Hold (AVH) which is requested by AVH switch.



LDM_STAT (0H)

 - EPB function : EPB is slave

LDM_STAT (1H)

 - EPB function : EPB stand alone";
BA_ "Version" SG_ 2172674052 AVH_AlrmReq "17.12.00";
BA_ "RoutingFactor" SG_ 2172674052 AVH_AlrmReq 0;
BA_ "UserSigValidity" SG_ 2172674052 AVH_AlrmReq 3;
BA_ "Description" SG_ 2172674052 AVH_AlrmReq "This signal indicates that an ESC requests cluster or tone controller to ring the alarm according to the status of an ESC";
BA_ "Version" SG_ 2172674052 AVH_ActvStaLmpDis "17.12.00";
BA_ "RoutingFactor" SG_ 2172674052 AVH_ActvStaLmpDis 0;
BA_ "UserSigValidity" SG_ 2172674052 AVH_ActvStaLmpDis 3;
BA_ "Description" SG_ 2172674052 AVH_ActvStaLmpDis "This signal indicates AVH active status lamp request from ESC to cluster.";
BA_ "Version" SG_ 2172674052 AVH_LmpDis "17.12.00";
BA_ "RoutingFactor" SG_ 2172674052 AVH_LmpDis 0;
BA_ "UserSigValidity" SG_ 2172674052 AVH_LmpDis 3;
BA_ "Description" SG_ 2172674052 AVH_LmpDis "Information about the status lamp request from ESC (AVH) to cluster.";
BA_ "Version" SG_ 2172674052 AWD_CrdnShftTqLimVal "17.12.00";
BA_ "RoutingFactor" SG_ 2172674052 AWD_CrdnShftTqLimVal 0;
BA_ "UserSigValidity" SG_ 2172674052 AWD_CrdnShftTqLimVal 3;
BA_ "GenSigStartValue" SG_ 2172674052 AWD_CrdnShftTqLimVal 64255;
BA_ "Description" SG_ 2172674052 AWD_CrdnShftTqLimVal "Interface signal between ABS/TCS/ESC and 4WD, demands 4WD cardan shaft torque limit.";
BA_ "Version" SG_ 2172674052 EPB_ActvReq "17.12.00";
BA_ "RoutingFactor" SG_ 2172674052 EPB_ActvReq 0;
BA_ "UserSigValidity" SG_ 2172674052 EPB_ActvReq 3;
BA_ "Description" SG_ 2172674052 EPB_ActvReq "This signal indicates that an ESC requests EPB to activate braking. 



REQ_EPB_ACT (0H)

 - AVH status : Don¡¯t care

REQ_EPB_ACT (1H)

 - AVH status : Active

REQ_EPB_ACT (2H)

 - AVH status : Active

REQ_EPB_ACT (3H)

 - AVH status : Disabled

(EPB St";
BA_ "Version" SG_ 2172674052 AWD_CltchDtyLimVal "17.12.00";
BA_ "RoutingFactor" SG_ 2172674052 AWD_CltchDtyLimVal 0;
BA_ "UserSigValidity" SG_ 2172674052 AWD_CltchDtyLimVal 3;
BA_ "Description" SG_ 2172674052 AWD_CltchDtyLimVal "Interface signal between ABS/TCS/ESC and 4WD and demands 4WD clutch duty limit.";
BA_ "Version" SG_ 2172674052 AWD_TransmsnTqLimModSta "17.12.00";
BA_ "RoutingFactor" SG_ 2172674052 AWD_TransmsnTqLimModSta 0;
BA_ "UserSigValidity" SG_ 2172674052 AWD_TransmsnTqLimModSta 3;
BA_ "Description" SG_ 2172674052 AWD_TransmsnTqLimModSta "This signal indicates that Interface signal between ESC and 4WD, selecting cardan shaft torque limitation mode of 4WD.";
BA_ "Version" SG_ 2172674052 AWD_RrWhlDtyLimReq "17.12.00";
BA_ "RoutingFactor" SG_ 2172674052 AWD_RrWhlDtyLimReq 0;
BA_ "UserSigValidity" SG_ 2172674052 AWD_RrWhlDtyLimReq 3;
BA_ "Description" SG_ 2172674052 AWD_RrWhlDtyLimReq "This signal indicates that ESC request 4WD ECU to limit control duty of rear wheels for improvement of stability of a vehicle during ESC control.";
BA_ "Version" SG_ 2172674052 EPB_StaReq "17.12.00";
BA_ "RoutingFactor" SG_ 2172674052 EPB_StaReq 0;
BA_ "UserSigValidity" SG_ 2172674052 EPB_StaReq 3;
BA_ "GenSigStartValue" SG_ 2172674052 EPB_StaReq 1;
BA_ "Description" SG_ 2172674052 EPB_StaReq "This signal indicates the validity of REQ_EPB_ACT (ESC request for EPB to activate braking) signal.";
BA_ "Version" SG_ 2172674052 AWD_FastOpnCrdnShftCltchReq "17.12.00";
BA_ "RoutingFactor" SG_ 2172674052 AWD_FastOpnCrdnShftCltchReq 0;
BA_ "UserSigValidity" SG_ 2172674052 AWD_FastOpnCrdnShftCltchReq 3;
BA_ "Description" SG_ 2172674052 AWD_FastOpnCrdnShftCltchReq "Interface signal between ESC and 4WD, demands fast opening or torque limit of the 4WD cardan shaft clutch.";
BA_ "Version" SG_ 2172674052 ECD_ActvSta "17.12.00";
BA_ "RoutingFactor" SG_ 2172674052 ECD_ActvSta 0;
BA_ "UserSigValidity" SG_ 2172674052 ECD_ActvSta 3;
BA_ "Description" SG_ 2172674052 ECD_ActvSta "ECD Active signal indicates whether ECD function is active (operating) or not.";
BA_ "Version" SG_ 2172674051 ESC_CylPrsrVal "17.12.00";
BA_ "RoutingFactor" SG_ 2172674051 ESC_CylPrsrVal 0;
BA_ "UserSigValidity" SG_ 2172674051 ESC_CylPrsrVal 3;
BA_ "Description" SG_ 2172674051 ESC_CylPrsrVal "This signal indicates pressure of brake master cylinder and provides information how deeply  a driver is pressing brake pedal.";
BA_ "Version" SG_ 2172674051 ESC_CylPrsrSta "18.02.00";
BA_ "RoutingFactor" SG_ 2172674051 ESC_CylPrsrSta 0;
BA_ "UserSigValidity" SG_ 2172674051 ESC_CylPrsrSta 3;
BA_ "GenSigStartValue" SG_ 2172674051 ESC_CylPrsrSta 1;
BA_ "Description" SG_ 2172674051 ESC_CylPrsrSta "This signal indicates validity of CYL_PRES signal.";
BA_ "Version" SG_ 2172674051 ESC_CylPrsrDiagSta "17.12.00";
BA_ "RoutingFactor" SG_ 2172674051 ESC_CylPrsrDiagSta 0;
BA_ "UserSigValidity" SG_ 2172674051 ESC_CylPrsrDiagSta 3;
BA_ "GenSigStartValue" SG_ 2172674051 ESC_CylPrsrDiagSta 1;
BA_ "Description" SG_ 2172674051 ESC_CylPrsrDiagSta "This signal indicates self-diagnosis mode of master cylinder pressure signal. During system check, master cylinder pressure information cannot be sent(not available) and this bit should be set to 1.";
BA_ "Version" SG_ 2172674051 ESC_CylPrsrFlagSta "17.12.00";
BA_ "RoutingFactor" SG_ 2172674051 ESC_CylPrsrFlagSta 0;
BA_ "UserSigValidity" SG_ 2172674051 ESC_CylPrsrFlagSta 3;
BA_ "Description" SG_ 2172674051 ESC_CylPrsrFlagSta "This signal means that the pressure of master cylinder is 15 bar or over.

(0x0 : under 15 bar, 0x1 : 15 bar or over)



This signal may be difference with actual BLS(Brake Lamp Switch) state.

So the ESC does not guarantee using this signal as substitut";
BA_ "Version" SG_ 2172674051 ESC_VsmActvSta "17.12.00";
BA_ "RoutingFactor" SG_ 2172674051 ESC_VsmActvSta 0;
BA_ "UserSigValidity" SG_ 2172674051 ESC_VsmActvSta 3;
BA_ "Description" SG_ 2172674051 ESC_VsmActvSta "ESC controller provides an information on VSM (ESC+MDPS) Active signal. It indicates VSM control is

active or inactive.";
BA_ "Version" SG_ 2172674051 ESC_VsmDfctvSta "17.12.00";
BA_ "RoutingFactor" SG_ 2172674051 ESC_VsmDfctvSta 0;
BA_ "UserSigValidity" SG_ 2172674051 ESC_VsmDfctvSta 3;
BA_ "Description" SG_ 2172674051 ESC_VsmDfctvSta "Information regarding the VSM ¡°defective¡± Indication";
BA_ "Version" SG_ 2172674051 ESC_VsmCtrlModSta "17.12.00";
BA_ "RoutingFactor" SG_ 2172674051 ESC_VsmCtrlModSta 0;
BA_ "UserSigValidity" SG_ 2172674051 ESC_VsmCtrlModSta 3;
BA_ "Description" SG_ 2172674051 ESC_VsmCtrlModSta "Classify mode1 , mode2 and mode3 of torque overlay. 

- Mode1 is sensor value overlay mode.

- Mode2 is output torque overlay mode. 

- Mode3 is for an alternative mode for Mobis VSM system";
BA_ "Version" SG_ 2172674051 ESC_StrTqReq "17.12.00";
BA_ "RoutingFactor" SG_ 2172674051 ESC_StrTqReq 0;
BA_ "UserSigValidity" SG_ 2172674051 ESC_StrTqReq 3;
BA_ "GenSigStartValue" SG_ 2172674051 ESC_StrTqReq 2048;
BA_ "Description" SG_ 2172674051 ESC_StrTqReq "Requested additional Assist torque of MDPS gets from ESC to make vehicle more stable.



Relationship between signals:

ESC_StrTrqReq = 0 Nm  ( DST inactive )

-> ESC_DstAct = 0, ESC_DstCtrMode = 0

ESC_StrTrqReq < 0 Nm  or  ESC_StrTrqReq > 0 Nm  (active";
BA_ "Version" SG_ 2172674051 TVC_ActSta "22.11.09";
BA_ "RoutingFactor" SG_ 2172674051 TVC_ActSta 0;
BA_ "UserSigValidity" SG_ 2172674051 TVC_ActSta 3;
BA_ "Description" SG_ 2172674051 TVC_ActSta "The signal of TVC_ActSta is purposed to notice to controllers as regarding to Touque vectoring control such as DTCH.";
BA_ "Version" SG_ 2172674051 ESC_LongAccelOffstCalibPrmtr "19.11.02";
BA_ "RoutingFactor" SG_ 2172674051 ESC_LongAccelOffstCalibPrmtr 0;
BA_ "UserSigValidity" SG_ 2172674051 ESC_LongAccelOffstCalibPrmtr 3;
BA_ "GenSigStartValue" SG_ 2172674051 ESC_LongAccelOffstCalibPrmtr 255;
BA_ "Description" SG_ 2172674051 ESC_LongAccelOffstCalibPrmtr "This signal indicates information regarding the calibration parameter for longitudinal acceleration value.

This signal doesn't guarantee the actual offset value.

But this signal is the result of the measuring process about the offset which is the longi";
BA_ "Version" SG_ 2172674051 ESC_IMURstStaAck "18.03.06";
BA_ "RoutingFactor" SG_ 2172674051 ESC_IMURstStaAck 0;
BA_ "UserSigValidity" SG_ 2172674051 ESC_IMURstStaAck 3;
BA_ "Description" SG_ 2172674051 ESC_IMURstStaAck "This signal is used to response for IMU sensor's reset status.

When the IMU sensor is about to reset, it will transmit the reset flag.

(After then the ACU will wait for acknowledge signal from ESC.)

If the ESC receive the reset flag from ACU, ESC will";
BA_ "Version" SG_ 967 RCM_Crc2Val "22.05.03";
BA_ "UserSigValidity" SG_ 967 RCM_Crc2Val 0;
BA_ "GenSigSendType" SG_ 967 RCM_Crc2Val 4;
BA_ "Description" SG_ 967 RCM_Crc2Val "The data area for CRC calculation is based on the data length (DLC) of the message DB.

The CRC shall be calculated over the entire data block (excluding the CRC bytes) including the user data, alive counter and Data ID 

 

- CRC Polynomial (0x1D) , Ini";
BA_ "Version" SG_ 967 RCM_AlvCnt2Val "22.05.03";
BA_ "UserSigValidity" SG_ 967 RCM_AlvCnt2Val 0;
BA_ "GenSigSendType" SG_ 967 RCM_AlvCnt2Val 4;
BA_ "Description" SG_ 967 RCM_AlvCnt2Val "For the first transmission request for a data element the counter shall be initialized with 0 and shall be incremented by 1

for every subsequent send request. When the counter reaches the maximum value(0xE), then it shall restart with 0 for the next sen";
BA_ "Version" SG_ 967 RCM_SunroofOpnSta "21.02.02";
BA_ "NetworkRequestHoldingTime" SG_ 967 RCM_SunroofOpnSta 5000;
BA_ "NetworkRequest" SG_ 967 RCM_SunroofOpnSta 0;
BA_ "UserSigValidity" SG_ 967 RCM_SunroofOpnSta 0;
BA_ "GenSigSendType" SG_ 967 RCM_SunroofOpnSta 4;
BA_ "Description" SG_ 967 RCM_SunroofOpnSta "Sunroof Glass Open Status";
BA_ "Version" SG_ 967 RCM_GlsOpSta "23.07.06";
BA_ "UserSigValidity" SG_ 967 RCM_GlsOpSta 0;
BA_ "GenSigSendType" SG_ 967 RCM_GlsOpSta 4;
BA_ "Description" SG_ 967 RCM_GlsOpSta "Front Sunroof Glass Motor Operation Status";
BA_ "Version" SG_ 967 RCM_GlsPosSta "23.07.06";
BA_ "UserSigValidity" SG_ 967 RCM_GlsPosSta 0;
BA_ "GenSigSendType" SG_ 967 RCM_GlsPosSta 4;
BA_ "Description" SG_ 967 RCM_GlsPosSta "Sunroof Glass Position Status";
BA_ "Version" SG_ 967 RCM_GlsFltSta "22.01.02";
BA_ "UserSigValidity" SG_ 967 RCM_GlsFltSta 0;
BA_ "GenSigStartValue" SG_ 967 RCM_GlsFltSta 2;
BA_ "GenSigSendType" SG_ 967 RCM_GlsFltSta 4;
BA_ "Description" SG_ 967 RCM_GlsFltSta "Sunroof Glass Fault Status";
BA_ "Version" SG_ 2172674050 TCS_Sta "18.12.01";
BA_ "RoutingFactor" SG_ 2172674050 TCS_Sta 0;
BA_ "UserSigValidity" SG_ 2172674050 TCS_Sta 3;
BA_ "Description" SG_ 2172674050 TCS_Sta "Information regarding the status of TCS function.



If the function has not been coded(fixed) yet, this signal will be transmitted as 0xE.



If the vehicle has been applied only ABS(without ESC), this signal will be fixed as 0x0.";
BA_ "Version" SG_ 2172674050 TCS_PreActvSta "17.12.00";
BA_ "RoutingFactor" SG_ 2172674050 TCS_PreActvSta 0;
BA_ "UserSigValidity" SG_ 2172674050 TCS_PreActvSta 3;
BA_ "Description" SG_ 2172674050 TCS_PreActvSta "Pre TCS Control Signal";
BA_ "Version" SG_ 2172674050 DBC_Sta "18.12.01";
BA_ "RoutingFactor" SG_ 2172674050 DBC_Sta 0;
BA_ "UserSigValidity" SG_ 2172674050 DBC_Sta 3;
BA_ "Description" SG_ 2172674050 DBC_Sta "Information regarding the status of DBC function.



If the function has not been coded(fixed) yet, this signal will be transmitted as 0xE.";
BA_ "Version" SG_ 2172674050 TCS_TqFlag "18.07.01";
BA_ "RoutingFactor" SG_ 2172674050 TCS_TqFlag 0;
BA_ "UserSigValidity" SG_ 2172674050 TCS_TqFlag 3;
BA_ "Description" SG_ 2172674050 TCS_TqFlag "Flag indicating positive or negative TCS Intervention";
BA_ "Version" SG_ 2172674050 MSR_TqFlag "18.07.01";
BA_ "RoutingFactor" SG_ 2172674050 MSR_TqFlag 0;
BA_ "UserSigValidity" SG_ 2172674050 MSR_TqFlag 3;
BA_ "Description" SG_ 2172674050 MSR_TqFlag "Flag indicating positive or negative MSR Intervention";
BA_ "Version" SG_ 2172674050 HAC_Sta "18.12.01";
BA_ "RoutingFactor" SG_ 2172674050 HAC_Sta 0;
BA_ "UserSigValidity" SG_ 2172674050 HAC_Sta 3;
BA_ "Description" SG_ 2172674050 HAC_Sta "Information regarding the status of HAC function.



If the function has not been coded(fixed) yet, this signal wilil be transmitted as 0xE.";
BA_ "Version" SG_ 2172674050 BJD_Flag "20.04.02";
BA_ "RoutingFactor" SG_ 2172674050 BJD_Flag 0;
BA_ "UserSigValidity" SG_ 2172674050 BJD_Flag 3;
BA_ "Description" SG_ 2172674050 BJD_Flag "Judder Detection Flag

0x0(No Event), 0x1(Event)";
BA_ "Version" SG_ 2172674050 TCS_SlwTqFlag "18.07.01";
BA_ "RoutingFactor" SG_ 2172674050 TCS_SlwTqFlag 0;
BA_ "UserSigValidity" SG_ 2172674050 TCS_SlwTqFlag 3;
BA_ "Description" SG_ 2172674050 TCS_SlwTqFlag "Flag indicating positive or negative SLOW TCS Intervention";
BA_ "Version" SG_ 2172674050 TCS_Req "17.12.00";
BA_ "RoutingFactor" SG_ 2172674050 TCS_Req 0;
BA_ "UserSigValidity" SG_ 2172674050 TCS_Req 3;
BA_ "Description" SG_ 2172674050 TCS_Req "Request for an indicated desired engine torque, the combination of signals calls, on the one hand, for a desire for charge reduction (TCS or ESC function), and, on the other hand, for a desire for charge increase (MSR function).



TCS_REQ : Identifies a";
BA_ "Version" SG_ 2172674050 MSR_FuncReq "17.12.00";
BA_ "RoutingFactor" SG_ 2172674050 MSR_FuncReq 0;
BA_ "UserSigValidity" SG_ 2172674050 MSR_FuncReq 3;
BA_ "Description" SG_ 2172674050 MSR_FuncReq "Request for an indicated desired engine torque, the combination of signals calls, on the one hand, for a desire for charge reduction (TCS or ESC function), and, on the other hand, for a desire for charge increase (MSR function).



MSR_C_REQ : Identifies";
BA_ "Version" SG_ 2172674050 TCS_GearShftCharacteristicVal "17.12.00";
BA_ "RoutingFactor" SG_ 2172674050 TCS_GearShftCharacteristicVal 0;
BA_ "UserSigValidity" SG_ 2172674050 TCS_GearShftCharacteristicVal 3;
BA_ "Description" SG_ 2172674050 TCS_GearShftCharacteristicVal "Interface signal between TCS/ESC and TCU influencing the TCU switching characteristics in the case of an TCS control system.";
BA_ "Version" SG_ 2172674050 TCS_ManufacturerVal "17.12.00";
BA_ "RoutingFactor" SG_ 2172674050 TCS_ManufacturerVal 0;
BA_ "UserSigValidity" SG_ 2172674050 TCS_ManufacturerVal 3;
BA_ "Description" SG_ 2172674050 TCS_ManufacturerVal "TCS manufacturer information to distinguish between a system which requires only TQI_TCS function and a system which requires both TQI_TCS and TQI_SLW_TCS functions. This signal indicates that TCS requests torque reduction using only TQI_TCS or using bot";
BA_ "Version" SG_ 2172674050 TCS_TqIntrvntnVal "17.12.00";
BA_ "RoutingFactor" SG_ 2172674050 TCS_TqIntrvntnVal 0;
BA_ "UserSigValidity" SG_ 2172674050 TCS_TqIntrvntnVal 3;
BA_ "GenSigStartValue" SG_ 2172674050 TCS_TqIntrvntnVal 255;
BA_ "Description" SG_ 2172674050 TCS_TqIntrvntnVal "Request for an indicated desired engine torque, the combination of signals calls, on the one hand, for a desire for charge reduction (TCS or ESC function), and, on the other hand, for a desire for charge increase (MSR function).



TQI_TCS : Torque reduc";
BA_ "Version" SG_ 2172674050 MSR_TqIntrvntnVal "17.12.00";
BA_ "RoutingFactor" SG_ 2172674050 MSR_TqIntrvntnVal 0;
BA_ "UserSigValidity" SG_ 2172674050 MSR_TqIntrvntnVal 3;
BA_ "Description" SG_ 2172674050 MSR_TqIntrvntnVal "Request for an indicated desired engine torque, the combination of signals calls, on the one hand, for a desire for charge reduction (TCS or ESC function), and, on the other hand, for a desire for charge increase (MSR function).



TQI_MSR : The torque i";
BA_ "Version" SG_ 2172674050 TCS_SlwTqIntrvntnVal "17.12.00";
BA_ "RoutingFactor" SG_ 2172674050 TCS_SlwTqIntrvntnVal 0;
BA_ "UserSigValidity" SG_ 2172674050 TCS_SlwTqIntrvntnVal 3;
BA_ "GenSigStartValue" SG_ 2172674050 TCS_SlwTqIntrvntnVal 255;
BA_ "Description" SG_ 2172674050 TCS_SlwTqIntrvntnVal "Request for an indicated desired engine torque, the combination of signals calls, on the one hand, for a desire for charge reduction (TCS or ESC function), and, on the other hand, for a desire for charge increase (MSR function).



TQI_SLW_TCS : The driv";
BA_ "Version" SG_ 2172674050 ESC_Sta "18.12.01";
BA_ "RoutingFactor" SG_ 2172674050 ESC_Sta 0;
BA_ "UserSigValidity" SG_ 2172674050 ESC_Sta 3;
BA_ "Description" SG_ 2172674050 ESC_Sta "Information regarding the status of ESC function.



If the function has not been coded(fixed) yet, this signal will be transmitted as 0xE.



If the vehicle has been applied only ABS(without ESC), this signal will be fixed as 0x0.";
BA_ "Version" SG_ 966 RCM_Crc1Val "22.05.03";
BA_ "UserSigValidity" SG_ 966 RCM_Crc1Val 0;
BA_ "GenSigSendType" SG_ 966 RCM_Crc1Val 4;
BA_ "Description" SG_ 966 RCM_Crc1Val "The data area for CRC calculation is based on the data length (DLC) of the message DB.

The CRC shall be calculated over the entire data block (excluding the CRC bytes) including the user data, alive counter and Data ID 

 

- CRC Polynomial (0x1D) , Ini";
BA_ "Version" SG_ 966 RCM_AlvCnt1Val "22.05.03";
BA_ "UserSigValidity" SG_ 966 RCM_AlvCnt1Val 0;
BA_ "GenSigSendType" SG_ 966 RCM_AlvCnt1Val 4;
BA_ "Description" SG_ 966 RCM_AlvCnt1Val "For the first transmission request for a data element the counter shall be initialized with 0 and shall be incremented by 1

for every subsequent send request. When the counter reaches the maximum value(0xE), then it shall restart with 0 for the next sen";
BA_ "Version" SG_ 966 RCM_OptTyp "21.02.02";
BA_ "UserSigValidity" SG_ 966 RCM_OptTyp 0;
BA_ "GenSigSendType" SG_ 966 RCM_OptTyp 4;
BA_ "Description" SG_ 966 RCM_OptTyp "RCM (Roof Control Module) Option Type";
BA_ "Version" SG_ 966 RCM_TunnelOptType "22.02.02";
BA_ "UserSigValidity" SG_ 966 RCM_TunnelOptType 0;
BA_ "GenSigSendType" SG_ 966 RCM_TunnelOptType 4;
BA_ "Description" SG_ 966 RCM_TunnelOptType "Sunroof RCM Tunnel Option Type

0x0 : Sunroof Option is not applied or Navi_AirConditionWarning is not applied

0x1 : both conditions are applied.

0x2 : Sunroof Error is occurred or Not Initialized / Initialization Fail";
BA_ "Version" SG_ 2172674049 ESC_Crc1Val "21.09.03";
BA_ "RoutingFactor" SG_ 2172674049 ESC_Crc1Val 0;
BA_ "UserSigValidity" SG_ 2172674049 ESC_Crc1Val 3;
BA_ "GenSigStartValue" SG_ 2172674049 ESC_Crc1Val 65535;
BA_ "Description" SG_ 2172674049 ESC_Crc1Val "The data area for CRC calculation is based on the data length (DLC) of the message DB.

The CRC shall be calculated over the entire data block (excluding the CRC bytes) including the user data, alive counter and Data ID



- CRC Polynomial (0x1021) , Ini";
BA_ "Version" SG_ 2172674049 ESC_AlvCnt1Val "21.09.03";
BA_ "RoutingFactor" SG_ 2172674049 ESC_AlvCnt1Val 0;
BA_ "UserSigValidity" SG_ 2172674049 ESC_AlvCnt1Val 3;
BA_ "Description" SG_ 2172674049 ESC_AlvCnt1Val "For the first transmission request for a data element the counter shall be initialized with 0 and shall be incremented by 1 for every subsequent send request. 

When the counter reaches the maximum value(0xFF), then it shall restart with 0 for the next s";
BA_ "Version" SG_ 2172674049 ESC_CltchPdStrkSnsrDuty "24.07.06";
BA_ "RoutingFactor" SG_ 2172674049 ESC_CltchPdStrkSnsrDuty 0;
BA_ "UserSigValidity" SG_ 2172674049 ESC_CltchPdStrkSnsrDuty 3;
BA_ "Description" SG_ 2172674049 ESC_CltchPdStrkSnsrDuty "Clutch Pedal Stroke Sensor Duty signal By-pass value (only for MT-SCC Function)";
BA_ "Version" SG_ 2172674049 TCS_LmpSta "17.12.00";
BA_ "RoutingFactor" SG_ 2172674049 TCS_LmpSta 0;
BA_ "UserSigValidity" SG_ 2172674049 TCS_LmpSta 3;
BA_ "Description" SG_ 2172674049 TCS_LmpSta "The signal indicates the status of the ¡°TCS/ESC Function/Warning Lamp¡±";
BA_ "Version" SG_ 2172674049 TCS_OffLmpSta "17.12.00";
BA_ "RoutingFactor" SG_ 2172674049 TCS_OffLmpSta 0;
BA_ "UserSigValidity" SG_ 2172674049 TCS_OffLmpSta 3;
BA_ "Description" SG_ 2172674049 TCS_OffLmpSta "The signal indicates the status of the ¡°TCS/ESC OFF SW Lamp¡±";
BA_ "Version" SG_ 2172674049 ESC_OffTempSta "17.12.00";
BA_ "RoutingFactor" SG_ 2172674049 ESC_OffTempSta 0;
BA_ "UserSigValidity" SG_ 2172674049 ESC_OffTempSta 3;
BA_ "Description" SG_ 2172674049 ESC_OffTempSta "Information regarding the ESC OFF step by switch input of driver.";
BA_ "Version" SG_ 2172674049 ESC_OffSwSta "20.05.02";
BA_ "RoutingFactor" SG_ 2172674049 ESC_OffSwSta 0;
BA_ "UserSigValidity" SG_ 2172674049 ESC_OffSwSta 3;
BA_ "Description" SG_ 2172674049 ESC_OffSwSta "This signal is to indicate the esc off switch is pressed or not.";
BA_ "Version" SG_ 2172674049 DBC_WrngLmpSta "17.12.00";
BA_ "RoutingFactor" SG_ 2172674049 DBC_WrngLmpSta 0;
BA_ "UserSigValidity" SG_ 2172674049 DBC_WrngLmpSta 3;
BA_ "Description" SG_ 2172674049 DBC_WrngLmpSta "The signal indicates the status of the ¡°DBC Warning lamp¡±";
BA_ "Version" SG_ 2172674049 DBC_FuncLmpSta "17.12.00";
BA_ "RoutingFactor" SG_ 2172674049 DBC_FuncLmpSta 0;
BA_ "UserSigValidity" SG_ 2172674049 DBC_FuncLmpSta 3;
BA_ "Description" SG_ 2172674049 DBC_FuncLmpSta "The signal indicates the status of the ¡°DBC Function lamp¡±";
BA_ "Version" SG_ 2172674049 DBC_ClusterDis "18.07.03";
BA_ "RoutingFactor" SG_ 2172674049 DBC_ClusterDis 0;
BA_ "UserSigValidity" SG_ 2172674049 DBC_ClusterDis 3;
BA_ "Description" SG_ 2172674049 DBC_ClusterDis "DBC Pop-up Signal for Deactivation";
BA_ "Version" SG_ 2172674049 ESC_SprtLmpSta "20.10.00";
BA_ "RoutingFactor" SG_ 2172674049 ESC_SprtLmpSta 0;
BA_ "UserSigValidity" SG_ 2172674049 ESC_SprtLmpSta 3;
BA_ "Description" SG_ 2172674049 ESC_SprtLmpSta "This signal indicates the status of the 'ESC SPORT Lamp'";
BA_ "Version" SG_ 2172674049 ESC_BrkCtrlSta "17.12.00";
BA_ "RoutingFactor" SG_ 2172674049 ESC_BrkCtrlSta 0;
BA_ "UserSigValidity" SG_ 2172674049 ESC_BrkCtrlSta 3;
BA_ "Description" SG_ 2172674049 ESC_BrkCtrlSta "This signal indicates that if brake control from the ECU request is in activation or not  during cruise control or speed limiter.";
BA_ "Version" SG_ 2172674049 ESC_MyDrive_CodingSta "23.10.02";
BA_ "RoutingFactor" SG_ 2172674049 ESC_MyDrive_CodingSta 0;
BA_ "UserSigValidity" SG_ 2172674049 ESC_MyDrive_CodingSta 3;
BA_ "Description" SG_ 2172674049 ESC_MyDrive_CodingSta "This signal informs you of the recognition status and type of ESC OFF switch cooperative control specification for My Drive Mode.

0x0 : This value is not used

0x1 : This value means ttat There is no ESC OFF switch cooperative control specification for ";
BA_ "Version" SG_ 2172674049 ESC_OffSwSta2 "23.10.02";
BA_ "RoutingFactor" SG_ 2172674049 ESC_OffSwSta2 0;
BA_ "UserSigValidity" SG_ 2172674049 ESC_OffSwSta2 3;
BA_ "Description" SG_ 2172674049 ESC_OffSwSta2 "When driver push the ESC OFF switch, This signal informs that switch is pushed shortly or long.

Refer to Attachments to find out definition of Short Click and Long Click.

0x0 : ESC OFF switch has not be pushed.

0x1 : ESC OFF switch has be pushed short";
BA_ "UserSigValidity" SG_ 1301 Destination_WPC2 0;
BA_ "UsrSigPurpose" SG_ 1301 Destination_WPC2 9;
BA_ "UserSigValidity" SG_ 1301 NMCommandCode_WPC2 0;
BA_ "UsrSigPurpose" SG_ 1301 NMCommandCode_WPC2 9;
BA_ "UserSigValidity" SG_ 1301 NMSleepFlag_WPC2 0;
BA_ "UsrSigPurpose" SG_ 1301 NMSleepFlag_WPC2 9;
BA_ "UserSigValidity" SG_ 1345 Destination_PSB 0;
BA_ "UsrSigPurpose" SG_ 1345 Destination_PSB 9;
BA_ "UserSigValidity" SG_ 1345 NMCommandCode_PSB 0;
BA_ "UsrSigPurpose" SG_ 1345 NMCommandCode_PSB 9;
BA_ "UserSigValidity" SG_ 1345 NMSleepFlag_PSB 0;
BA_ "UsrSigPurpose" SG_ 1345 NMSleepFlag_PSB 9;
BA_ "UserSigValidity" SG_ 1323 Destination_SHVU_RR 0;
BA_ "UsrSigPurpose" SG_ 1323 Destination_SHVU_RR 9;
BA_ "UserSigValidity" SG_ 1323 NMCommandCode_SHVU_RR 0;
BA_ "UsrSigPurpose" SG_ 1323 NMCommandCode_SHVU_RR 9;
BA_ "UserSigValidity" SG_ 1323 NMSleepFlag_SHVU_RR 0;
BA_ "UsrSigPurpose" SG_ 1323 NMSleepFlag_SHVU_RR 9;
BA_ "UserSigValidity" SG_ 1313 Destination_FCS 0;
BA_ "UsrSigPurpose" SG_ 1313 Destination_FCS 9;
BA_ "UserSigValidity" SG_ 1313 NMCommandCode_FCS 0;
BA_ "UsrSigPurpose" SG_ 1313 NMCommandCode_FCS 9;
BA_ "UserSigValidity" SG_ 1313 NMSleepFlag_FCS 0;
BA_ "UsrSigPurpose" SG_ 1313 NMSleepFlag_FCS 9;
BA_ "UserSigValidity" SG_ 1297 Destination_EMCU 0;
BA_ "UsrSigPurpose" SG_ 1297 Destination_EMCU 9;
BA_ "UserSigValidity" SG_ 1297 NMCommandCode_EMCU 0;
BA_ "UsrSigPurpose" SG_ 1297 NMCommandCode_EMCU 9;
BA_ "UserSigValidity" SG_ 1297 NMSleepFlag_EMCU 0;
BA_ "UsrSigPurpose" SG_ 1297 NMSleepFlag_EMCU 9;
BA_ "UserSigValidity" SG_ 1307 Destination_SLB 0;
BA_ "UsrSigPurpose" SG_ 1307 Destination_SLB 9;
BA_ "UserSigValidity" SG_ 1307 NMCommandCode_SLB 0;
BA_ "UsrSigPurpose" SG_ 1307 NMCommandCode_SLB 9;
BA_ "UserSigValidity" SG_ 1307 NMSleepFlag_SLB 0;
BA_ "UsrSigPurpose" SG_ 1307 NMSleepFlag_SLB 9;
BA_ "UserSigValidity" SG_ 1329 Destination_GW_APSU 0;
BA_ "UsrSigPurpose" SG_ 1329 Destination_GW_APSU 9;
BA_ "UserSigValidity" SG_ 1329 NMCommandCode_GW_APSU 0;
BA_ "UsrSigPurpose" SG_ 1329 NMCommandCode_GW_APSU 9;
BA_ "UserSigValidity" SG_ 1329 NMSleepFlag_GW_APSU 0;
BA_ "UsrSigPurpose" SG_ 1329 NMSleepFlag_GW_APSU 9;
BA_ "UserSigValidity" SG_ 1344 Destination_GW_DLBCU 0;
BA_ "UsrSigPurpose" SG_ 1344 Destination_GW_DLBCU 9;
BA_ "UserSigValidity" SG_ 1344 NMCommandCode_GW_DLBCU 0;
BA_ "UsrSigPurpose" SG_ 1344 NMCommandCode_GW_DLBCU 9;
BA_ "UserSigValidity" SG_ 1344 NMSleepFlag_GW_DLBCU 0;
BA_ "UsrSigPurpose" SG_ 1344 NMSleepFlag_GW_DLBCU 9;
BA_ "UserSigValidity" SG_ 1341 Destination_RCM 0;
BA_ "UsrSigPurpose" SG_ 1341 Destination_RCM 9;
BA_ "UserSigValidity" SG_ 1341 NMCommandCode_RCM 0;
BA_ "UsrSigPurpose" SG_ 1341 NMCommandCode_RCM 9;
BA_ "UserSigValidity" SG_ 1341 NMSleepFlag_RCM 0;
BA_ "UsrSigPurpose" SG_ 1341 NMSleepFlag_RCM 9;
BA_ "UserSigValidity" SG_ 1290 Destination_ARS 0;
BA_ "UsrSigPurpose" SG_ 1290 Destination_ARS 9;
BA_ "UserSigValidity" SG_ 1290 NMCommandCode_ARS 0;
BA_ "UsrSigPurpose" SG_ 1290 NMCommandCode_ARS 9;
BA_ "UserSigValidity" SG_ 1290 NMSleepFlag_ARS 0;
BA_ "UsrSigPurpose" SG_ 1290 NMSleepFlag_ARS 9;
BA_ "UserSigValidity" SG_ 1392 Destination_CGW_CCU 0;
BA_ "UsrSigPurpose" SG_ 1392 Destination_CGW_CCU 9;
BA_ "UserSigValidity" SG_ 1392 NMCommandCode_CGW_CCU 0;
BA_ "UsrSigPurpose" SG_ 1392 NMCommandCode_CGW_CCU 9;
BA_ "UserSigValidity" SG_ 1392 NMSleepFlag_CGW_CCU 0;
BA_ "UsrSigPurpose" SG_ 1392 NMSleepFlag_CGW_CCU 9;
BA_ "UserSigValidity" SG_ 1308 Destination_GW_RLPSU 0;
BA_ "UsrSigPurpose" SG_ 1308 Destination_GW_RLPSU 9;
BA_ "UserSigValidity" SG_ 1308 NMCommandCode_GW_RLPSU 0;
BA_ "UsrSigPurpose" SG_ 1308 NMCommandCode_GW_RLPSU 9;
BA_ "UserSigValidity" SG_ 1308 NMSleepFlag_GW_RLPSU 0;
BA_ "UsrSigPurpose" SG_ 1308 NMSleepFlag_GW_RLPSU 9;
BA_ "UserSigValidity" SG_ 1360 Destination_ATS 0;
BA_ "UsrSigPurpose" SG_ 1360 Destination_ATS 9;
BA_ "UserSigValidity" SG_ 1360 NMCommandCode_ATS 0;
BA_ "UsrSigPurpose" SG_ 1360 NMCommandCode_ATS 9;
BA_ "UserSigValidity" SG_ 1360 NMSleepFlag_ATS 0;
BA_ "UsrSigPurpose" SG_ 1360 NMSleepFlag_ATS 9;
BA_ "UserSigValidity" SG_ 1332 Destination_RLHV 0;
BA_ "UsrSigPurpose" SG_ 1332 Destination_RLHV 9;
BA_ "UserSigValidity" SG_ 1332 NMCommandCode_RLHV 0;
BA_ "UsrSigPurpose" SG_ 1332 NMCommandCode_RLHV 9;
BA_ "UserSigValidity" SG_ 1332 NMSleepFlag_RLHV 0;
BA_ "UsrSigPurpose" SG_ 1332 NMSleepFlag_RLHV 9;
BA_ "UserSigValidity" SG_ 1342 Destination_SGU 0;
BA_ "UsrSigPurpose" SG_ 1342 Destination_SGU 9;
BA_ "UserSigValidity" SG_ 1342 NMCommandCode_SGU 0;
BA_ "UsrSigPurpose" SG_ 1342 NMCommandCode_SGU 9;
BA_ "UserSigValidity" SG_ 1342 NMSleepFlag_SGU 0;
BA_ "UsrSigPurpose" SG_ 1342 NMSleepFlag_SGU 9;
BA_ "UserSigValidity" SG_ 1325 Destination_PFSU 0;
BA_ "UsrSigPurpose" SG_ 1325 Destination_PFSU 9;
BA_ "UserSigValidity" SG_ 1325 NMCommandCode_PFSU 0;
BA_ "UsrSigPurpose" SG_ 1325 NMCommandCode_PFSU 9;
BA_ "UserSigValidity" SG_ 1325 NMSleepFlag_PFSU 0;
BA_ "UsrSigPurpose" SG_ 1325 NMSleepFlag_PFSU 9;
BA_ "UserSigValidity" SG_ 1309 Destination_GW_RRPSU 0;
BA_ "UsrSigPurpose" SG_ 1309 Destination_GW_RRPSU 9;
BA_ "UserSigValidity" SG_ 1309 NMCommandCode_GW_RRPSU 0;
BA_ "UsrSigPurpose" SG_ 1309 NMCommandCode_GW_RRPSU 9;
BA_ "UserSigValidity" SG_ 1309 NMSleepFlag_GW_RRPSU 0;
BA_ "UsrSigPurpose" SG_ 1309 NMSleepFlag_GW_RRPSU 9;
BA_ "UserSigValidity" SG_ 1348 Destination_ALBCU 0;
BA_ "UsrSigPurpose" SG_ 1348 Destination_ALBCU 9;
BA_ "UserSigValidity" SG_ 1348 NMCommandCode_ALBCU 0;
BA_ "UsrSigPurpose" SG_ 1348 NMCommandCode_ALBCU 9;
BA_ "UserSigValidity" SG_ 1348 NMSleepFlag_ALBCU 0;
BA_ "UsrSigPurpose" SG_ 1348 NMSleepFlag_ALBCU 9;
BA_ "UserSigValidity" SG_ 1369 Destination_DSAU 0;
BA_ "UsrSigPurpose" SG_ 1369 Destination_DSAU 9;
BA_ "UserSigValidity" SG_ 1369 NMCommandCode_DSAU 0;
BA_ "UsrSigPurpose" SG_ 1369 NMCommandCode_DSAU 9;
BA_ "UserSigValidity" SG_ 1369 NMSleepFlag_DSAU 0;
BA_ "UsrSigPurpose" SG_ 1369 NMSleepFlag_DSAU 9;
BA_ "UserSigValidity" SG_ 1288 Destination_SWRC 0;
BA_ "UsrSigPurpose" SG_ 1288 Destination_SWRC 9;
BA_ "UserSigValidity" SG_ 1288 NMCommandCode_SWRC 0;
BA_ "UsrSigPurpose" SG_ 1288 NMCommandCode_SWRC 9;
BA_ "UserSigValidity" SG_ 1288 NMSleepFlag_SWRC 0;
BA_ "UsrSigPurpose" SG_ 1288 NMSleepFlag_SWRC 9;
BA_ "UserSigValidity" SG_ 1322 Destination_SHVU_FR 0;
BA_ "UsrSigPurpose" SG_ 1322 Destination_SHVU_FR 9;
BA_ "UserSigValidity" SG_ 1322 NMCommandCode_SHVU_FR 0;
BA_ "UsrSigPurpose" SG_ 1322 NMCommandCode_SHVU_FR 9;
BA_ "UserSigValidity" SG_ 1322 NMSleepFlag_SHVU_FR 0;
BA_ "UsrSigPurpose" SG_ 1322 NMSleepFlag_SHVU_FR 9;
BA_ "UserSigValidity" SG_ 1350 Destination_RCS 0;
BA_ "UsrSigPurpose" SG_ 1350 Destination_RCS 9;
BA_ "UserSigValidity" SG_ 1350 NMCommandCode_RCS 0;
BA_ "UsrSigPurpose" SG_ 1350 NMCommandCode_RCS 9;
BA_ "UserSigValidity" SG_ 1350 NMSleepFlag_RCS 0;
BA_ "UsrSigPurpose" SG_ 1350 NMSleepFlag_RCS 9;
BA_ "UserSigValidity" SG_ 1336 Destination_GW_DPSU 0;
BA_ "UsrSigPurpose" SG_ 1336 Destination_GW_DPSU 9;
BA_ "UserSigValidity" SG_ 1336 NMCommandCode_GW_DPSU 0;
BA_ "UsrSigPurpose" SG_ 1336 NMCommandCode_GW_DPSU 9;
BA_ "UserSigValidity" SG_ 1336 NMSleepFlag_GW_DPSU 0;
BA_ "UsrSigPurpose" SG_ 1336 NMSleepFlag_GW_DPSU 9;
BA_ "UserSigValidity" SG_ 1352 Destination_BLTN_CAM 0;
BA_ "UsrSigPurpose" SG_ 1352 Destination_BLTN_CAM 9;
BA_ "UserSigValidity" SG_ 1352 NMCommandCode_BLTN_CAM 0;
BA_ "UsrSigPurpose" SG_ 1352 NMCommandCode_BLTN_CAM 9;
BA_ "UserSigValidity" SG_ 1352 NMSleepFlag_BLTN_CAM 0;
BA_ "UsrSigPurpose" SG_ 1352 NMSleepFlag_BLTN_CAM 9;
BA_ "UserSigValidity" SG_ 1287 Destination_SCM 0;
BA_ "UsrSigPurpose" SG_ 1287 Destination_SCM 9;
BA_ "UserSigValidity" SG_ 1287 NMCommandCode_SCM 0;
BA_ "UsrSigPurpose" SG_ 1287 NMCommandCode_SCM 9;
BA_ "UserSigValidity" SG_ 1287 NMSleepFlag_SCM 0;
BA_ "UsrSigPurpose" SG_ 1287 NMSleepFlag_SCM 9;
BA_ "UserSigValidity" SG_ 1364 Destination_OHCL 0;
BA_ "UsrSigPurpose" SG_ 1364 Destination_OHCL 9;
BA_ "UserSigValidity" SG_ 1364 NMCommandCode_OHCL 0;
BA_ "UsrSigPurpose" SG_ 1364 NMCommandCode_OHCL 9;
BA_ "UserSigValidity" SG_ 1364 NMSleepFlag_OHCL 0;
BA_ "UsrSigPurpose" SG_ 1364 NMSleepFlag_OHCL 9;
BA_ "UserSigValidity" SG_ 1311 Destination_RWPC 0;
BA_ "UsrSigPurpose" SG_ 1311 Destination_RWPC 9;
BA_ "UserSigValidity" SG_ 1311 NMCommandCode_RWPC 0;
BA_ "UsrSigPurpose" SG_ 1311 NMCommandCode_RWPC 9;
BA_ "UserSigValidity" SG_ 1311 NMSleepFlag_RWPC 0;
BA_ "UsrSigPurpose" SG_ 1311 NMSleepFlag_RWPC 9;
BA_ "UserSigValidity" SG_ 1333 Destination_RRHV 0;
BA_ "UsrSigPurpose" SG_ 1333 Destination_RRHV 9;
BA_ "UserSigValidity" SG_ 1333 NMCommandCode_RRHV 0;
BA_ "UsrSigPurpose" SG_ 1333 NMCommandCode_RRHV 9;
BA_ "UserSigValidity" SG_ 1333 NMSleepFlag_RRHV 0;
BA_ "UsrSigPurpose" SG_ 1333 NMSleepFlag_RRHV 9;
BA_ "UserSigValidity" SG_ 1310 Destination_WPC 0;
BA_ "UsrSigPurpose" SG_ 1310 Destination_WPC 9;
BA_ "UserSigValidity" SG_ 1310 NMCommandCode_WPC 0;
BA_ "UsrSigPurpose" SG_ 1310 NMCommandCode_WPC 9;
BA_ "UserSigValidity" SG_ 1310 NMSleepFlag_WPC 0;
BA_ "UsrSigPurpose" SG_ 1310 NMSleepFlag_WPC 9;
BA_ "UserSigValidity" SG_ 1354 Destination_HOD 0;
BA_ "UsrSigPurpose" SG_ 1354 Destination_HOD 9;
BA_ "UserSigValidity" SG_ 1354 NMCommandCode_HOD 0;
BA_ "UsrSigPurpose" SG_ 1354 NMCommandCode_HOD 9;
BA_ "UserSigValidity" SG_ 1354 NMSleepFlag_HOD 0;
BA_ "UsrSigPurpose" SG_ 1354 NMSleepFlag_HOD 9;
BA_ "UserSigValidity" SG_ 1363 Destination_ASAU 0;
BA_ "UsrSigPurpose" SG_ 1363 Destination_ASAU 9;
BA_ "UserSigValidity" SG_ 1363 NMCommandCode_ASAU 0;
BA_ "UsrSigPurpose" SG_ 1363 NMCommandCode_ASAU 9;
BA_ "UserSigValidity" SG_ 1363 NMSleepFlag_ASAU 0;
BA_ "UsrSigPurpose" SG_ 1363 NMSleepFlag_ASAU 9;
BA_REL_ "GenSigTimeoutTime" BU_SG_REL_ CGW_CCU SG_ 1951 APSU_PSU_AST_GST_Byte0 0;
BA_REL_ "GenSigTimeoutTime" BU_SG_REL_ CGW_CCU SG_ 1951 APSU_PSU_AST_GST_Byte2 0;
BA_REL_ "GenSigTimeoutTime" BU_SG_REL_ CGW_CCU SG_ 1951 APSU_PSU_AST_GST_Byte3 0;
BA_REL_ "GenSigTimeoutTime" BU_SG_REL_ CGW_CCU SG_ 1951 APSU_PSU_AST_GST_Byte4 0;
BA_REL_ "GenSigTimeoutTime" BU_SG_REL_ CGW_CCU SG_ 1951 APSU_PSU_AST_GST_Byte5 0;
BA_REL_ "GenSigTimeoutTime" BU_SG_REL_ CGW_CCU SG_ 1951 APSU_PSU_AST_GST_Byte6 0;
BA_REL_ "GenSigTimeoutTime" BU_SG_REL_ CGW_CCU SG_ 1951 APSU_PSU_AST_GST_Byte7 0;
BA_REL_ "GenSigTimeoutTime" BU_SG_REL_ CGW_CCU SG_ 1951 APSU_PSU_AST_GST_Byte1 0;
BA_REL_ "GenSigTimeoutTime" BU_SG_REL_ BLTN_CAM SG_ 977 SMK_TrmnlCtrlGrpStaBDC 1500;
BA_REL_ "GenSigTimeoutTime" BU_SG_REL_ BLTN_CAM SG_ 977 SMK_TrmnlCtrlGrpStaBDCEV 1500;
BA_REL_ "GenSigTimeoutTime" BU_SG_REL_ BLTN_CAM SG_ 977 SMK_TrmnlCtrlStaBDCEV 1500;
BA_REL_ "GenSigTimeoutTime" BU_SG_REL_ CGW_CCU SG_ 983 BLTN_CAM_SWVerMajor 1500;
BA_REL_ "GenSigTimeoutTime" BU_SG_REL_ CGW_CCU SG_ 983 BLTN_CAM_SWVerMinor2 1500;
BA_REL_ "GenSigTimeoutTime" BU_SG_REL_ CGW_CCU SG_ 983 BLTN_CAM_SWVerMinor3 1500;
BA_REL_ "GenSigTimeoutTime" BU_SG_REL_ CGW_CCU SG_ 983 BLTN_CAM_SD_Card_Manufacturer 1500;
BA_REL_ "GenSigTimeoutTime" BU_SG_REL_ CGW_CCU SG_ 983 BLTN_CAM_SD_Card_Cap_Class 1500;
BA_REL_ "GenSigTimeoutTime" BU_SG_REL_ CGW_CCU SG_ 983 BLTN_CAM_SWVerMinor1 1500;
BA_REL_ "GenSigTimeoutTime" BU_SG_REL_ CGW_CCU SG_ 981 APSS_StSldFwdMvBtn 1500;
BA_REL_ "GenSigTimeoutTime" BU_SG_REL_ CGW_CCU SG_ 981 APSS_StSldBwdMvBtn 1500;
BA_REL_ "GenSigTimeoutTime" BU_SG_REL_ CGW_CCU SG_ 981 APSS_StRclFwdMvBtn 1500;
BA_REL_ "GenSigTimeoutTime" BU_SG_REL_ CGW_CCU SG_ 981 APSS_StRclBwdMvBtn 1500;
BA_REL_ "GenSigTimeoutTime" BU_SG_REL_ CGW_CCU SG_ 981 APSS_StHgtUpMvBtn 1500;
BA_REL_ "GenSigTimeoutTime" BU_SG_REL_ CGW_CCU SG_ 981 APSS_StHgtDnMvBtn 1500;
BA_REL_ "GenSigTimeoutTime" BU_SG_REL_ CGW_CCU SG_ 981 APSS_StTltUpMvBtn 1500;
BA_REL_ "GenSigTimeoutTime" BU_SG_REL_ CGW_CCU SG_ 981 APSS_StTltDnMvBtn 1500;
BA_REL_ "GenSigTimeoutTime" BU_SG_REL_ CGW_CCU SG_ 981 APSS_StHRestUpMvBtn 1500;
BA_REL_ "GenSigTimeoutTime" BU_SG_REL_ CGW_CCU SG_ 981 APSS_StHRestDnMvBtn 1500;
BA_REL_ "GenSigTimeoutTime" BU_SG_REL_ CGW_CCU SG_ 981 APSS_StHRestFwdMvBtn 1500;
BA_REL_ "GenSigTimeoutTime" BU_SG_REL_ CGW_CCU SG_ 981 APSS_StHRestBwdMvBtn 1500;
BA_REL_ "GenSigTimeoutTime" BU_SG_REL_ CGW_CCU SG_ 968 RCM_BldPosSta 1500;
BA_REL_ "GenSigTimeoutTime" BU_SG_REL_ SGU SG_ 968 RCM_BldPosSta 1500;
BA_REL_ "GenSigTimeoutTime" BU_SG_REL_ CGW_CCU SG_ 968 RCM_BldFltSta 1500;
BA_REL_ "GenSigTimeoutTime" BU_SG_REL_ ATS SG_ 963 SunRoof_RearBlindOprSta 1500;
BA_REL_ "GenSigTimeoutTime" BU_SG_REL_ CGW_CCU SG_ 967 RCM_SunroofOpnSta 1500;
BA_REL_ "GenSigTimeoutTime" BU_SG_REL_ CGW_CCU SG_ 967 RCM_GlsOpSta 1500;
BA_REL_ "GenSigTimeoutTime" BU_SG_REL_ CGW_CCU SG_ 967 RCM_GlsPosSta 1500;
BA_REL_ "GenSigTimeoutTime" BU_SG_REL_ CGW_CCU SG_ 967 RCM_GlsFltSta 1500;
BA_REL_ "GenSigTimeoutTime" BU_SG_REL_ CGW_CCU SG_ 966 RCM_OptTyp 1500;
BA_REL_ "GenSigTimeoutTime" BU_SG_REL_ CGW_CCU SG_ 966 RCM_TunnelOptType 1500;
VAL_ 977 SMK_Crc13Val 0 "0x0x0~0xFF:CRCValue" 255 "0x0x0~0xFF:CRCValue" ;
VAL_ 977 SMK_TlPwrOnSta 0 "Default" 1 "Power On" 2 "Not Used" 3 "Error Indicator" ;
VAL_ 977 SMK_AlvCnt13Val 0 "AlvCntValue" 1 "AlvCntValue" 2 "AlvCntValue" 3 "AlvCntValue" 4 "AlvCntValue" 5 "AlvCntValue" 6 "AlvCntValue" 7 "AlvCntValue" 8 "AlvCntValue" 9 "AlvCntValue" 10 "AlvCntValue" 11 "AlvCntValue" 12 "AlvCntValue" 13 "AlvCntValue" 14 "AlvCntValue" 15 "AlvCntValue" ;
VAL_ 977 SMK_TrmnlCtrlGrpStaBDC 0 "Off" 1 "Acc" 2 "Ign" 3 "Cranking" 4 "Engine Running" 5 "RESERVED" 6 "RESERVED" 7 "Error Indicator" ;
VAL_ 977 SMK_TrmnlCtrlStaBDC 0 "OFF" 1 "OFF_AUTHWAITING" 2 "OFF_CRANKINGAUTHWAITING" 3 "OFF_ESCLUNLOCKWAITING" 4 "ACC" 5 "ACC_AUTHWAITING" 6 "ACC_ESCLUNLOCKWAITING" 7 "IGN" 8 "IGN_AUTHWAITING" 9 "IGN_CRANKINGWAIT" 10 "CRANKING" 11 "ENGINERUNNING" 12 "RESERVED" 13 "RESERVED" 14 "RESERVED" 15 "RESERVED" 16 "RESERVED" 17 "RESERVED" 18 "RESERVED" 19 "RESERVED" 20 "RESERVED" 21 "RESERVED" 22 "RESERVED" 23 "RESERVED" 24 "RESERVED" 25 "RESERVED" 26 "RESERVED" 27 "RESERVED" 28 "RESERVED" 29 "RESERVED" 30 "RESERVED" 31 "Error Indicator" ;
VAL_ 977 SMK_TrmnlCtrlGrpStaBDCEV 0 "Off" 1 "PowerOn" 2 "Cranking" 3 "Ready" 4 "RESERVED" 5 "RESERVED" 6 "RESERVED" 7 "Error Indicator" ;
VAL_ 977 SMK_TrmnlCtrlStaBDCEV 0 "Off" 1 "Off_AuthWaiting" 2 "Off_CrankingAuthWaiting" 3 "Off_ESCLUnlockWaiting" 4 "PowerOn" 5 "PowerOn_ESCLUnlockWaiting" 6 "PowerOn_AuthWaiting" 7 "PowerOn_CrankingWait" 8 "Cranking" 9 "Ready" 10 "RESERVED" 11 "RESERVED" 12 "RESERVED" 13 "RESERVED" 14 "RESERVED" 15 "RESERVED" 16 "RESERVED" 17 "RESERVED" 18 "RESERVED" 19 "RESERVED" 20 "RESERVED" 21 "RESERVED" 22 "RESERVED" 23 "RESERVED" 24 "RESERVED" 25 "RESERVED" 26 "RESERVED" 27 "RESERVED" 28 "RESERVED" 29 "RESERVED" 30 "RESERVED" 31 "Error Indicator" ;
VAL_ 977 SMK_PwrOnModeSta 0 "Off Mode" 1 "Power On Normal Mode" 2 "Utility Mode" 3 "Maintenance Service Mode" ;
VAL_ 977 SMK_StndbyMdTmrMin 0 "Default (Timer Stop)" 1 "0min ~ 60min" 2 "0min ~ 60min" 3 "0min ~ 60min" 4 "0min ~ 60min" 5 "0min ~ 60min" 6 "0min ~ 60min" 7 "0min ~ 60min" 8 "0min ~ 60min" 9 "0min ~ 60min" 10 "0min ~ 60min" 11 "0min ~ 60min" 12 "0min ~ 60min" 13 "0min ~ 60min" 14 "0min ~ 60min" 15 "0min ~ 60min" 16 "0min ~ 60min" 17 "0min ~ 60min" 18 "0min ~ 60min" 19 "0min ~ 60min" 20 "0min ~ 60min" 21 "0min ~ 60min" 22 "0min ~ 60min" 23 "0min ~ 60min" 24 "0min ~ 60min" 25 "0min ~ 60min" 26 "0min ~ 60min" 27 "0min ~ 60min" 28 "0min ~ 60min" 29 "0min ~ 60min" 30 "0min ~ 60min" 31 "0min ~ 60min" 32 "0min ~ 60min" 33 "0min ~ 60min" 34 "0min ~ 60min" 35 "0min ~ 60min" 36 "0min ~ 60min" 37 "0min ~ 60min" 38 "0min ~ 60min" 39 "0min ~ 60min" 40 "0min ~ 60min" 41 "0min ~ 60min" 42 "0min ~ 60min" 43 "0min ~ 60min" 44 "0min ~ 60min" 45 "0min ~ 60min" 46 "0min ~ 60min" 47 "0min ~ 60min" 48 "0min ~ 60min" 49 "0min ~ 60min" 50 "0min ~ 60min" 51 "0min ~ 60min" 52 "0min ~ 60min" 53 "0min ~ 60min" 54 "0min ~ 60min" 55 "0min ~ 60min" 56 "0min ~ 60min" 57 "0min ~ 60min" 58 "0min ~ 60min" 59 "0min ~ 60min" 60 "0min ~ 60min" 61 "0min ~ 60min" 62 "RESERVED" 63 "Error Indicator" ;
VAL_ 977 SMK_StndbyMdTmrSec 0 "Default (Timer Stop)" 1 "0sec ~ 59sec" 2 "0sec ~ 59sec" 3 "0sec ~ 59sec" 4 "0sec ~ 59sec" 5 "0sec ~ 59sec" 6 "0sec ~ 59sec" 7 "0sec ~ 59sec" 8 "0sec ~ 59sec" 9 "0sec ~ 59sec" 10 "0sec ~ 59sec" 11 "0sec ~ 59sec" 12 "0sec ~ 59sec" 13 "0sec ~ 59sec" 14 "0sec ~ 59sec" 15 "0sec ~ 59sec" 16 "0sec ~ 59sec" 17 "0sec ~ 59sec" 18 "0sec ~ 59sec" 19 "0sec ~ 59sec" 20 "0sec ~ 59sec" 21 "0sec ~ 59sec" 22 "0sec ~ 59sec" 23 "0sec ~ 59sec" 24 "0sec ~ 59sec" 25 "0sec ~ 59sec" 26 "0sec ~ 59sec" 27 "0sec ~ 59sec" 28 "0sec ~ 59sec" 29 "0sec ~ 59sec" 30 "0sec ~ 59sec" 31 "0sec ~ 59sec" 32 "0sec ~ 59sec" 33 "0sec ~ 59sec" 34 "0sec ~ 59sec" 35 "0sec ~ 59sec" 36 "0sec ~ 59sec" 37 "0sec ~ 59sec" 38 "0sec ~ 59sec" 39 "0sec ~ 59sec" 40 "0sec ~ 59sec" 41 "0sec ~ 59sec" 42 "0sec ~ 59sec" 43 "0sec ~ 59sec" 44 "0sec ~ 59sec" 45 "0sec ~ 59sec" 46 "0sec ~ 59sec" 47 "0sec ~ 59sec" 48 "0sec ~ 59sec" 49 "0sec ~ 59sec" 50 "0sec ~ 59sec" 51 "0sec ~ 59sec" 52 "0sec ~ 59sec" 53 "0sec ~ 59sec" 54 "0sec ~ 59sec" 55 "0sec ~ 59sec" 56 "0sec ~ 59sec" 57 "0sec ~ 59sec" 58 "0sec ~ 59sec" 59 "0sec ~ 59sec" 60 "0sec ~ 59sec" 61 "RESERVED" 62 "RESERVED" 63 "Error Indicator" ;
VAL_ 977 SMK_EVPwrOffReq 0 "Off" 1 "On" 2 "RESERVED" 3 "Error Indicator" ;
VAL_ 977 SMK_RLHndLkSnsrSta 0 "Off" 1 "On" 2 "Not Used" 3 "Error Indicator" ;
VAL_ 977 SMK_RLDrHndUnLkSnsrSta 0 "Off" 1 "On" 2 "Not Used" 3 "Error Indicator" ;
VAL_ 977 SMK_RRDrHndLkSnsrSta 0 "Off" 1 "On" 2 "Not Used" 3 "Error Indicator" ;
VAL_ 977 SMK_RRDrHndUnLkSnsrSta 0 "Off" 1 "On" 2 "Not Used" 3 "Error Indicator" ;
VAL_ 977 SMK_MaintenanceSrvMdReq 0 "Request off" 1 "Request on" 2 "RESERVED" 3 "Error Indicator" ;
VAL_ 977 Auth_ISKLearnSta2 0 "Default(Normal)" 1 "Virgin" 2 "Learning" 3 "Learnt" 4 "Neutralizing" 5 "Neutralized" 6 "RESERVED" 7 "Invalid" ;
VAL_ 977 Fob_FoundForChargingDoor 0 "Default" 1 "Fob Found" 2 "No Fob Found" 3 "Error Indicator" ;
VAL_ 977 Fob_FoundCabinArea 0 "Default" 1 "Fob Found" 2 "No Fob Found" 3 "Error Indicator" ;
VAL_ 983 BLTN_CAM_SWVerMajor 0 "ASCII Code Value (HEX)" 1 "ASCII Code Value (HEX)" 2 "ASCII Code Value (HEX)" 3 "ASCII Code Value (HEX)" 4 "ASCII Code Value (HEX)" 5 "ASCII Code Value (HEX)" 6 "ASCII Code Value (HEX)" 7 "ASCII Code Value (HEX)" 8 "ASCII Code Value (HEX)" 9 "ASCII Code Value (HEX)" 10 "ASCII Code Value (HEX)" 11 "ASCII Code Value (HEX)" 12 "ASCII Code Value (HEX)" 13 "ASCII Code Value (HEX)" 14 "ASCII Code Value (HEX)" 15 "ASCII Code Value (HEX)" ;
VAL_ 983 BLTN_CAM_SWVerMinor2 0 "Minor2 verion, 0~99 dec" 1 "Minor2 verion, 0~99 dec" 2 "Minor2 verion, 0~99 dec" 3 "Minor2 verion, 0~99 dec" 4 "Minor2 verion, 0~99 dec" 5 "Minor2 verion, 0~99 dec" 6 "Minor2 verion, 0~99 dec" 7 "Minor2 verion, 0~99 dec" 8 "Minor2 verion, 0~99 dec" 9 "Minor2 verion, 0~99 dec" 10 "Minor2 verion, 0~99 dec" 11 "Minor2 verion, 0~99 dec" 12 "Minor2 verion, 0~99 dec" 13 "Minor2 verion, 0~99 dec" 14 "Minor2 verion, 0~99 dec" 15 "Minor2 verion, 0~99 dec" 16 "Minor2 verion, 0~99 dec" 17 "Minor2 verion, 0~99 dec" 18 "Minor2 verion, 0~99 dec" 19 "Minor2 verion, 0~99 dec" 20 "Minor2 verion, 0~99 dec" 21 "Minor2 verion, 0~99 dec" 22 "Minor2 verion, 0~99 dec" 23 "Minor2 verion, 0~99 dec" 24 "Minor2 verion, 0~99 dec" 25 "Minor2 verion, 0~99 dec" 26 "Minor2 verion, 0~99 dec" 27 "Minor2 verion, 0~99 dec" 28 "Minor2 verion, 0~99 dec" 29 "Minor2 verion, 0~99 dec" 30 "Minor2 verion, 0~99 dec" 31 "Minor2 verion, 0~99 dec" 32 "Minor2 verion, 0~99 dec" 33 "Minor2 verion, 0~99 dec" 34 "Minor2 verion, 0~99 dec" 35 "Minor2 verion, 0~99 dec" 36 "Minor2 verion, 0~99 dec" 37 "Minor2 verion, 0~99 dec" 38 "Minor2 verion, 0~99 dec" 39 "Minor2 verion, 0~99 dec" 40 "Minor2 verion, 0~99 dec" 41 "Minor2 verion, 0~99 dec" 42 "Minor2 verion, 0~99 dec" 43 "Minor2 verion, 0~99 dec" 44 "Minor2 verion, 0~99 dec" 45 "Minor2 verion, 0~99 dec" 46 "Minor2 verion, 0~99 dec" 47 "Minor2 verion, 0~99 dec" 48 "Minor2 verion, 0~99 dec" 49 "Minor2 verion, 0~99 dec" 50 "Minor2 verion, 0~99 dec" 51 "Minor2 verion, 0~99 dec" 52 "Minor2 verion, 0~99 dec" 53 "Minor2 verion, 0~99 dec" 54 "Minor2 verion, 0~99 dec" 55 "Minor2 verion, 0~99 dec" 56 "Minor2 verion, 0~99 dec" 57 "Minor2 verion, 0~99 dec" 58 "Minor2 verion, 0~99 dec" 59 "Minor2 verion, 0~99 dec" 60 "Minor2 verion, 0~99 dec" 61 "Minor2 verion, 0~99 dec" 62 "Minor2 verion, 0~99 dec" 63 "Minor2 verion, 0~99 dec" 64 "Minor2 verion, 0~99 dec" 65 "Minor2 verion, 0~99 dec" 66 "Minor2 verion, 0~99 dec" 67 "Minor2 verion, 0~99 dec" 68 "Minor2 verion, 0~99 dec" 69 "Minor2 verion, 0~99 dec" 70 "Minor2 verion, 0~99 dec" 71 "Minor2 verion, 0~99 dec" 72 "Minor2 verion, 0~99 dec" 73 "Minor2 verion, 0~99 dec" 74 "Minor2 verion, 0~99 dec" 75 "Minor2 verion, 0~99 dec" 76 "Minor2 verion, 0~99 dec" 77 "Minor2 verion, 0~99 dec" 78 "Minor2 verion, 0~99 dec" 79 "Minor2 verion, 0~99 dec" 80 "Minor2 verion, 0~99 dec" 81 "Minor2 verion, 0~99 dec" 82 "Minor2 verion, 0~99 dec" 83 "Minor2 verion, 0~99 dec" 84 "Minor2 verion, 0~99 dec" 85 "Minor2 verion, 0~99 dec" 86 "Minor2 verion, 0~99 dec" 87 "Minor2 verion, 0~99 dec" 88 "Minor2 verion, 0~99 dec" 89 "Minor2 verion, 0~99 dec" 90 "Minor2 verion, 0~99 dec" 91 "Minor2 verion, 0~99 dec" 92 "Minor2 verion, 0~99 dec" 93 "Minor2 verion, 0~99 dec" 94 "Minor2 verion, 0~99 dec" 95 "Minor2 verion, 0~99 dec" 96 "Minor2 verion, 0~99 dec" 97 "Minor2 verion, 0~99 dec" 98 "Minor2 verion, 0~99 dec" 99 "Minor2 verion, 0~99 dec" 100 "Reserved" 101 "Reserved" 102 "Reserved" 103 "Reserved" 104 "Reserved" 105 "Reserved" 106 "Reserved" 107 "Reserved" 108 "Reserved" 109 "Reserved" 110 "Reserved" 111 "Reserved" 112 "Reserved" 113 "Reserved" 114 "Reserved" 115 "Reserved" 116 "Reserved" 117 "Reserved" 118 "Reserved" 119 "Reserved" 120 "Reserved" 121 "Reserved" 122 "Reserved" 123 "Reserved" 124 "Reserved" 125 "Reserved" 126 "Reserved" 127 "Invalid" ;
VAL_ 983 BLTN_CAM_SWVerMinor3 0 "Minor3 version, 0~99 dec" 1 "Minor3 version, 0~99 dec" 2 "Minor3 version, 0~99 dec" 3 "Minor3 version, 0~99 dec" 4 "Minor3 version, 0~99 dec" 5 "Minor3 version, 0~99 dec" 6 "Minor3 version, 0~99 dec" 7 "Minor3 version, 0~99 dec" 8 "Minor3 version, 0~99 dec" 9 "Minor3 version, 0~99 dec" 10 "Minor3 version, 0~99 dec" 11 "Minor3 version, 0~99 dec" 12 "Minor3 version, 0~99 dec" 13 "Minor3 version, 0~99 dec" 14 "Minor3 version, 0~99 dec" 15 "Minor3 version, 0~99 dec" 16 "Minor3 version, 0~99 dec" 17 "Minor3 version, 0~99 dec" 18 "Minor3 version, 0~99 dec" 19 "Minor3 version, 0~99 dec" 20 "Minor3 version, 0~99 dec" 21 "Minor3 version, 0~99 dec" 22 "Minor3 version, 0~99 dec" 23 "Minor3 version, 0~99 dec" 24 "Minor3 version, 0~99 dec" 25 "Minor3 version, 0~99 dec" 26 "Minor3 version, 0~99 dec" 27 "Minor3 version, 0~99 dec" 28 "Minor3 version, 0~99 dec" 29 "Minor3 version, 0~99 dec" 30 "Minor3 version, 0~99 dec" 31 "Minor3 version, 0~99 dec" 32 "Minor3 version, 0~99 dec" 33 "Minor3 version, 0~99 dec" 34 "Minor3 version, 0~99 dec" 35 "Minor3 version, 0~99 dec" 36 "Minor3 version, 0~99 dec" 37 "Minor3 version, 0~99 dec" 38 "Minor3 version, 0~99 dec" 39 "Minor3 version, 0~99 dec" 40 "Minor3 version, 0~99 dec" 41 "Minor3 version, 0~99 dec" 42 "Minor3 version, 0~99 dec" 43 "Minor3 version, 0~99 dec" 44 "Minor3 version, 0~99 dec" 45 "Minor3 version, 0~99 dec" 46 "Minor3 version, 0~99 dec" 47 "Minor3 version, 0~99 dec" 48 "Minor3 version, 0~99 dec" 49 "Minor3 version, 0~99 dec" 50 "Minor3 version, 0~99 dec" 51 "Minor3 version, 0~99 dec" 52 "Minor3 version, 0~99 dec" 53 "Minor3 version, 0~99 dec" 54 "Minor3 version, 0~99 dec" 55 "Minor3 version, 0~99 dec" 56 "Minor3 version, 0~99 dec" 57 "Minor3 version, 0~99 dec" 58 "Minor3 version, 0~99 dec" 59 "Minor3 version, 0~99 dec" 60 "Minor3 version, 0~99 dec" 61 "Minor3 version, 0~99 dec" 62 "Minor3 version, 0~99 dec" 63 "Minor3 version, 0~99 dec" 64 "Minor3 version, 0~99 dec" 65 "Minor3 version, 0~99 dec" 66 "Minor3 version, 0~99 dec" 67 "Minor3 version, 0~99 dec" 68 "Minor3 version, 0~99 dec" 69 "Minor3 version, 0~99 dec" 70 "Minor3 version, 0~99 dec" 71 "Minor3 version, 0~99 dec" 72 "Minor3 version, 0~99 dec" 73 "Minor3 version, 0~99 dec" 74 "Minor3 version, 0~99 dec" 75 "Minor3 version, 0~99 dec" 76 "Minor3 version, 0~99 dec" 77 "Minor3 version, 0~99 dec" 78 "Minor3 version, 0~99 dec" 79 "Minor3 version, 0~99 dec" 80 "Minor3 version, 0~99 dec" 81 "Minor3 version, 0~99 dec" 82 "Minor3 version, 0~99 dec" 83 "Minor3 version, 0~99 dec" 84 "Minor3 version, 0~99 dec" 85 "Minor3 version, 0~99 dec" 86 "Minor3 version, 0~99 dec" 87 "Minor3 version, 0~99 dec" 88 "Minor3 version, 0~99 dec" 89 "Minor3 version, 0~99 dec" 90 "Minor3 version, 0~99 dec" 91 "Minor3 version, 0~99 dec" 92 "Minor3 version, 0~99 dec" 93 "Minor3 version, 0~99 dec" 94 "Minor3 version, 0~99 dec" 95 "Minor3 version, 0~99 dec" 96 "Minor3 version, 0~99 dec" 97 "Minor3 version, 0~99 dec" 98 "Minor3 version, 0~99 dec" 99 "Minor3 version, 0~99 dec" 100 "Reserved" 101 "Reserved" 102 "Reserved" 103 "Reserved" 104 "Reserved" 105 "Reserved" 106 "Reserved" 107 "Reserved" 108 "Reserved" 109 "Reserved" 110 "Reserved" 111 "Reserved" 112 "Reserved" 113 "Reserved" 114 "Reserved" 115 "Reserved" 116 "Reserved" 117 "Reserved" 118 "Reserved" 119 "Reserved" 120 "Reserved" 121 "Reserved" 122 "Reserved" 123 "Reserved" 124 "Reserved" 125 "Reserved" 126 "Reserved" 127 "Invalid" ;
VAL_ 983 BLTN_CAM_SD_Card_Manufacturer 0 "SD Card not found" 1 "Micron-Genuine part" 2 "RESERVED" 3 "RESERVED" 4 "RESERVED" 5 "RESERVED" 6 "Unknown" 7 "Invalid" ;
VAL_ 983 BLTN_CAM_SD_Card_Cap_Class 0 "SD Card not found" 1 "64Gbyte Class" 2 "128Gbyte Class" 3 "256Gbyte Class" 4 "512Gbyte Class" 5 "1Tbyte Class" 6 "2Tbyte Class" 7 "Invalid" ;
VAL_ 983 BLTN_CAM_SWVerMinor1 0 "Minor1 version, 0~99 dec" 1 "Minor1 version, 0~99 dec" 2 "Minor1 version, 0~99 dec" 3 "Minor1 version, 0~99 dec" 4 "Minor1 version, 0~99 dec" 5 "Minor1 version, 0~99 dec" 6 "Minor1 version, 0~99 dec" 7 "Minor1 version, 0~99 dec" 8 "Minor1 version, 0~99 dec" 9 "Minor1 version, 0~99 dec" 10 "Minor1 version, 0~99 dec" 11 "Minor1 version, 0~99 dec" 12 "Minor1 version, 0~99 dec" 13 "Minor1 version, 0~99 dec" 14 "Minor1 version, 0~99 dec" 15 "Minor1 version, 0~99 dec" 16 "Minor1 version, 0~99 dec" 17 "Minor1 version, 0~99 dec" 18 "Minor1 version, 0~99 dec" 19 "Minor1 version, 0~99 dec" 20 "Minor1 version, 0~99 dec" 21 "Minor1 version, 0~99 dec" 22 "Minor1 version, 0~99 dec" 23 "Minor1 version, 0~99 dec" 24 "Minor1 version, 0~99 dec" 25 "Minor1 version, 0~99 dec" 26 "Minor1 version, 0~99 dec" 27 "Minor1 version, 0~99 dec" 28 "Minor1 version, 0~99 dec" 29 "Minor1 version, 0~99 dec" 30 "Minor1 version, 0~99 dec" 31 "Minor1 version, 0~99 dec" 32 "Minor1 version, 0~99 dec" 33 "Minor1 version, 0~99 dec" 34 "Minor1 version, 0~99 dec" 35 "Minor1 version, 0~99 dec" 36 "Minor1 version, 0~99 dec" 37 "Minor1 version, 0~99 dec" 38 "Minor1 version, 0~99 dec" 39 "Minor1 version, 0~99 dec" 40 "Minor1 version, 0~99 dec" 41 "Minor1 version, 0~99 dec" 42 "Minor1 version, 0~99 dec" 43 "Minor1 version, 0~99 dec" 44 "Minor1 version, 0~99 dec" 45 "Minor1 version, 0~99 dec" 46 "Minor1 version, 0~99 dec" 47 "Minor1 version, 0~99 dec" 48 "Minor1 version, 0~99 dec" 49 "Minor1 version, 0~99 dec" 50 "Minor1 version, 0~99 dec" 51 "Minor1 version, 0~99 dec" 52 "Minor1 version, 0~99 dec" 53 "Minor1 version, 0~99 dec" 54 "Minor1 version, 0~99 dec" 55 "Minor1 version, 0~99 dec" 56 "Minor1 version, 0~99 dec" 57 "Minor1 version, 0~99 dec" 58 "Minor1 version, 0~99 dec" 59 "Minor1 version, 0~99 dec" 60 "Minor1 version, 0~99 dec" 61 "Minor1 version, 0~99 dec" 62 "Minor1 version, 0~99 dec" 63 "Minor1 version, 0~99 dec" 64 "Minor1 version, 0~99 dec" 65 "Minor1 version, 0~99 dec" 66 "Minor1 version, 0~99 dec" 67 "Minor1 version, 0~99 dec" 68 "Minor1 version, 0~99 dec" 69 "Minor1 version, 0~99 dec" 70 "Minor1 version, 0~99 dec" 71 "Minor1 version, 0~99 dec" 72 "Minor1 version, 0~99 dec" 73 "Minor1 version, 0~99 dec" 74 "Minor1 version, 0~99 dec" 75 "Minor1 version, 0~99 dec" 76 "Minor1 version, 0~99 dec" 77 "Minor1 version, 0~99 dec" 78 "Minor1 version, 0~99 dec" 79 "Minor1 version, 0~99 dec" 80 "Minor1 version, 0~99 dec" 81 "Minor1 version, 0~99 dec" 82 "Minor1 version, 0~99 dec" 83 "Minor1 version, 0~99 dec" 84 "Minor1 version, 0~99 dec" 85 "Minor1 version, 0~99 dec" 86 "Minor1 version, 0~99 dec" 87 "Minor1 version, 0~99 dec" 88 "Minor1 version, 0~99 dec" 89 "Minor1 version, 0~99 dec" 90 "Minor1 version, 0~99 dec" 91 "Minor1 version, 0~99 dec" 92 "Minor1 version, 0~99 dec" 93 "Minor1 version, 0~99 dec" 94 "Minor1 version, 0~99 dec" 95 "Minor1 version, 0~99 dec" 96 "Minor1 version, 0~99 dec" 97 "Minor1 version, 0~99 dec" 98 "Minor1 version, 0~99 dec" 99 "Minor1 version, 0~99 dec" 100 "Reserved" 101 "Reserved" 102 "Reserved" 103 "Reserved" 104 "Reserved" 105 "Reserved" 106 "Reserved" 107 "Reserved" 108 "Reserved" 109 "Reserved" 110 "Reserved" 111 "Reserved" 112 "Reserved" 113 "Reserved" 114 "Reserved" 115 "Reserved" 116 "Reserved" 117 "Reserved" 118 "Reserved" 119 "Reserved" 120 "Reserved" 121 "Reserved" 122 "Reserved" 123 "Reserved" 124 "Reserved" 125 "Reserved" 126 "Reserved" 127 "Invalid" ;
VAL_ 981 APSS_StExtFwdMvBtn 0 "Default" 1 "Off" 2 "On" 3 "Invalid" ;
VAL_ 981 APSS_StSldFwdMvBtn 0 "Default" 1 "Off" 2 "On" 3 "Invalid" ;
VAL_ 981 APSS_StSldBwdMvBtn 0 "Default" 1 "Off" 2 "On" 3 "Invalid" ;
VAL_ 981 APSS_StExtBwdMvBtn 0 "Default" 1 "Off" 2 "On" 3 "Invaild" ;
VAL_ 981 APSS_StRclFwdMvBtn 0 "Default" 1 "Off" 2 "On" 3 "Invalid" ;
VAL_ 981 APSS_StRclBwdMvBtn 0 "Default" 1 "Off" 2 "On" 3 "Invalid" ;
VAL_ 981 APSS_StHgtUpMvBtn 0 "Default" 1 "Off" 2 "On" 3 "Invalid" ;
VAL_ 981 APSS_StHgtDnMvBtn 0 "Default" 1 "Off" 2 "On" 3 "Invalid" ;
VAL_ 981 APSS_StTltUpMvBtn 0 "Default" 1 "Off" 2 "On" 3 "Invalid" ;
VAL_ 981 APSS_StTltDnMvBtn 0 "Default" 1 "Off" 2 "On" 3 "Invalid" ;
VAL_ 981 APSS_StHRestUpMvBtn 0 "Default" 1 "Off" 2 "On" 3 "Invalid" ;
VAL_ 981 APSS_StHRestDnMvBtn 0 "Default" 1 "Off" 2 "On" 3 "Invalid" ;
VAL_ 981 APSS_StHRestFwdMvBtn 0 "Default" 1 "Off" 2 "On" 3 "Invalid" ;
VAL_ 981 APSS_StHRestBwdMvBtn 0 "Default" 1 "Off" 2 "On" 3 "Invalid" ;
VAL_ 981 APSS_StLegUpMvBtn 0 "Default" 1 "Off" 2 "On" 3 "Invalid" ;
VAL_ 981 APSS_StLegDnMvBtn 0 "Default" 1 "Off" 2 "On" 3 "Invalid" ;
VAL_ 981 APSS_StRlxModeBtn 0 "Default" 1 "Off" 2 "On" 3 "Invalid" ;
VAL_ 981 APSS_StRlxReturnBtn 0 "Default" 1 "Off" 2 "On" 3 "Invalid" ;
VAL_ 981 APSS_StRlxTltUpMvBtn 0 "Default" 1 "Off" 2 "On" 3 "Invalid" ;
VAL_ 981 APSS_StRlxTltDnMvBtn 0 "Default" 1 "Off" 2 "On" 3 "Invalid" ;
VAL_ 981 APSS_StAutoModeEnable 0 "Default" 1 "AutoMoveEnable" 2 "AutoMoveDisable" 3 "Invalid" ;
VAL_ 968 RCM_Crc3Val 0 "0x0x0~0xFF:CRCValue" 255 "0x0x0~0xFF:CRCValue" ;
VAL_ 968 RCM_AlvCnt3Val 0 "AlvCntValue" 1 "AlvCntValue" 2 "AlvCntValue" 3 "AlvCntValue" 4 "AlvCntValue" 5 "AlvCntValue" 6 "AlvCntValue" 7 "AlvCntValue" 8 "AlvCntValue" 9 "AlvCntValue" 10 "AlvCntValue" 11 "AlvCntValue" 12 "AlvCntValue" 13 "AlvCntValue" 14 "AlvCntValue" 15 "AlvCntValue" ;
VAL_ 968 RCM_BldOpSta 0 "No Action" 1 "Opening" 2 "Closing" 3 "Reversing" ;
VAL_ 968 RCM_BldPosSta 0 "Full Close" 1 "BCH" 2 "Half Open" 3 "BHO" 4 "Full Open" 5 "Undefined" 6 "Reserved" 7 "Invalid" ;
VAL_ 968 RCM_BldFltSta 0 "Normal (Initialized)" 1 "Fault" 2 "Not Initialized" 3 "Error Indicator" ;
VAL_ 963 BCM_Crc16Val 0 "0x0x0~0xFF:CRCValue" 255 "0x0x0~0xFF:CRCValue" ;
VAL_ 963 BCM_AlvCnt16Val 0 "AlvCntValue" 1 "AlvCntValue" 2 "AlvCntValue" 3 "AlvCntValue" 4 "AlvCntValue" 5 "AlvCntValue" 6 "AlvCntValue" 7 "AlvCntValue" 8 "AlvCntValue" 9 "AlvCntValue" 10 "AlvCntValue" 11 "AlvCntValue" 12 "AlvCntValue" 13 "AlvCntValue" 14 "AlvCntValue" 15 "AlvCntValue" ;
VAL_ 963 IBU_SWVerMajor1 0 "0x0x0~0x7F:ASCII Code Value (HEX)" 127 "0x0x0~0x7F:ASCII Code Value (HEX)" ;
VAL_ 963 IBU_SWVerMinor1 0 "0x0x0~0x7F:ASCII Code Value (HEX)" 127 "0x0x0~0x7F:ASCII Code Value (HEX)" ;
VAL_ 963 IBU_SWVerMinor2 0 "0x0x0~0x7F:ASCII Code Value (HEX)" 127 "0x0x0~0x7F:ASCII Code Value (HEX)" ;
VAL_ 963 ECW_Fault 0 "Else" 1 "Detected" 2 "Not used" 3 "Error Indicator" ;
VAL_ 963 ECW_FaultActv 0 "Else" 1 "Valid" 2 "Not used" 3 "Error Indicator" ;
VAL_ 963 ECW_HiVolt 0 "Else" 1 "Detected" 2 "Not used" 3 "Error Indicator" ;
VAL_ 963 ECW_HiVoltActv 0 "Else" 1 "Valid" 2 "Not used" 3 "Error Indicator" ;
VAL_ 963 ECW_LoVolt 0 "Else" 1 "Detected" 2 "Not used" 3 "Error Indicator" ;
VAL_ 963 ECW_LoVoltActv 0 "Else" 1 "Valid" 2 "Not used" 3 "Error Indicator" ;
VAL_ 963 ECW_Overload 0 "Else" 1 "Detected" 2 "Not used" 3 "Error Indicator" ;
VAL_ 963 ECW_OverloadActv 0 "Else" 1 "Valid" 2 "Not used" 3 "Error Indicator" ;
VAL_ 963 ECW_CommErr 0 "No error" 1 "Error" 2 "Not used" 3 "Error Indicator" ;
VAL_ 963 SunRoof_RearBlindOprSta 0 "No Action" 1 "FullOpen" 2 "FullClose" 3 "PartiallyOpen" 4 "Opening" 5 "Closing" 6 "Reserved" 7 "Reserved" 8 "Reserved" 9 "Reserved" 10 "Reserved" 11 "Reserved" 12 "Reserved" 13 "Reserved" 14 "Reserved" 15 "Invalid" ;
VAL_ 963 ECW_Overload2 0 "Else" 1 "Detected Overload" 2 "Detected Block" 3 "Detected Overheat" 4 "RESERVED" 5 "RESERVED" 6 "Not Used" 7 "Error Indicator" ;
VAL_ 2172674052 AVH_Sta 0 "No apply" 1 "Vehicle is held by the service brake" 2 "Being released" 3 "Error Indicator" ;
VAL_ 2172674052 AVH_Slope_Status 0 "Not Uphill" 1 "Uphill" 2 "RESERVED" 3 "Error Indicator" ;
VAL_ 2172674052 AVH_CluDis 0 "AVH is off" 1 "AUTO HOLD to be deactivated Press Brake Pedal" 2 "Press Brake Pedal to Release AUTO HOLD" 3 "AUTO HOLD cannot be activated Close Door, Hood, Trunk" 4 "AUTO HOLD cannot be activated Close Door, Hood" 5 "AUTO HOLD cannot be deactivated, Close Door" 6 "BDC is activated (ON)" 7 "BDC cannot be activated (OFF)" 8 "0x8~0xFF:RESERVED" 255 "0x8~0xFF:RESERVED" ;
VAL_ 2172674052 LDM_Sta 0 "ESC ready to DBF/AVH (requested by switch)" 1 "ESC can¡¯t perform DBF/AVH (requested by switch)" 2 "Not used" 3 "Error Indicator" ;
VAL_ 2172674052 AVH_AlrmReq 0 "No alarm" 1 "On AVH Activation, Vehicle is not secured and driver is still inside = comfortable tone" 2 "Not used" 3 "Error Indicator" ;
VAL_ 2172674052 AVH_ActvStaLmpDis 0 "Lamp On" 1 "Lamp Off" 2 "Not used" 3 "Error Indicator" ;
VAL_ 2172674052 AVH_LmpDis 0 "AVH Off (Lamp Status" 1 "AVH failure (Lamp Status" 2 "AVH ACTIVE (Lamp Status" 3 "AVH READY (Lamp Status" 4 "Lamp Status" 5 "Lamp Status" 6 "Lamp Status" ;
VAL_ 2172674052 AWD_CrdnShftTqLimVal 65535 "Error" ;
VAL_ 2172674052 EPB_ActvReq 0 "No request" 1 "Release request" 2 "Close request in comfort mode" 3 "Close request in secure mode" ;
VAL_ 2172674052 AWD_CltchDtyLimVal 255 "Error" ;
VAL_ 2172674052 AWD_TransmsnTqLimModSta 0 "Maximum limitation mode" 1 "Minimum limitation mode" 2 "Not used" 3 "Error Indicator" ;
VAL_ 2172674052 AWD_RrWhlDtyLimReq 0 "No request from ESC" 1 "Request duty limit from ESC" 2 "Not used" 3 "Error Indicator" ;
VAL_ 2172674052 EPB_StaReq 0 "REQ_EPB_ACT signal is invalid" 1 "REQ_EPB_ACT signal is valid" 2 "Not used" 3 "Error Indicator" ;
VAL_ 2172674052 AWD_FastOpnCrdnShftCltchReq 0 "Passive" 1 "Clutch off" 2 "Torque limit" 3 "Error" ;
VAL_ 2172674052 ECD_ActvSta 0 "ECD is not active" 1 "ECD is active(operating)" 2 "Not used" 3 "Error Indicator" ;
VAL_ 2172674051 ESC_CylPrsrVal 4095 "Error" ;
VAL_ 2172674051 ESC_CylPrsrSta 0 "Master cylinder pressure signal is invalid" 1 "Master cylinder pressure signal is valid" 2 "Not used" 3 "Error Indicator" ;
VAL_ 2172674051 ESC_CylPrsrDiagSta 0 "Master cylinder pressure is not available temporarily" 1 "Master cylinder pressure signal is available" 2 "Not used" 3 "Error Indicator" ;
VAL_ 2172674051 ESC_CylPrsrFlagSta 0 "Off" 1 "On" 2 "Not used" 3 "Error Indicator" ;
VAL_ 2172674051 ESC_VsmActvSta 0 "VSM control inactive" 1 "VSM control active" 2 "Not used" 3 "Error Indicator" ;
VAL_ 2172674051 ESC_VsmDfctvSta 0 "VSM is not defective" 1 "VSM is defective" 2 "Not used" 3 "Error Indicator" ;
VAL_ 2172674051 ESC_VsmCtrlModSta 0 "Inactive" 1 "Mode 1 (sensor value overlay mode)" 2 "Mode 2 (output torque overlay mode)" 3 "Mode 3 (Particular control)" ;
VAL_ 2172674051 ESC_StrTqReq 4095 "Error" ;
VAL_ 2172674051 TVC_ActSta 0 "Default" 1 "Activated" 2 "RESERVED" 3 "RESERVED" ;
VAL_ 2172674051 ESC_IMURstStaAck 0 "No reset flag received" 1 "Reset flag has been received" ;
VAL_ 967 RCM_Crc2Val 0 "0x0x0~0xFF:CRCValue" 255 "0x0x0~0xFF:CRCValue" ;
VAL_ 967 RCM_AlvCnt2Val 0 "AlvCntValue" 1 "AlvCntValue" 2 "AlvCntValue" 3 "AlvCntValue" 4 "AlvCntValue" 5 "AlvCntValue" 6 "AlvCntValue" 7 "AlvCntValue" 8 "AlvCntValue" 9 "AlvCntValue" 10 "AlvCntValue" 11 "AlvCntValue" 12 "AlvCntValue" 13 "AlvCntValue" 14 "AlvCntValue" 15 "AlvCntValue" ;
VAL_ 967 RCM_SunroofOpnSta 0 "Close" 1 "Open" 2 "Not Used" 3 "Error Indicator" ;
VAL_ 967 RCM_GlsOpSta 0 "No Action" 1 "Opening" 2 "Closing" 3 "Reversing" ;
VAL_ 967 RCM_GlsPosSta 0 "Full Close" 1 "BCT" 2 "TiltUp" 3 "BTO" 4 "BCO" 5 "BTO2(OPT)" 6 "Full Open" 7 "Undefined" 8 "Comfort Open" 9 "RESERVED" 10 "RESERVED" 11 "RESERVED" 12 "RESERVED" 13 "RESERVED" 14 "RESERVED" 15 "Invalid" ;
VAL_ 967 RCM_GlsFltSta 0 "Normal (Initialized)" 1 "Fault" 2 "Not Initialized" 3 "Error Indicator" ;
VAL_ 2172674050 TCS_Sta 0 "Not Applied" 1 "Off" 2 "Ready" 3 "Activated" 4 "Reserved" 5 "Reserved" 6 "Reserved" 7 "Reserved" 8 "Reserved" 9 "Reserved" 10 "Reserved" 11 "Reserved" 12 "Reserved" 13 "Reserved" 14 "Not Coded" 15 "Defective" ;
VAL_ 2172674050 TCS_PreActvSta 0 "-" 1 "Pre TCS Active" 2 "Not used" 3 "Error Indicator" ;
VAL_ 2172674050 DBC_Sta 0 "Not Applied" 1 "Off" 2 "Ready" 3 "Activated" 4 "Reserved" 5 "Reserved" 6 "Reserved" 7 "Reserved" 8 "Reserved" 9 "Reserved" 10 "Reserved" 11 "Reserved" 12 "Reserved" 13 "Reserved" 14 "Not Coded" 15 "Defective" ;
VAL_ 2172674050 TCS_TqFlag 0 "Positive" 1 "Negative" ;
VAL_ 2172674050 MSR_TqFlag 0 "Positive" 1 "Negative" ;
VAL_ 2172674050 HAC_Sta 0 "Not Applied" 1 "Off" 2 "Ready" 3 "Activated" 4 "Reserved" 5 "Reserved" 6 "Reserved" 7 "Reserved" 8 "Reserved" 9 "Reserved" 10 "Reserved" 11 "Reserved" 12 "Reserved" 13 "Reserved" 14 "Not Coded" 15 "Defective" ;
VAL_ 2172674050 BJD_Flag 0 "No Event" 1 "Event" ;
VAL_ 2172674050 TCS_SlwTqFlag 0 "Positive" 1 "Negative" ;
VAL_ 2172674050 TCS_Req 0 "Passive" 1 "TCS/ESC control active" 2 "Not used" 3 "Error Indicator" ;
VAL_ 2172674050 MSR_FuncReq 0 "Passive or TCS function" 1 "MSR control active" 2 "Not used" 3 "Error Indicator" ;
VAL_ 2172674050 TCS_GearShftCharacteristicVal 0 "passive (gear change allowed)" 1 "active (gear change not allowed)" 2 "Not used" 3 "Error Indicator" ;
VAL_ 2172674050 TCS_ManufacturerVal 0 "Using both TQI_TCS and TQI_SLW_TCS" 1 "Using TQI_TCS only (Not using TQI_SLW_TCS)" 2 "Not used" 3 "Error Indicator" ;
VAL_ 2172674050 ESC_Sta 0 "Not Applied" 1 "Off" 2 "Ready" 3 "Activated" 4 "Reserved" 5 "Reserved" 6 "Reserved" 7 "Reserved" 8 "Reserved" 9 "Reserved" 10 "Reserved" 11 "Reserved" 12 "Reserved" 13 "Reserved" 14 "Not Coded" 15 "Defective" ;
VAL_ 966 RCM_Crc1Val 0 "0x0x0~0xFF:CRCValue" 255 "0x0x0~0xFF:CRCValue" ;
VAL_ 966 RCM_AlvCnt1Val 0 "AlvCntValue" 1 "AlvCntValue" 2 "AlvCntValue" 3 "AlvCntValue" 4 "AlvCntValue" 5 "AlvCntValue" 6 "AlvCntValue" 7 "AlvCntValue" 8 "AlvCntValue" 9 "AlvCntValue" 10 "AlvCntValue" 11 "AlvCntValue" 12 "AlvCntValue" 13 "AlvCntValue" 14 "AlvCntValue" 15 "AlvCntValue" ;
VAL_ 966 RCM_OptTyp 0 "None" 1 "FR Glass (Normal Sunroof)" 2 "FR Glass+FR Blind (Panorama Roof)" 3 "FR Glass+FR Blind+RR Blind (Panorama with Rear Blind)" 4 "FR Glass+RR Glass (Dual Normal Sunroof)" 5 "FR Blind (Vision Roof)" 6 "FR Glass+RR Blind (Dual Sunroof and Rear Blind)" 7 "Reserved" 8 "Reserved" 9 "Reserved" 10 "Reserved" 11 "Reserved" 12 "Reserved" 13 "Reserved" 14 "Reserved" 15 "Invalid" ;
VAL_ 966 RCM_TunnelOptType 0 "Not Support" 1 "Support" 2 "Invalid" ;
VAL_ 2172674049 ESC_Crc1Val 0 "0x0x0~0xFFFF:CRCValue" 65535 "0x0x0~0xFFFF:CRCValue" ;
VAL_ 2172674049 ESC_AlvCnt1Val 0 "0x0x0~0xFF:AlvCntValue" 255 "0x0x0~0xFF:AlvCntValue" ;
VAL_ 2172674049 ESC_CltchPdStrkSnsrDuty 0 "0x0x00~0x64:ClutchPedalStrokeSensorDuty (%)" 100 "0x0x00~0x64:ClutchPedalStrokeSensorDuty (%)" 101 "0x65~0xFF:RESERVED" 255 "0x65~0xFF:RESERVED" ;
VAL_ 2172674049 TCS_LmpSta 0 "TCS/ESC Function/Warning Lamp OFF" 1 "TCS/ESC Function/Warning Lamp ON" 2 "TCS/ESC Function/Warning Lamp BLINKING(2Hz)" 3 "Error Indicator" ;
VAL_ 2172674049 TCS_OffLmpSta 0 "TCS/ESC OFF SW Lamp OFF" 1 "TCS/ESC OFF SW Lamp ON" 2 "Not used" 3 "Error Indicator" ;
VAL_ 2172674049 ESC_OffTempSta 0 "Normal Mode" 1 "Sports Mode" 2 "Off Mode" 3 "ESC OFF SW is defective (failed)" ;
VAL_ 2172674049 ESC_OffSwSta 0 "Not Pressed" 1 "Pressed" 2 "Not used" 3 "Not used" ;
VAL_ 2172674049 DBC_WrngLmpSta 0 "DBC Warning lamp OFF" 1 "DBC Warning lamp ON" 2 "Not used" 3 "Error Indicator" ;
VAL_ 2172674049 DBC_FuncLmpSta 0 "DBC Function lamp OFF" 1 "DBC Function lamp ON" 2 "DBC Function lamp BLINKING(2Hz)" 3 "Error Indicator" ;
VAL_ 2172674049 DBC_ClusterDis 0 "DBC Enabled" 1 "DBC Disabled by system fault" 2 "Reserved" 3 "Reserved" ;
VAL_ 2172674049 ESC_SprtLmpSta 0 "ESC Sport Lamp OFF" 1 "ESC Sport Lamp ON" 2 "Reserved" 3 "Reserved" ;
VAL_ 2172674049 ESC_BrkCtrlSta 0 "Brake control is not in activation" 1 "Brake control is in activation" 2 "Not used" 3 "Error Indicator" ;
VAL_ 2172674049 ESC_MyDrive_CodingSta 0 "Not used" 1 "Case1 (Brake ECU control for itself)" 2 "Case2 (Referring to ICSC)" 3 "Not Coded" ;
VAL_ 2172674049 ESC_OffSwSta2 0 "SW Off" 1 "Short Click" 2 "Long Click" 3 "ESC Off SW is defective (failed)" ;
VAL_ 1301 Destination_WPC2 0 "0x0x0~0xFF:NM Source Node ID" 255 "0x0x0~0xFF:NM Source Node ID" ;
VAL_ 1301 NMCommandCode_WPC2 1 "Alive" 2 "Ring" 3 "RESERVED" 4 "Limphome" 5 "RESERVED" 6 "RESERVED" 7 "RESERVED" ;
VAL_ 1301 NMSleepFlag_WPC2 0 "Alive" 1 "SleepInd" 2 "RESERVED" 3 "SleepAck" ;
VAL_ 1345 Destination_PSB 0 "0x0x0~0xFF:NM Source Node ID" 255 "0x0x0~0xFF:NM Source Node ID" ;
VAL_ 1345 NMCommandCode_PSB 1 "Alive" 2 "Ring" 3 "RESERVED" 4 "Limphome" 5 "RESERVED" 6 "RESERVED" 7 "RESERVED" ;
VAL_ 1345 NMSleepFlag_PSB 0 "Alive" 1 "SleepInd" 2 "RESERVED" 3 "SleepAck" ;
VAL_ 1323 Destination_SHVU_RR 0 "0x0x0~0xFF:NM Source Node ID" 255 "0x0x0~0xFF:NM Source Node ID" ;
VAL_ 1323 NMCommandCode_SHVU_RR 1 "Alive" 2 "Ring" 3 "RESERVED" 4 "Limphome" 5 "RESERVED" 6 "RESERVED" 7 "RESERVED" ;
VAL_ 1323 NMSleepFlag_SHVU_RR 0 "Alive" 1 "SleepInd" 2 "RESERVED" 3 "SleepAck" ;
VAL_ 1313 Destination_FCS 0 "0x0x0~0xFF:NM Source Node ID" 255 "0x0x0~0xFF:NM Source Node ID" ;
VAL_ 1313 NMCommandCode_FCS 1 "Alive" 2 "Ring" 3 "RESERVED" 4 "Limphome" 5 "RESERVED" 6 "RESERVED" 7 "RESERVED" ;
VAL_ 1313 NMSleepFlag_FCS 0 "Alive" 1 "SleepInd" 2 "RESERVED" 3 "SleepAck" ;
VAL_ 1297 Destination_EMCU 0 "0x0x0~0xFF:NM Source Node ID" 255 "0x0x0~0xFF:NM Source Node ID" ;
VAL_ 1297 NMCommandCode_EMCU 1 "Alive" 2 "Ring" 3 "RESERVED" 4 "Limphome" 5 "RESERVED" 6 "RESERVED" 7 "RESERVED" ;
VAL_ 1297 NMSleepFlag_EMCU 0 "Alive" 1 "SleepInd" 2 "RESERVED" 3 "SleepAck" ;
VAL_ 1307 Destination_SLB 0 "0x0x0~0xFF:NM Source Node ID" 255 "0x0x0~0xFF:NM Source Node ID" ;
VAL_ 1307 NMCommandCode_SLB 1 "Alive" 2 "Ring" 3 "RESERVED" 4 "Limphome" 5 "RESERVED" 6 "RESERVED" 7 "RESERVED" ;
VAL_ 1307 NMSleepFlag_SLB 0 "Alive" 1 "SleepInd" 2 "RESERVED" 3 "SleepAck" ;
VAL_ 1329 Destination_GW_APSU 0 "0x0x0~0xFF:NM Source Node ID" 255 "0x0x0~0xFF:NM Source Node ID" ;
VAL_ 1329 NMCommandCode_GW_APSU 1 "Alive" 2 "Ring" 3 "RESERVED" 4 "Limphome" 5 "RESERVED" 6 "RESERVED" 7 "RESERVED" ;
VAL_ 1329 NMSleepFlag_GW_APSU 0 "Alive" 1 "SleepInd" 2 "RESERVED" 3 "SleepAck" ;
VAL_ 1344 Destination_GW_DLBCU 0 "0x0x0~0xFF:NM Source Node ID" 255 "0x0x0~0xFF:NM Source Node ID" ;
VAL_ 1344 NMCommandCode_GW_DLBCU 1 "Alive" 2 "Ring" 3 "RESERVED" 4 "Limphome" 5 "RESERVED" 6 "RESERVED" 7 "RESERVED" ;
VAL_ 1344 NMSleepFlag_GW_DLBCU 0 "Alive" 1 "SleepInd" 2 "RESERVED" 3 "SleepAck" ;
VAL_ 1341 Destination_RCM 0 "0x0x0~0xFF:NM Source Node ID" 255 "0x0x0~0xFF:NM Source Node ID" ;
VAL_ 1341 NMCommandCode_RCM 1 "Alive" 2 "Ring" 3 "RESERVED" 4 "Limphome" 5 "RESERVED" 6 "RESERVED" 7 "RESERVED" ;
VAL_ 1341 NMSleepFlag_RCM 0 "Alive" 1 "SleepInd" 2 "RESERVED" 3 "SleepAck" ;
VAL_ 1290 Destination_ARS 0 "0x0x0~0xFF:NM Source Node ID" 255 "0x0x0~0xFF:NM Source Node ID" ;
VAL_ 1290 NMCommandCode_ARS 1 "Alive" 2 "Ring" 3 "RESERVED" 4 "Limphome" 5 "RESERVED" 6 "RESERVED" 7 "RESERVED" ;
VAL_ 1290 NMSleepFlag_ARS 0 "Alive" 1 "SleepInd" 2 "RESERVED" 3 "SleepAck" ;
VAL_ 1392 Destination_CGW_CCU 0 "0x0x0~0xFF:NM Source Node ID" 255 "0x0x0~0xFF:NM Source Node ID" ;
VAL_ 1392 NMCommandCode_CGW_CCU 1 "Alive" 2 "Ring" 3 "RESERVED" 4 "Limphome" 5 "RESERVED" 6 "RESERVED" 7 "RESERVED" ;
VAL_ 1392 NMSleepFlag_CGW_CCU 0 "Alive" 1 "SleepInd" 2 "RESERVED" 3 "SleepAck" ;
VAL_ 1308 Destination_GW_RLPSU 0 "0x0x0~0xFF:NM Source Node ID" 255 "0x0x0~0xFF:NM Source Node ID" ;
VAL_ 1308 NMCommandCode_GW_RLPSU 1 "Alive" 2 "Ring" 3 "RESERVED" 4 "Limphome" 5 "RESERVED" 6 "RESERVED" 7 "RESERVED" ;
VAL_ 1308 NMSleepFlag_GW_RLPSU 0 "Alive" 1 "SleepInd" 2 "RESERVED" 3 "SleepAck" ;
VAL_ 1360 Destination_ATS 0 "0x0x0~0xFF:NM Source Node ID" 255 "0x0x0~0xFF:NM Source Node ID" ;
VAL_ 1360 NMCommandCode_ATS 1 "Alive" 2 "Ring" 3 "RESERVED" 4 "Limphome" 5 "RESERVED" 6 "RESERVED" 7 "RESERVED" ;
VAL_ 1360 NMSleepFlag_ATS 0 "Alive" 1 "SleepInd" 2 "RESERVED" 3 "SleepAck" ;
VAL_ 1332 Destination_RLHV 0 "0x0x0~0xFF:NM Source Node ID" 255 "0x0x0~0xFF:NM Source Node ID" ;
VAL_ 1332 NMCommandCode_RLHV 1 "Alive" 2 "Ring" 3 "RESERVED" 4 "Limphome" 5 "RESERVED" 6 "RESERVED" 7 "RESERVED" ;
VAL_ 1332 NMSleepFlag_RLHV 0 "Alive" 1 "SleepInd" 2 "RESERVED" 3 "SleepAck" ;
VAL_ 1342 Destination_SGU 0 "0x0x0~0xFF:NM Source Node ID" 255 "0x0x0~0xFF:NM Source Node ID" ;
VAL_ 1342 NMCommandCode_SGU 1 "Alive" 2 "Ring" 3 "RESERVED" 4 "Limphome" 5 "RESERVED" 6 "RESERVED" 7 "RESERVED" ;
VAL_ 1342 NMSleepFlag_SGU 0 "Alive" 1 "SleepInd" 2 "RESERVED" 3 "SleepAck" ;
VAL_ 1325 Destination_PFSU 0 "0x0x0~0xFF:NM Source Node ID" 255 "0x0x0~0xFF:NM Source Node ID" ;
VAL_ 1325 NMCommandCode_PFSU 1 "Alive" 2 "Ring" 3 "RESERVED" 4 "Limphome" 5 "RESERVED" 6 "RESERVED" 7 "RESERVED" ;
VAL_ 1325 NMSleepFlag_PFSU 0 "Alive" 1 "SleepInd" 2 "RESERVED" 3 "SleepAck" ;
VAL_ 1309 Destination_GW_RRPSU 0 "0x0x0~0xFF:NM Source Node ID" 255 "0x0x0~0xFF:NM Source Node ID" ;
VAL_ 1309 NMCommandCode_GW_RRPSU 1 "Alive" 2 "Ring" 3 "RESERVED" 4 "Limphome" 5 "RESERVED" 6 "RESERVED" 7 "RESERVED" ;
VAL_ 1309 NMSleepFlag_GW_RRPSU 0 "Alive" 1 "SleepInd" 2 "RESERVED" 3 "SleepAck" ;
VAL_ 1348 Destination_ALBCU 0 "0x0x0~0xFF:NM Source Node ID" 255 "0x0x0~0xFF:NM Source Node ID" ;
VAL_ 1348 NMCommandCode_ALBCU 1 "Alive" 2 "Ring" 3 "RESERVED" 4 "Limphome" 5 "RESERVED" 6 "RESERVED" 7 "RESERVED" ;
VAL_ 1348 NMSleepFlag_ALBCU 0 "Alive" 1 "SleepInd" 2 "RESERVED" 3 "SleepAck" ;
VAL_ 1369 Destination_DSAU 0 "0x0x0~0xFF:NM Source Node ID" 255 "0x0x0~0xFF:NM Source Node ID" ;
VAL_ 1369 NMCommandCode_DSAU 1 "Alive" 2 "Ring" 3 "RESERVED" 4 "Limphome" 5 "RESERVED" 6 "RESERVED" 7 "RESERVED" ;
VAL_ 1369 NMSleepFlag_DSAU 0 "Alive" 1 "SleepInd" 2 "RESERVED" 3 "SleepAck" ;
VAL_ 1288 Destination_SWRC 0 "0x0x0~0xFF:NM Source Node ID" 255 "0x0x0~0xFF:NM Source Node ID" ;
VAL_ 1288 NMCommandCode_SWRC 1 "Alive" 2 "Ring" 3 "RESERVED" 4 "Limphome" 5 "RESERVED" 6 "RESERVED" 7 "RESERVED" ;
VAL_ 1288 NMSleepFlag_SWRC 0 "Alive" 1 "SleepInd" 2 "RESERVED" 3 "SleepAck" ;
VAL_ 1322 Destination_SHVU_FR 0 "0x0x0~0xFF:NM Source Node ID" 255 "0x0x0~0xFF:NM Source Node ID" ;
VAL_ 1322 NMCommandCode_SHVU_FR 1 "Alive" 2 "Ring" 3 "RESERVED" 4 "Limphome" 5 "RESERVED" 6 "RESERVED" 7 "RESERVED" ;
VAL_ 1322 NMSleepFlag_SHVU_FR 0 "Alive" 1 "SleepInd" 2 "RESERVED" 3 "SleepAck" ;
VAL_ 1350 Destination_RCS 0 "0x0x0~0xFF:NM Source Node ID" 255 "0x0x0~0xFF:NM Source Node ID" ;
VAL_ 1350 NMCommandCode_RCS 1 "Alive" 2 "Ring" 3 "RESERVED" 4 "Limphome" 5 "RESERVED" 6 "RESERVED" 7 "RESERVED" ;
VAL_ 1350 NMSleepFlag_RCS 0 "Alive" 1 "SleepInd" 2 "RESERVED" 3 "SleepAck" ;
VAL_ 1336 Destination_GW_DPSU 0 "0x0x0~0xFF:NM Source Node ID" 255 "0x0x0~0xFF:NM Source Node ID" ;
VAL_ 1336 NMCommandCode_GW_DPSU 1 "Alive" 2 "Ring" 3 "RESERVED" 4 "Limphome" 5 "RESERVED" 6 "RESERVED" 7 "RESERVED" ;
VAL_ 1336 NMSleepFlag_GW_DPSU 0 "Alive" 1 "SleepInd" 2 "RESERVED" 3 "SleepAck" ;
VAL_ 1352 Destination_BLTN_CAM 0 "0x0x0~0xFF:NM Source Node ID" 255 "0x0x0~0xFF:NM Source Node ID" ;
VAL_ 1352 NMCommandCode_BLTN_CAM 1 "Alive" 2 "Ring" 3 "RESERVED" 4 "Limphome" 5 "RESERVED" 6 "RESERVED" 7 "RESERVED" ;
VAL_ 1352 NMSleepFlag_BLTN_CAM 0 "Alive" 1 "SleepInd" 2 "RESERVED" 3 "SleepAck" ;
VAL_ 1287 Destination_SCM 0 "0x0x0~0xFF:NM Source Node ID" 255 "0x0x0~0xFF:NM Source Node ID" ;
VAL_ 1287 NMCommandCode_SCM 1 "Alive" 2 "Ring" 3 "RESERVED" 4 "Limphome" 5 "RESERVED" 6 "RESERVED" 7 "RESERVED" ;
VAL_ 1287 NMSleepFlag_SCM 0 "Alive" 1 "SleepInd" 2 "RESERVED" 3 "SleepAck" ;
VAL_ 1364 Destination_OHCL 0 "0x0x0~0xFF:NM Source Node ID" 255 "0x0x0~0xFF:NM Source Node ID" ;
VAL_ 1364 NMCommandCode_OHCL 1 "Alive" 2 "Ring" 3 "RESERVED" 4 "Limphome" 5 "RESERVED" 6 "RESERVED" 7 "RESERVED" ;
VAL_ 1364 NMSleepFlag_OHCL 0 "Alive" 1 "SleepInd" 2 "RESERVED" 3 "SleepAck" ;
VAL_ 1311 Destination_RWPC 0 "0x0x0~0xFF:NM Source Node ID" 255 "0x0x0~0xFF:NM Source Node ID" ;
VAL_ 1311 NMCommandCode_RWPC 1 "Alive" 2 "Ring" 3 "RESERVED" 4 "Limphome" 5 "RESERVED" 6 "RESERVED" 7 "RESERVED" ;
VAL_ 1311 NMSleepFlag_RWPC 0 "Alive" 1 "SleepInd" 2 "RESERVED" 3 "SleepAck" ;
VAL_ 1333 Destination_RRHV 0 "0x0x0~0xFF:NM Source Node ID" 255 "0x0x0~0xFF:NM Source Node ID" ;
VAL_ 1333 NMCommandCode_RRHV 1 "Alive" 2 "Ring" 3 "RESERVED" 4 "Limphome" 5 "RESERVED" 6 "RESERVED" 7 "RESERVED" ;
VAL_ 1333 NMSleepFlag_RRHV 0 "Alive" 1 "SleepInd" 2 "RESERVED" 3 "SleepAck" ;
VAL_ 1310 Destination_WPC 0 "0x0x0~0xFF:NM Source Node ID" 255 "0x0x0~0xFF:NM Source Node ID" ;
VAL_ 1310 NMCommandCode_WPC 1 "Alive" 2 "Ring" 3 "RESERVED" 4 "Limphome" 5 "RESERVED" 6 "RESERVED" 7 "RESERVED" ;
VAL_ 1310 NMSleepFlag_WPC 0 "Alive" 1 "SleepInd" 2 "RESERVED" 3 "SleepAck" ;
VAL_ 1354 Destination_HOD 0 "0x0x0~0xFF:NM Source Node ID" 255 "0x0x0~0xFF:NM Source Node ID" ;
VAL_ 1354 NMCommandCode_HOD 1 "Alive" 2 "Ring" 3 "RESERVED" 4 "Limphome" 5 "RESERVED" 6 "RESERVED" 7 "RESERVED" ;
VAL_ 1354 NMSleepFlag_HOD 0 "Alive" 1 "SleepInd" 2 "RESERVED" 3 "SleepAck" ;
VAL_ 1363 Destination_ASAU 0 "0x0x0~0xFF:NM Source Node ID" 255 "0x0x0~0xFF:NM Source Node ID" ;
VAL_ 1363 NMCommandCode_ASAU 1 "Alive" 2 "Ring" 3 "RESERVED" 4 "Limphome" 5 "RESERVED" 6 "RESERVED" 7 "RESERVED" ;
VAL_ 1363 NMSleepFlag_ASAU 0 "Alive" 1 "SleepInd" 2 "RESERVED" 3 "SleepAck" ;
